VERSION "dbc-export 1 2026.26.6.5"

NS_ :

BS_:

BU_: ADSP APSB CMP DAS EPAS3P GTW OCS1P PTC RCM TCU TCU2 TRCM UDS UI UIS VCLEFT

BO_ 2033 GTW_hrl: 7 GTW
 SG_ GTW_hrlIndex M : 0|2@1+ (1,0) [0|3] "" Vector__XXX
 SG_ GTW_hrlPagesCount m1 : 15|32@0+ (1,0) [0|4294967295] "" Vector__XXX
 SG_ GTW_hrlSdCardSizeGB m1 : 40|8@1+ (1,0) [1|255] "" Vector__XXX
 SG_ GTW_hrlState m2 : 2|1@1+ (1,0) [0|1] "" Vector__XXX
 SG_ GTW_hrlTriggerDuration m2 : 15|16@0+ (1,0) [0|65535] "seconds" Vector__XXX
 SG_ GTW_hrlTriggerType m2 : 24|4@1+ (1,0) [0|15] "" Vector__XXX
 SG_ GTW_hrlTriggerId m2 : 39|16@0+ (1,0) [0|65535] "" Vector__XXX
 SG_ GTW_hrlTriggerBus m2 : 53|3@1+ (1,0) [0|7] "" Vector__XXX

BO_ 2026 GTW_hrlExternalEvent: 8 GTW
 SG_ GTW_hrlEventStartEpoch : 7|32@0+ (1,0) [0|4294967295] "seconds" Vector__XXX
 SG_ GTW_hrlEventEndEpoch : 39|32@0+ (1,0) [0|4294967295] "seconds" Vector__XXX

BO_ 60 GTW_info: 8 GTW
 SG_ GTW_infoIndex M : 0|8@1+ (1,0) [0|255] "" Vector__XXX
 SG_ GTW_buildType m10 : 8|3@1+ (1,0) [0|7] "" Vector__XXX
 SG_ GTW_hardwareId m10 : 32|16@1+ (1,0) [0|65535] "" Vector__XXX
 SG_ GTW_platformType m13 : 8|8@1+ (1,0) [0|255] "" Vector__XXX
 SG_ GTW_appCrc m13 : 32|32@1+ (1,0) [0|4294967295] "" Vector__XXX
 SG_ GTW_applicationGitHash m17 : 8|56@1+ (1,0) [0|7.20575940379e+16] "" Vector__XXX
 SG_ GTW_bootGitHash m18 : 8|56@1+ (1,0) [0|7.20575940379e+16] "" Vector__XXX

BO_ 1370 GTW_mismatchFault: 8 GTW
 SG_ GTW_mismatchFaultIndex M : 0|3@1+ (1,0) [0|7] "" Vector__XXX
 SG_ GTW_mismatchFaultChecksum : 3|8@1+ (1,0) [0|255] "" Vector__XXX
 SG_ GTW_mismatchFaultCounter : 11|4@1+ (1,0) [0|15] "" Vector__XXX
 SG_ GTW_GTWmismatchFault m1 : 15|1@1+ (1,0) [0|1] "" Vector__XXX
 SG_ GTW_BMSmismatchFault m1 : 16|1@1+ (1,0) [0|1] "" Vector__XXX
 SG_ GTW_APSmismatchFault m1 : 17|1@1+ (1,0) [0|1] "" Vector__XXX
 SG_ GTW_BLEEPCENTERmismatchFault m1 : 18|1@1+ (1,0) [0|1] "" Vector__XXX
 SG_ GTW_BLEEPLEFTmismatchFault m1 : 19|1@1+ (1,0) [0|1] "" Vector__XXX
 SG_ GTW_BLEEPREARmismatchFault m1 : 20|1@1+ (1,0) [0|1] "" Vector__XXX
 SG_ GTW_BLEEPRIGHTmismatchFault m1 : 21|1@1+ (1,0) [0|1] "" Vector__XXX
 SG_ GTW_CBCmismatchFault m1 : 22|1@1+ (1,0) [0|1] "" Vector__XXX
 SG_ GTW_CMPmismatchFault m1 : 23|1@1+ (1,0) [0|1] "" Vector__XXX
 SG_ GTW_CPmismatchFault m1 : 24|1@1+ (1,0) [0|1] "" Vector__XXX
 SG_ GTW_DIFmismatchFault m1 : 25|1@1+ (1,0) [0|1] "" Vector__XXX
 SG_ GTW_DIRmismatchFault m1 : 26|1@1+ (1,0) [0|1] "" Vector__XXX
 SG_ GTW_EPAS3PmismatchFault m1 : 27|1@1+ (1,0) [0|1] "" Vector__XXX
 SG_ GTW_EPAS3SmismatchFault m1 : 28|1@1+ (1,0) [0|1] "" Vector__XXX
 SG_ GTW_EPBLmismatchFault m1 : 29|1@1+ (1,0) [0|1] "" Vector__XXX
 SG_ GTW_EPBRmismatchFault m1 : 30|1@1+ (1,0) [0|1] "" Vector__XXX
 SG_ GTW_ESPCALmismatchFault m1 : 31|1@1+ (1,0) [0|1] "" Vector__XXX
 SG_ GTW_ESPmismatchFault m1 : 32|1@1+ (1,0) [0|1] "" Vector__XXX
 SG_ GTW_HCM3LmismatchFault m1 : 33|1@1+ (1,0) [0|1] "" Vector__XXX
 SG_ GTW_HCM3RmismatchFault m1 : 34|1@1+ (1,0) [0|1] "" Vector__XXX
 SG_ GTW_HCMLmismatchFault m1 : 35|1@1+ (1,0) [0|1] "" Vector__XXX
 SG_ GTW_HCMRmismatchFault m1 : 36|1@1+ (1,0) [0|1] "" Vector__XXX
 SG_ GTW_HVPmismatchFault m1 : 37|1@1+ (1,0) [0|1] "" Vector__XXX
 SG_ GTW_IBSTCALmismatchFault m1 : 38|1@1+ (1,0) [0|1] "" Vector__XXX
 SG_ GTW_IBSTmismatchFault m1 : 39|1@1+ (1,0) [0|1] "" Vector__XXX
 SG_ GTW_LVBMSmismatchFault m1 : 40|1@1+ (1,0) [0|1] "" Vector__XXX
 SG_ GTW_OCS1PmismatchFault m1 : 41|1@1+ (1,0) [0|1] "" Vector__XXX
 SG_ GTW_OPCFmismatchFault m1 : 42|1@1+ (1,0) [0|1] "" Vector__XXX
 SG_ GTW_OPCRmismatchFault m1 : 43|1@1+ (1,0) [0|1] "" Vector__XXX
 SG_ GTW_PARKmismatchFault m1 : 44|1@1+ (1,0) [0|1] "" Vector__XXX
 SG_ GTW_PCSCPU2mismatchFault m1 : 45|1@1+ (1,0) [0|1] "" Vector__XXX
 SG_ GTW_PCSmismatchFault m1 : 46|1@1+ (1,0) [0|1] "" Vector__XXX
 SG_ GTW_PMFmismatchFault m1 : 47|1@1+ (1,0) [0|1] "" Vector__XXX
 SG_ GTW_PMRmismatchFault m1 : 48|1@1+ (1,0) [0|1] "" Vector__XXX
 SG_ GTW_PTCmismatchFault m1 : 49|1@1+ (1,0) [0|1] "" Vector__XXX
 SG_ GTW_RCMCALmismatchFault m1 : 50|1@1+ (1,0) [0|1] "" Vector__XXX
 SG_ GTW_RCMmismatchFault m1 : 51|1@1+ (1,0) [0|1] "" Vector__XXX
 SG_ GTW_SCCMmismatchFault m1 : 52|1@1+ (1,0) [0|1] "" Vector__XXX
 SG_ GTW_SDCRmismatchFault m1 : 53|1@1+ (1,0) [0|1] "" Vector__XXX
 SG_ GTW_SWCmismatchFault m1 : 54|1@1+ (1,0) [0|1] "" Vector__XXX
 SG_ GTW_THSmismatchFault m1 : 55|1@1+ (1,0) [0|1] "" Vector__XXX
 SG_ GTW_VCFRONTmismatchFault m1 : 56|1@1+ (1,0) [0|1] "" Vector__XXX
 SG_ GTW_VCLEFTmismatchFault m1 : 57|1@1+ (1,0) [0|1] "" Vector__XXX
 SG_ GTW_VCRIGHTmismatchFault m1 : 58|1@1+ (1,0) [0|1] "" Vector__XXX
 SG_ GTW_VCSECmismatchFault m1 : 59|1@1+ (1,0) [0|1] "" Vector__XXX
 SG_ GTW_PMmismatchFault m1 : 60|1@1+ (1,0) [0|1] "" Vector__XXX

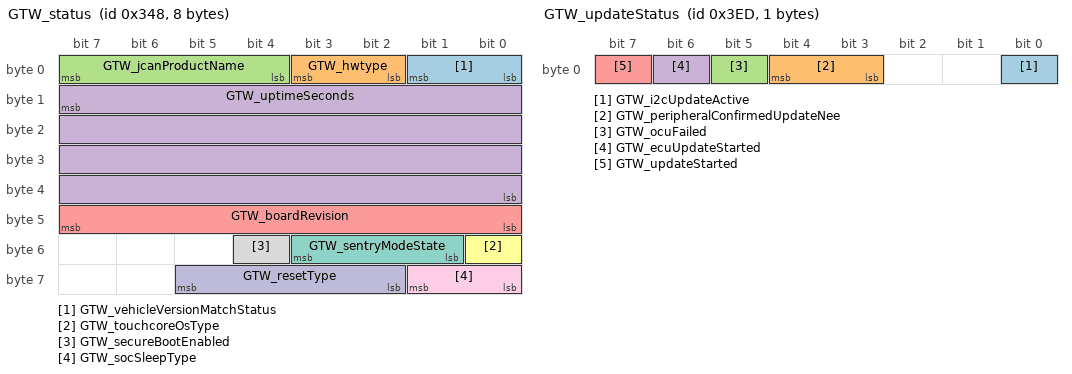
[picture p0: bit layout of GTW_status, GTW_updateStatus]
BO_ 840 GTW_status: 8 GTW
 SG_ GTW_vehicleVersionMatchStatus : 0|2@1+ (1,0) [0|3] "" Vector__XXX
 SG_ GTW_hwtype : 2|2@1+ (1,0) [1|3] "" Vector__XXX
 SG_ GTW_jcanProductName : 4|4@1+ (1,0) [1|15] "" Vector__XXX
 SG_ GTW_uptimeSeconds : 15|32@0+ (1,0) [0|4294967295] "s" Vector__XXX
 SG_ GTW_boardRevision : 40|8@1+ (1,0) [0|255] "" Vector__XXX
 SG_ GTW_touchcoreOsType : 48|1@1+ (1,0) [0|1] "" Vector__XXX
 SG_ GTW_sentryModeState : 49|3@1+ (1,0) [0|7] "" Vector__XXX
 SG_ GTW_secureBootEnabled : 52|1@1+ (1,0) [0|1] "" Vector__XXX
 SG_ GTW_socSleepType : 56|2@1+ (1,0) [1|3] "" Vector__XXX
 SG_ GTW_resetType : 58|4@1+ (1,0) [1|15] "" Vector__XXX

BO_ 1005 GTW_updateStatus: 1 GTW
 SG_ GTW_i2cUpdateActive : 0|1@1+ (1,0) [0|1] "" Vector__XXX
 SG_ GTW_peripheralConfirmedUpdateNee : 3|2@1+ (1,0) [0|3] "" Vector__XXX
 SG_ GTW_ocuFailed : 5|1@1+ (1,0) [0|1] "" Vector__XXX
 SG_ GTW_ecuUpdateStarted : 6|1@1+ (1,0) [0|1] "" Vector__XXX
 SG_ GTW_updateStarted : 7|1@1+ (1,0) [0|1] "" Vector__XXX

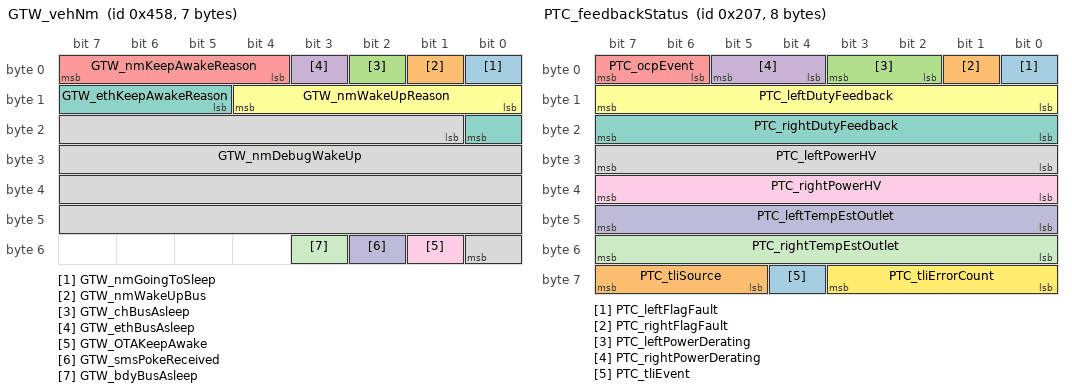
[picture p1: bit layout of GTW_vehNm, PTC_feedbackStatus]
BO_ 1112 GTW_vehNm: 7 GTW
 SG_ GTW_nmGoingToSleep : 0|1@1+ (1,0) [0|1] "" Vector__XXX
 SG_ GTW_nmWakeUpBus : 1|1@1+ (1,0) [0|1] "" Vector__XXX
 SG_ GTW_chBusAsleep : 2|1@1+ (1,0) [0|1] "" Vector__XXX
 SG_ GTW_ethBusAsleep : 3|1@1+ (1,0) [0|1] "" Vector__XXX
 SG_ GTW_nmKeepAwakeReason : 4|4@1+ (1,0) [1|15] "" Vector__XXX
 SG_ GTW_nmWakeUpReason : 8|5@1+ (1,0) [0|31] "" Vector__XXX
 SG_ GTW_ethKeepAwakeReason : 13|4@1+ (1,0) [1|15] "" Vector__XXX
 SG_ GTW_nmDebugWakeUp : 17|32@1+ (1,0) [0|4294967295] "" Vector__XXX
 SG_ GTW_OTAKeepAwake : 49|1@1+ (1,0) [0|1] "" Vector__XXX
 SG_ GTW_smsPokeReceived : 50|1@1+ (1,0) [0|1] "" Vector__XXX
 SG_ GTW_bdyBusAsleep : 51|1@1+ (1,0) [0|1] "" Vector__XXX

BO_ 1429 OCS1P_alertLog: 8 OCS1P
 SG_ OCS1P_alertID M : 0|8@1+ (1,0) [0|255] "" Vector__XXX
 SG_ OCS1P_alertState : 15|1@1+ (1,0) [0|1] "" Vector__XXX
 SG_ OCS1P_a121_sandwichFreq m121 : 16|32@1+ (1,0) [0|4294967295] "" Vector__XXX
 SG_ OCS1P_a122_sandwichFreq m122 : 16|32@1+ (1,0) [0|4294967295] "" Vector__XXX
 SG_ OCS1P_a123_sandwichFreq m123 : 16|32@1+ (1,0) [0|4294967295] "" Vector__XXX
 SG_ OCS1P_a124_cushionSelfFreq m124 : 16|32@1+ (1,0) [0|4294967295] "" Vector__XXX
 SG_ OCS1P_a125_cushionSelfFreq m125 : 16|32@1+ (1,0) [0|4294967295] "" Vector__XXX
 SG_ OCS1P_a126_cushionSelfFreq m126 : 16|32@1+ (1,0) [0|4294967295] "" Vector__XXX
 SG_ OCS1P_a127_seatbackSelfFreq m127 : 16|32@1+ (1,0) [0|4294967295] "" Vector__XXX
 SG_ OCS1P_a128_seatbackSelfFreq m128 : 16|32@1+ (1,0) [0|4294967295] "" Vector__XXX
 SG_ OCS1P_a129_seatbackSelfFreq m129 : 16|32@1+ (1,0) [0|4294967295] "" Vector__XXX
 SG_ OCS1P_a130_sandwichNoCalib m130 : 16|1@1+ (1,0) [0|1] "" Vector__XXX
 SG_ OCS1P_a131_cushionSelfNoCalib m131 : 16|1@1+ (1,0) [0|1] "" Vector__XXX
 SG_ OCS1P_a132_seatbackSelfNoCalib m132 : 16|1@1+ (1,0) [0|1] "" Vector__XXX
 SG_ OCS1P_a133_sandwichBadCalib m133 : 16|1@1+ (1,0) [0|1] "" Vector__XXX
 SG_ OCS1P_a134_uninitializedCalib m134 : 16|1@1+ (1,0) [0|1] "" Vector__XXX
 SG_ OCS1P_a135_tempNoCalib m135 : 16|1@1+ (1,0) [0|1] "" Vector__XXX
 SG_ OCS1P_a140_tempInvalidCalib m140 : 16|1@1+ (1,0) [0|1] "" Vector__XXX
 SG_ OCS1P_a141_humidityInvalidCalib m141 : 16|1@1+ (1,0) [0|1] "" Vector__XXX
 SG_ OCS1P_a142_tempHumidityInvalid m142 : 16|1@1+ (1,0) [0|1] "" Vector__XXX
 SG_ OCS1P_a143_mismatchPassAirbag m143 : 16|1@1+ (1,0) [0|1] "" Vector__XXX
 SG_ OCS1P_a144_mismatchCarRegion m144 : 16|1@1+ (1,0) [0|1] "" Vector__XXX

BO_ 767 OCS1P_alertMatrix: 8 OCS1P
 SG_ OCS1P_matrixIndex M : 0|4@1+ (1,0) [0|15] "" Vector__XXX
 SG_ OCS1P_w015_NVMMAlert m0 : 18|1@1+ (1,0) [0|1] "" Vector__XXX
 SG_ OCS1P_w121_sandwichOpen m2 : 4|1@1+ (1,0) [0|1] "" Vector__XXX
 SG_ OCS1P_w122_sandwichLow m2 : 5|1@1+ (1,0) [0|1] "" Vector__XXX
 SG_ OCS1P_w123_sandwichShort m2 : 6|1@1+ (1,0) [0|1] "" Vector__XXX
 SG_ OCS1P_w124_cushionSelfOpen m2 : 7|1@1+ (1,0) [0|1] "" Vector__XXX
 SG_ OCS1P_w125_cushionSelfLow m2 : 8|1@1+ (1,0) [0|1] "" Vector__XXX
 SG_ OCS1P_w126_cushionSelfShort m2 : 9|1@1+ (1,0) [0|1] "" Vector__XXX
 SG_ OCS1P_w127_seatbackSelfOpen m2 : 10|1@1+ (1,0) [0|1] "" Vector__XXX
 SG_ OCS1P_w128_seatbackSelfLow m2 : 11|1@1+ (1,0) [0|1] "" Vector__XXX
 SG_ OCS1P_w129_seatbackSelfShort m2 : 12|1@1+ (1,0) [0|1] "" Vector__XXX
 SG_ OCS1P_w130_sandwichNoCalib m2 : 13|1@1+ (1,0) [0|1] "" Vector__XXX
 SG_ OCS1P_w131_cushionSelfNoCalib m2 : 14|1@1+ (1,0) [0|1] "" Vector__XXX
 SG_ OCS1P_w132_seatbackSelfNoCalib m2 : 15|1@1+ (1,0) [0|1] "" Vector__XXX
 SG_ OCS1P_w133_sandwichBadCalib m2 : 16|1@1+ (1,0) [0|1] "" Vector__XXX
 SG_ OCS1P_w134_uninitializedCalib m2 : 17|1@1+ (1,0) [0|1] "" Vector__XXX
 SG_ OCS1P_w135_tempNoCalib m2 : 18|1@1+ (1,0) [0|1] "" Vector__XXX
 SG_ OCS1P_w136_cushionSelfDutyLow m2 : 19|1@1+ (1,0) [0|1] "" Vector__XXX
 SG_ OCS1P_w137_cushionSelfDutyHigh m2 : 20|1@1+ (1,0) [0|1] "" Vector__XXX
 SG_ OCS1P_w138_seatbackSelfDutyLow m2 : 21|1@1+ (1,0) [0|1] "" Vector__XXX
 SG_ OCS1P_w139_seatbackSelfDutyHigh m2 : 22|1@1+ (1,0) [0|1] "" Vector__XXX
 SG_ OCS1P_w140_tempInvalidCalib m2 : 23|1@1+ (1,0) [0|1] "" Vector__XXX
 SG_ OCS1P_w141_humidityInvalidCalib m2 : 24|1@1+ (1,0) [0|1] "" Vector__XXX
 SG_ OCS1P_w142_tempHumidityInvalid m2 : 25|1@1+ (1,0) [0|1] "" Vector__XXX
 SG_ OCS1P_w143_mismatchPassAirbag m2 : 26|1@1+ (1,0) [0|1] "" Vector__XXX
 SG_ OCS1P_w144_mismatchCarRegion m2 : 27|1@1+ (1,0) [0|1] "" Vector__XXX
 SG_ OCS1P_w145_rebaselineTriggered m2 : 28|1@1+ (1,0) [0|1] "" Vector__XXX
 SG_ OCS1P_w148_classificationMismatc m2 : 31|1@1+ (1,0) [0|1] "" Vector__XXX
 SG_ OCS1P_w150_rbEntryTriggered m2 : 33|1@1+ (1,0) [0|1] "" Vector__XXX
 SG_ OCS1P_w151_rbEntryExited m2 : 34|1@1+ (1,0) [0|1] "" Vector__XXX
 SG_ OCS1P_w152_rbExit1Triggered m2 : 35|1@1+ (1,0) [0|1] "" Vector__XXX
 SG_ OCS1P_w153_rbExit1Exited m2 : 36|1@1+ (1,0) [0|1] "" Vector__XXX
 SG_ OCS1P_w154_rbExit2Exited1 m2 : 37|1@1+ (1,0) [0|1] "" Vector__XXX
 SG_ OCS1P_w155_rbExit2Exited2 m2 : 38|1@1+ (1,0) [0|1] "" Vector__XXX
 SG_ OCS1P_w156_seatbeltReminderUnava m2 : 39|1@1+ (1,0) [0|1] "" Vector__XXX

BO_ 766 OCS1P_info: 8 OCS1P
 SG_ OCS1P_infoIndex M : 0|8@1+ (1,0) [0|255] "" Vector__XXX
 SG_ OCS1P_infoBuildType m10 : 8|8@1+ (1,0) [0|255] "" Vector__XXX
 SG_ OCS1P_infoBuildConfigID m10 : 16|16@1+ (1,0) [0|65535] "" Vector__XXX
 SG_ OCS1P_infoHardwareID m10 : 32|16@1+ (1,0) [0|65535] "" Vector__XXX
 SG_ OCS1P_infoComponentID m10 : 48|16@1+ (1,0) [0|65535] "" Vector__XXX
 SG_ OCS1P_infoPcbaID m11 : 16|8@1+ (1,0) [0|255] "" Vector__XXX
 SG_ OCS1P_infoAssemblyID m11 : 24|8@1+ (1,0) [0|255] "" Vector__XXX
 SG_ OCS1P_infoUsageID m11 : 32|16@1+ (1,0) [0|65535] "" Vector__XXX
 SG_ OCS1P_infoSubUsageID m11 : 48|16@1+ (1,0) [0|65535] "" Vector__XXX
 SG_ OCS1P_infoApplicationCRC m13 : 32|32@1+ (1,0) [0|4294967295] "" Vector__XXX
 SG_ OCS1P_infoBootSvnRev m14 : 8|24@1+ (1,0) [0|16777215] "" Vector__XXX
 SG_ OCS1P_infoAppGitHashBytes m17 : 8|56@1+ (1,0) [0|7.20575940379e+16] "" Vector__XXX
 SG_ OCS1P_infoBootGitHashBytes m18 : 8|56@1+ (1,0) [0|7.20575940379e+16] "" Vector__XXX
 SG_ OCS1P_infoPlatformType m19 : 8|8@1+ (1,0) [0|255] "" Vector__XXX
 SG_ OCS1P_infoBootUdsProtoVersion m20 : 8|8@1+ (1,0) [0|255] "" Vector__XXX
 SG_ OCS1P_infoBootloaderCRC m20 : 32|32@1+ (1,0) [0|4294967295] "" Vector__XXX

BO_ 771 OCS1P_status: 8 OCS1P
 SG_ OCS1P_occupantClassification : 0|8@1+ (1,0) [0|254] "" Vector__XXX
 SG_ OCS1P_occupantClassificationQF : 8|1@1+ (1,0) [0|1] "" Vector__XXX
 SG_ OCS1P_occupiedState : 9|2@1+ (1,0) [0|2] "" Vector__XXX
 SG_ OCS1P_triggerSnapshot : 11|5@1+ (1,0) [0|31] "" Vector__XXX
 SG_ OCS1P_occupantClassificationRaw : 16|3@1+ (1,0) [0|6] "" Vector__XXX
 SG_ OCS1P_occupantClassificationSelf : 19|3@1+ (1,0) [0|6] "" Vector__XXX
 SG_ OCS1P_occupantClassificationRawC : 22|3@1+ (1,0) [0|6] "" Vector__XXX
 SG_ OCS1P_occupantClassificationCap : 25|3@1+ (1,0) [0|6] "" Vector__XXX
 SG_ OCS1P_classificationHeld : 30|1@1+ (1,0) [0|1] "" Vector__XXX
 SG_ OCS1P_cushionStable : 31|1@1+ (1,0) [0|1] "" Vector__XXX
 SG_ OCS1P_classificationExtHold : 32|1@1+ (1,0) [0|1] "" Vector__XXX
 SG_ OCS1P_classificationHoldState : 33|3@1+ (1,0) [0|7] "" Vector__XXX
 SG_ OCS1P_classificationVariant : 36|3@1+ (1,0) [0|7] "" Vector__XXX
 SG_ OCS1P_sandwichDisabled : 39|1@1+ (1,0) [0|1] "" Vector__XXX
 SG_ OCS1P_noSandwichType : 40|2@1+ (1,0) [0|3] "" Vector__XXX
 SG_ OCS1P_sandwichBoundaryType : 42|1@1+ (1,0) [0|1] "" Vector__XXX
 SG_ OCS1P_sbrBoundaryType : 43|1@1+ (1,0) [0|1] "" Vector__XXX
 SG_ OCS1P_occupiedStateCap : 45|2@1+ (1,0) [0|2] "" Vector__XXX
 SG_ OCS1P_seatbackStable : 47|1@1+ (1,0) [0|1] "" Vector__XXX
 SG_ OCS1P_sandwichStable : 48|1@1+ (1,0) [0|1] "" Vector__XXX
 SG_ OCS1P_cushionStableCap : 49|1@1+ (1,0) [0|1] "" Vector__XXX
 SG_ OCS1P_seatbackStableCap : 50|1@1+ (1,0) [0|1] "" Vector__XXX
 SG_ OCS1P_classificationHeldCap : 51|1@1+ (1,0) [0|1] "" Vector__XXX
 SG_ OCS1P_statusCounter : 52|4@1+ (1,0) [0|15] "" Vector__XXX
 SG_ OCS1P_statusChecksum : 56|8@1+ (1,0) [0|255] "" Vector__XXX

BO_ 1619 OCS1P_udsResponse: 8 OCS1P
 SG_ OCS1P_udsResponseData : 0|64@1+ (1,0) [0|1.84467440737e+19] "" Vector__XXX

BO_ 519 PTC_feedbackStatus: 8 PTC
 SG_ PTC_leftFlagFault : 0|1@1+ (1,0) [0|1] "" Vector__XXX
 SG_ PTC_rightFlagFault : 1|1@1+ (1,0) [0|1] "" Vector__XXX
 SG_ PTC_leftPowerDerating : 2|2@1+ (1,0) [0|3] "" Vector__XXX
 SG_ PTC_rightPowerDerating : 4|2@1+ (1,0) [0|3] "" Vector__XXX
 SG_ PTC_ocpEvent : 6|2@1+ (1,0) [0|3] "" Vector__XXX
 SG_ PTC_leftDutyFeedback : 8|8@1+ (0.5,0) [0|100] "%" Vector__XXX
 SG_ PTC_rightDutyFeedback : 16|8@1+ (0.5,0) [0|100] "%" Vector__XXX
 SG_ PTC_leftPowerHV : 24|8@1+ (30,0) [0|7650] "W" Vector__XXX
 SG_ PTC_rightPowerHV : 32|8@1+ (30,0) [0|7650] "W" Vector__XXX
 SG_ PTC_leftTempEstOutlet : 40|8@1+ (1,-40) [-40|200] "degC" Vector__XXX
 SG_ PTC_rightTempEstOutlet : 48|8@1+ (1,-40) [-40|200] "degC" Vector__XXX
 SG_ PTC_tliErrorCount : 56|4@1+ (1,0) [0|15] "" Vector__XXX
 SG_ PTC_tliEvent : 60|1@1+ (1,0) [0|1] "" Vector__XXX
 SG_ PTC_tliSource : 61|3@1+ (1,0) [0|7] "" Vector__XXX

BO_ 1297 RCM_alertLog: 8 RCM
 SG_ RCM_alertID M : 0|10@1+ (1,0) [0|1023] "" Vector__XXX
 SG_ RCM_alertState : 10|1@1+ (1,0) [0|1] "" Vector__XXX
 SG_ RCM_a000_eventArmStatus m0 : 11|1@1+ (1,0) [0|1] "" Vector__XXX
 SG_ RCM_a000_eventFactoryMode m0 : 12|1@1+ (1,0) [0|1] "" Vector__XXX
 SG_ RCM_a000_eventDiagEnabled m0 : 13|1@1+ (1,0) [0|1] "" Vector__XXX
 SG_ RCM_a000_eventDriveOrientation m0 : 14|1@1+ (1,0) [0|1] "" Vector__XXX
 SG_ RCM_a000_crashDetectedFront m0 : 16|1@1+ (1,0) [0|1] "" Vector__XXX
 SG_ RCM_a000_crashDetectedRear m0 : 17|1@1+ (1,0) [0|1] "" Vector__XXX
 SG_ RCM_a000_crashDetectedLeft m0 : 18|1@1+ (1,0) [0|1] "" Vector__XXX
 SG_ RCM_a000_crashDetectedRight m0 : 19|1@1+ (1,0) [0|1] "" Vector__XXX
 SG_ RCM_a000_crashDetectedRoll m0 : 20|1@1+ (1,0) [0|1] "" Vector__XXX
 SG_ RCM_a000_crashDetectedPreten m0 : 21|1@1+ (1,0) [0|1] "" Vector__XXX
 SG_ RCM_a000_crashDetectedStage1 m0 : 22|1@1+ (1,0) [0|1] "" Vector__XXX
 SG_ RCM_a000_crashDetectedStage2 m0 : 23|1@1+ (1,0) [0|1] "" Vector__XXX
 SG_ RCM_a000_crashDetectedHVpyro m0 : 24|1@1+ (1,0) [0|1] "" Vector__XXX
 SG_ RCM_a000_eventIDFsignal m0 : 25|1@1+ (1,0) [0|1] "" Vector__XXX
 SG_ RCM_a000_eventFrontLeftSeatbelt m0 : 26|1@1+ (1,0) [0|1] "" Vector__XXX
 SG_ RCM_a000_eventFrontRightSeatbelt m0 : 27|1@1+ (1,0) [0|1] "" Vector__XXX
 SG_ RCM_a000_eventVehicleSpeed m0 : 28|12@1+ (0.08,-40) [-40|287.6] "kph" Vector__XXX
 SG_ RCM_a000_eventSteeringAngle m0 : 45|14@0+ (0.1,-819.2) [-819.2|819.1] "deg" Vector__XXX
 SG_ RCM_a000_eventDriverBrakeApply m0 : 46|2@1+ (1,0) [0|3] "" Vector__XXX
 SG_ RCM_a000_eventAccelPedalPos m0 : 56|8@1+ (0.4,0) [0|102] "%" Vector__XXX
 SG_ RCM_a001_eventArmStatus m1 : 11|1@1+ (1,0) [0|1] "" Vector__XXX
 SG_ RCM_a001_eventFactoryMode m1 : 12|1@1+ (1,0) [0|1] "" Vector__XXX
 SG_ RCM_a001_eventDiagEnabled m1 : 13|1@1+ (1,0) [0|1] "" Vector__XXX
 SG_ RCM_a001_eventDriveOrientation m1 : 14|1@1+ (1,0) [0|1] "" Vector__XXX
 SG_ RCM_a001_nearDeployFront m1 : 16|1@1+ (1,0) [0|1] "" Vector__XXX
 SG_ RCM_a001_nearDeployRear m1 : 17|1@1+ (1,0) [0|1] "" Vector__XXX
 SG_ RCM_a001_nearDeployLeft m1 : 18|1@1+ (1,0) [0|1] "" Vector__XXX
 SG_ RCM_a001_nearDeployRight m1 : 19|1@1+ (1,0) [0|1] "" Vector__XXX
 SG_ RCM_a001_nearDeployRoll m1 : 20|1@1+ (1,0) [0|1] "" Vector__XXX
 SG_ RCM_a001_nearDeployPretensioner m1 : 21|1@1+ (1,0) [0|1] "" Vector__XXX
 SG_ RCM_a001_eventIDFsignal m1 : 25|1@1+ (1,0) [0|1] "" Vector__XXX
 SG_ RCM_a001_eventFrontLeftSeatbelt m1 : 26|1@1+ (1,0) [0|1] "" Vector__XXX
 SG_ RCM_a001_eventFrontRightSeatbelt m1 : 27|1@1+ (1,0) [0|1] "" Vector__XXX
 SG_ RCM_a001_eventVehicleSpeed m1 : 28|12@1+ (0.08,-40) [-40|287.6] "kph" Vector__XXX
 SG_ RCM_a001_eventSteeringAngle m1 : 45|14@0+ (0.1,-819.2) [-819.2|819.1] "deg" Vector__XXX
 SG_ RCM_a001_eventDriverBrakeApply m1 : 46|2@1+ (1,0) [0|2] "" Vector__XXX
 SG_ RCM_a001_eventAccelPedalPos m1 : 56|8@1+ (0.4,0) [0|101.6] "%" Vector__XXX
 SG_ RCM_a002_eventArmStatus m2 : 11|1@1+ (1,0) [0|1] "" Vector__XXX
 SG_ RCM_a002_eventFactoryMode m2 : 12|1@1+ (1,0) [0|1] "" Vector__XXX
 SG_ RCM_a002_eventDiagEnabled m2 : 13|1@1+ (1,0) [0|1] "" Vector__XXX
 SG_ RCM_a002_eventDriveOrientation m2 : 14|1@1+ (1,0) [0|1] "" Vector__XXX
 SG_ RCM_a002_airbagsUnArmed m2 : 16|1@1+ (1,0) [0|1] "" Vector__XXX
 SG_ RCM_a002_eventIDFsignal m2 : 25|1@1+ (1,0) [0|1] "" Vector__XXX
 SG_ RCM_a002_eventFrontLeftSeatbelt m2 : 26|1@1+ (1,0) [0|1] "" Vector__XXX
 SG_ RCM_a002_eventFrontRightSeatbelt m2 : 27|1@1+ (1,0) [0|1] "" Vector__XXX
 SG_ RCM_a002_eventVehicleSpeed m2 : 28|12@1+ (0.08,-40) [-40|287.6] "kph" Vector__XXX
 SG_ RCM_a002_eventSteeringAngle m2 : 45|14@0+ (0.1,-819.2) [-819.2|819.1] "deg" Vector__XXX
 SG_ RCM_a002_eventDriverBrakeApply m2 : 46|2@1+ (1,0) [0|2] "" Vector__XXX
 SG_ RCM_a002_eventAccelPedalPos m2 : 56|8@1+ (0.4,0) [0|101.6] "%" Vector__XXX
 SG_ RCM_a003_eventArmStatus m3 : 11|1@1+ (1,0) [0|1] "" Vector__XXX
 SG_ RCM_a003_eventFactoryMode m3 : 12|1@1+ (1,0) [0|1] "" Vector__XXX
 SG_ RCM_a003_eventDiagEnabled m3 : 13|1@1+ (1,0) [0|1] "" Vector__XXX
 SG_ RCM_a003_eventDriveOrientation m3 : 14|1@1+ (1,0) [0|1] "" Vector__XXX
 SG_ RCM_a003_warningIndicatorOn m3 : 16|1@1+ (1,0) [0|1] "" Vector__XXX
 SG_ RCM_a003_eventIDFsignal m3 : 25|1@1+ (1,0) [0|1] "" Vector__XXX
 SG_ RCM_a003_eventFrontLeftSeatbelt m3 : 26|1@1+ (1,0) [0|1] "" Vector__XXX
 SG_ RCM_a003_eventFrontRightSeatbelt m3 : 27|1@1+ (1,0) [0|1] "" Vector__XXX
 SG_ RCM_a003_eventVehicleSpeed m3 : 28|12@1+ (0.08,-40) [-40|287.6] "kph" Vector__XXX
 SG_ RCM_a003_eventSteeringAngle m3 : 45|14@0+ (0.1,-819.2) [-819.2|819.1] "deg" Vector__XXX
 SG_ RCM_a003_eventDriverBrakeApply m3 : 46|2@1+ (1,0) [0|2] "" Vector__XXX
 SG_ RCM_a003_eventAccelPedalPos m3 : 56|8@1+ (0.4,0) [0|101.6] "%" Vector__XXX
 SG_ RCM_a004_eventArmStatus m4 : 11|1@1+ (1,0) [0|1] "" Vector__XXX
 SG_ RCM_a004_eventFactoryMode m4 : 12|1@1+ (1,0) [0|1] "" Vector__XXX
 SG_ RCM_a004_eventDiagEnabled m4 : 13|1@1+ (1,0) [0|1] "" Vector__XXX
 SG_ RCM_a004_eventDriveOrientation m4 : 14|1@1+ (1,0) [0|1] "" Vector__XXX
 SG_ RCM_a004_frontAlgoDisabled m4 : 16|1@1+ (1,0) [0|1] "" Vector__XXX
 SG_ RCM_a004_sideAlgoDisabled m4 : 17|1@1+ (1,0) [0|1] "" Vector__XXX
 SG_ RCM_a004_rollAlgoDisabled m4 : 18|1@1+ (1,0) [0|1] "" Vector__XXX
 SG_ RCM_a004_idleMode m4 : 19|1@1+ (1,0) [0|1] "" Vector__XXX
 SG_ RCM_a004_internalFaultDetected m4 : 20|1@1+ (1,0) [0|1] "" Vector__XXX
 SG_ RCM_a004_swVersionMismatch m4 : 21|1@1+ (1,0) [0|1] "" Vector__XXX
 SG_ RCM_a004_paramLayoutIDInv m4 : 22|1@1+ (1,0) [0|1] "" Vector__XXX
 SG_ RCM_a004_algoPASIDMismatch m4 : 23|1@1+ (1,0) [0|1] "" Vector__XXX
 SG_ RCM_a004_eventIDFsignal m4 : 25|1@1+ (1,0) [0|1] "" Vector__XXX
 SG_ RCM_a004_eventFrontLeftSeatbelt m4 : 26|1@1+ (1,0) [0|1] "" Vector__XXX
 SG_ RCM_a004_eventFrontRightSeatbelt m4 : 27|1@1+ (1,0) [0|1] "" Vector__XXX
 SG_ RCM_a004_eventVehicleSpeed m4 : 28|12@1+ (0.08,-40) [-40|287.6] "kph" Vector__XXX
 SG_ RCM_a004_eventSteeringAngle m4 : 45|14@0+ (0.1,-819.2) [-819.2|819.1] "deg" Vector__XXX
 SG_ RCM_a004_eventDriverBrakeApply m4 : 46|2@1+ (1,0) [0|2] "" Vector__XXX
 SG_ RCM_a004_eventAccelPedalPos m4 : 56|8@1+ (0.4,0) [0|101.6] "%" Vector__XXX
 SG_ RCM_a005_eventArmStatus m5 : 11|1@1+ (1,0) [0|1] "" Vector__XXX
 SG_ RCM_a005_eventFactoryMode m5 : 12|1@1+ (1,0) [0|1] "" Vector__XXX
 SG_ RCM_a005_eventDiagEnabled m5 : 13|1@1+ (1,0) [0|1] "" Vector__XXX
 SG_ RCM_a005_eventDriveOrientation m5 : 14|1@1+ (1,0) [0|1] "" Vector__XXX
 SG_ RCM_a005_externalCRCError m5 : 16|1@1+ (1,0) [0|1] "" Vector__XXX
 SG_ RCM_a005_eventIDFsignal m5 : 25|1@1+ (1,0) [0|1] "" Vector__XXX
 SG_ RCM_a005_eventFrontLeftSeatbelt m5 : 26|1@1+ (1,0) [0|1] "" Vector__XXX
 SG_ RCM_a005_eventFrontRightSeatbelt m5 : 27|1@1+ (1,0) [0|1] "" Vector__XXX
 SG_ RCM_a005_eventVehicleSpeed m5 : 28|12@1+ (0.08,-40) [-40|287.6] "kph" Vector__XXX
 SG_ RCM_a005_eventSteeringAngle m5 : 45|14@0+ (0.1,-819.2) [-819.2|819.1] "deg" Vector__XXX
 SG_ RCM_a005_eventDriverBrakeApply m5 : 46|2@1+ (1,0) [0|2] "" Vector__XXX
 SG_ RCM_a005_eventAccelPedalPos m5 : 56|8@1+ (0.4,0) [0|101.6] "%" Vector__XXX
 SG_ RCM_a006_eventArmStatus m6 : 11|1@1+ (1,0) [0|1] "" Vector__XXX
 SG_ RCM_a006_eventFactoryMode m6 : 12|1@1+ (1,0) [0|1] "" Vector__XXX
 SG_ RCM_a006_eventDiagEnabled m6 : 13|1@1+ (1,0) [0|1] "" Vector__XXX
 SG_ RCM_a006_eventDriveOrientation m6 : 14|1@1+ (1,0) [0|1] "" Vector__XXX
 SG_ RCM_a006_batteryVoltageTooHigh m6 : 16|1@1+ (1,0) [0|1] "" Vector__XXX
 SG_ RCM_a006_batteryVoltageTooLow m6 : 17|1@1+ (1,0) [0|1] "" Vector__XXX
 SG_ RCM_a006_eventIDFsignal m6 : 25|1@1+ (1,0) [0|1] "" Vector__XXX
 SG_ RCM_a006_eventFrontLeftSeatbelt m6 : 26|1@1+ (1,0) [0|1] "" Vector__XXX
 SG_ RCM_a006_eventFrontRightSeatbelt m6 : 27|1@1+ (1,0) [0|1] "" Vector__XXX
 SG_ RCM_a006_eventVehicleSpeed m6 : 28|12@1+ (0.08,-40) [-40|287.6] "kph" Vector__XXX
 SG_ RCM_a006_eventSteeringAngle m6 : 45|14@0+ (0.1,-819.2) [-819.2|819.1] "deg" Vector__XXX
 SG_ RCM_a006_eventDriverBrakeApply m6 : 46|2@1+ (1,0) [0|2] "" Vector__XXX
 SG_ RCM_a006_eventAccelPedalPos m6 : 56|8@1+ (0.4,0) [0|101.6] "%" Vector__XXX
 SG_ RCM_a008_eventArmStatus m8 : 11|1@1+ (1,0) [0|1] "" Vector__XXX
 SG_ RCM_a008_eventFactoryMode m8 : 12|1@1+ (1,0) [0|1] "" Vector__XXX
 SG_ RCM_a008_eventDiagEnabled m8 : 13|1@1+ (1,0) [0|1] "" Vector__XXX
 SG_ RCM_a008_eventDriveOrientation m8 : 14|1@1+ (1,0) [0|1] "" Vector__XXX
 SG_ RCM_a008_lossOfMainPwrSupMonit m8 : 16|1@1+ (1,0) [0|1] "" Vector__XXX
 SG_ RCM_a008_lossOfBckupPwrSupMonit m8 : 17|1@1+ (1,0) [0|1] "" Vector__XXX
 SG_ RCM_a008_normalShtdwnUnavail m8 : 18|1@1+ (1,0) [0|1] "" Vector__XXX
 SG_ RCM_a008_eventIDFsignal m8 : 25|1@1+ (1,0) [0|1] "" Vector__XXX
 SG_ RCM_a008_eventFrontLeftSeatbelt m8 : 26|1@1+ (1,0) [0|1] "" Vector__XXX
 SG_ RCM_a008_eventFrontRightSeatbelt m8 : 27|1@1+ (1,0) [0|1] "" Vector__XXX
 SG_ RCM_a008_eventVehicleSpeed m8 : 28|12@1+ (0.08,-40) [-40|287.6] "kph" Vector__XXX
 SG_ RCM_a008_eventSteeringAngle m8 : 45|14@0+ (0.1,-819.2) [-819.2|819.1] "deg" Vector__XXX
 SG_ RCM_a008_eventDriverBrakeApply m8 : 46|2@1+ (1,0) [0|2] "" Vector__XXX
 SG_ RCM_a008_eventAccelPedalPos m8 : 56|8@1+ (0.4,0) [0|101.6] "%" Vector__XXX
 SG_ RCM_a009_eventArmStatus m9 : 11|1@1+ (1,0) [0|1] "" Vector__XXX
 SG_ RCM_a009_eventFactoryMode m9 : 12|1@1+ (1,0) [0|1] "" Vector__XXX
 SG_ RCM_a009_eventDiagEnabled m9 : 13|1@1+ (1,0) [0|1] "" Vector__XXX
 SG_ RCM_a009_eventDriveOrientation m9 : 14|1@1+ (1,0) [0|1] "" Vector__XXX
 SG_ RCM_a009_reprogramLimitExceeded m9 : 16|1@1+ (1,0) [0|1] "" Vector__XXX
 SG_ RCM_a009_eventIDFsignal m9 : 25|1@1+ (1,0) [0|1] "" Vector__XXX
 SG_ RCM_a009_eventFrontLeftSeatbelt m9 : 26|1@1+ (1,0) [0|1] "" Vector__XXX
 SG_ RCM_a009_eventFrontRightSeatbelt m9 : 27|1@1+ (1,0) [0|1] "" Vector__XXX
 SG_ RCM_a009_eventVehicleSpeed m9 : 28|12@1+ (0.08,-40) [-40|287.6] "kph" Vector__XXX
 SG_ RCM_a009_eventSteeringAngle m9 : 45|14@0+ (0.1,-819.2) [-819.2|819.1] "deg" Vector__XXX
 SG_ RCM_a009_eventDriverBrakeApply m9 : 46|2@1+ (1,0) [0|2] "" Vector__XXX
 SG_ RCM_a009_eventAccelPedalPos m9 : 56|8@1+ (0.4,0) [0|101.6] "%" Vector__XXX
 SG_ RCM_a011_eventArmStatus m11 : 11|1@1+ (1,0) [0|1] "" Vector__XXX
 SG_ RCM_a011_eventFactoryMode m11 : 12|1@1+ (1,0) [0|1] "" Vector__XXX
 SG_ RCM_a011_eventDiagEnabled m11 : 13|1@1+ (1,0) [0|1] "" Vector__XXX
 SG_ RCM_a011_eventDriveOrientation m11 : 14|1@1+ (1,0) [0|1] "" Vector__XXX
 SG_ RCM_a011_edrDataAreaLocked m11 : 16|1@1+ (1,0) [0|1] "" Vector__XXX
 SG_ RCM_a011_eventIDFsignal m11 : 25|1@1+ (1,0) [0|1] "" Vector__XXX
 SG_ RCM_a011_eventFrontLeftSeatbelt m11 : 26|1@1+ (1,0) [0|1] "" Vector__XXX
 SG_ RCM_a011_eventFrontRightSeatbelt m11 : 27|1@1+ (1,0) [0|1] "" Vector__XXX
 SG_ RCM_a011_eventVehicleSpeed m11 : 28|12@1+ (0.08,-40) [-40|287.6] "kph" Vector__XXX
 SG_ RCM_a011_eventSteeringAngle m11 : 45|14@0+ (0.1,-819.2) [-819.2|819.1] "deg" Vector__XXX
 SG_ RCM_a011_eventDriverBrakeApply m11 : 46|2@1+ (1,0) [0|2] "" Vector__XXX
 SG_ RCM_a011_eventAccelPedalPos m11 : 56|8@1+ (0.4,0) [0|101.6] "%" Vector__XXX
 SG_ RCM_a012_eventArmStatus m12 : 11|1@1+ (1,0) [0|1] "" Vector__XXX
 SG_ RCM_a012_eventFactoryMode m12 : 12|1@1+ (1,0) [0|1] "" Vector__XXX
 SG_ RCM_a012_eventDiagEnabled m12 : 13|1@1+ (1,0) [0|1] "" Vector__XXX
 SG_ RCM_a012_eventDriveOrientation m12 : 14|1@1+ (1,0) [0|1] "" Vector__XXX
 SG_ RCM_a012_vinMismatch m12 : 16|1@1+ (1,0) [0|1] "" Vector__XXX
 SG_ RCM_a012_vinNotProgrammed m12 : 17|1@1+ (1,0) [0|1] "" Vector__XXX
 SG_ RCM_a012_eventIDFsignal m12 : 25|1@1+ (1,0) [0|1] "" Vector__XXX
 SG_ RCM_a012_eventFrontLeftSeatbelt m12 : 26|1@1+ (1,0) [0|1] "" Vector__XXX
 SG_ RCM_a012_eventFrontRightSeatbelt m12 : 27|1@1+ (1,0) [0|1] "" Vector__XXX
 SG_ RCM_a012_eventVehicleSpeed m12 : 28|12@1+ (0.08,-40) [-40|287.6] "kph" Vector__XXX
 SG_ RCM_a012_eventSteeringAngle m12 : 45|14@0+ (0.1,-819.2) [-819.2|819.1] "deg" Vector__XXX
 SG_ RCM_a012_eventDriverBrakeApply m12 : 46|2@1+ (1,0) [0|2] "" Vector__XXX
 SG_ RCM_a012_eventAccelPedalPos m12 : 56|8@1+ (0.4,0) [0|101.6] "%" Vector__XXX
 SG_ RCM_a013_eventArmStatus m13 : 11|1@1+ (1,0) [0|1] "" Vector__XXX
 SG_ RCM_a013_eventFactoryMode m13 : 12|1@1+ (1,0) [0|1] "" Vector__XXX
 SG_ RCM_a013_eventDiagEnabled m13 : 13|1@1+ (1,0) [0|1] "" Vector__XXX
 SG_ RCM_a013_eventDriveOrientation m13 : 14|1@1+ (1,0) [0|1] "" Vector__XXX
 SG_ RCM_a013_driveOrientiInitNotDone m13 : 16|1@1+ (1,0) [0|1] "" Vector__XXX
 SG_ RCM_a013_driveOrientPlausiCheck m13 : 17|1@1+ (1,0) [0|1] "" Vector__XXX
 SG_ RCM_a013_eventIDFsignal m13 : 25|1@1+ (1,0) [0|1] "" Vector__XXX
 SG_ RCM_a013_eventFrontLeftSeatbelt m13 : 26|1@1+ (1,0) [0|1] "" Vector__XXX
 SG_ RCM_a013_eventFrontRightSeatbelt m13 : 27|1@1+ (1,0) [0|1] "" Vector__XXX
 SG_ RCM_a013_eventVehicleSpeed m13 : 28|12@1+ (0.08,-40) [-40|287.6] "kph" Vector__XXX
 SG_ RCM_a013_eventSteeringAngle m13 : 45|14@0+ (0.1,-819.2) [-819.2|819.1] "deg" Vector__XXX
 SG_ RCM_a013_eventDriverBrakeApply m13 : 46|2@1+ (1,0) [0|2] "" Vector__XXX
 SG_ RCM_a013_eventAccelPedalPos m13 : 56|8@1+ (0.4,0) [0|101.6] "%" Vector__XXX
 SG_ RCM_a014_eventArmStatus m14 : 11|1@1+ (1,0) [0|1] "" Vector__XXX
 SG_ RCM_a014_eventFactoryMode m14 : 12|1@1+ (1,0) [0|1] "" Vector__XXX
 SG_ RCM_a014_eventDiagEnabled m14 : 13|1@1+ (1,0) [0|1] "" Vector__XXX
 SG_ RCM_a014_eventDriveOrientation m14 : 14|1@1+ (1,0) [0|1] "" Vector__XXX
 SG_ RCM_a014_driverABStg1Sht2Gnd m14 : 16|1@1+ (1,0) [0|1] "" Vector__XXX
 SG_ RCM_a014_driverABStg1Sht2Bat m14 : 17|1@1+ (1,0) [0|1] "" Vector__XXX
 SG_ RCM_a014_driverABStg1Open m14 : 18|1@1+ (1,0) [0|1] "" Vector__XXX
 SG_ RCM_a014_driverABStg1Short m14 : 19|1@1+ (1,0) [0|1] "" Vector__XXX
 SG_ RCM_a014_driverABStg1CrossCoup m14 : 20|1@1+ (1,0) [0|1] "" Vector__XXX
 SG_ RCM_a014_driverABStg1Config m14 : 21|1@1+ (1,0) [0|1] "" Vector__XXX
 SG_ RCM_a014_eventIDFsignal m14 : 25|1@1+ (1,0) [0|1] "" Vector__XXX
 SG_ RCM_a014_eventFrontLeftSeatbelt m14 : 26|1@1+ (1,0) [0|1] "" Vector__XXX
 SG_ RCM_a014_eventFrontRightSeatbelt m14 : 27|1@1+ (1,0) [0|1] "" Vector__XXX
 SG_ RCM_a014_eventVehicleSpeed m14 : 28|12@1+ (0.08,-40) [-40|287.6] "kph" Vector__XXX
 SG_ RCM_a014_eventSteeringAngle m14 : 45|14@0+ (0.1,-819.2) [-819.2|819.1] "deg" Vector__XXX
 SG_ RCM_a014_eventDriverBrakeApply m14 : 46|2@1+ (1,0) [0|2] "" Vector__XXX
 SG_ RCM_a014_eventAccelPedalPos m14 : 56|8@1+ (0.4,0) [0|101.6] "%" Vector__XXX
 SG_ RCM_a015_eventArmStatus m15 : 11|1@1+ (1,0) [0|1] "" Vector__XXX
 SG_ RCM_a015_eventFactoryMode m15 : 12|1@1+ (1,0) [0|1] "" Vector__XXX
 SG_ RCM_a015_eventDiagEnabled m15 : 13|1@1+ (1,0) [0|1] "" Vector__XXX
 SG_ RCM_a015_eventDriveOrientation m15 : 14|1@1+ (1,0) [0|1] "" Vector__XXX
 SG_ RCM_a015_driverABStg2Sht2Gnd m15 : 16|1@1+ (1,0) [0|1] "" Vector__XXX
 SG_ RCM_a015_driverABStg2Sht2Bat m15 : 17|1@1+ (1,0) [0|1] "" Vector__XXX
 SG_ RCM_a015_driverABStg2Open m15 : 18|1@1+ (1,0) [0|1] "" Vector__XXX
 SG_ RCM_a015_driverABStg2Short m15 : 19|1@1+ (1,0) [0|1] "" Vector__XXX
 SG_ RCM_a015_driverABStg2CrossCoup m15 : 20|1@1+ (1,0) [0|1] "" Vector__XXX
 SG_ RCM_a015_driverABStg2Config m15 : 21|1@1+ (1,0) [0|1] "" Vector__XXX
 SG_ RCM_a015_eventIDFsignal m15 : 25|1@1+ (1,0) [0|1] "" Vector__XXX
 SG_ RCM_a015_eventFrontLeftSeatbelt m15 : 26|1@1+ (1,0) [0|1] "" Vector__XXX
 SG_ RCM_a015_eventFrontRightSeatbelt m15 : 27|1@1+ (1,0) [0|1] "" Vector__XXX
 SG_ RCM_a015_eventVehicleSpeed m15 : 28|12@1+ (0.08,-40) [-40|287.6] "kph" Vector__XXX
 SG_ RCM_a015_eventSteeringAngle m15 : 45|14@0+ (0.1,-819.2) [-819.2|819.1] "deg" Vector__XXX
 SG_ RCM_a015_eventDriverBrakeApply m15 : 46|2@1+ (1,0) [0|2] "" Vector__XXX
 SG_ RCM_a015_eventAccelPedalPos m15 : 56|8@1+ (0.4,0) [0|101.6] "%" Vector__XXX
 SG_ RCM_a016_eventArmStatus m16 : 11|1@1+ (1,0) [0|1] "" Vector__XXX
 SG_ RCM_a016_eventFactoryMode m16 : 12|1@1+ (1,0) [0|1] "" Vector__XXX
 SG_ RCM_a016_eventDiagEnabled m16 : 13|1@1+ (1,0) [0|1] "" Vector__XXX
 SG_ RCM_a016_eventDriveOrientation m16 : 14|1@1+ (1,0) [0|1] "" Vector__XXX
 SG_ RCM_a016_passABStg1Sht2Gnd m16 : 16|1@1+ (1,0) [0|1] "" Vector__XXX
 SG_ RCM_a016_passABStg1Sht2Bat m16 : 17|1@1+ (1,0) [0|1] "" Vector__XXX
 SG_ RCM_a016_passABStg1Open m16 : 18|1@1+ (1,0) [0|1] "" Vector__XXX
 SG_ RCM_a016_passABStg1Short m16 : 19|1@1+ (1,0) [0|1] "" Vector__XXX
 SG_ RCM_a016_passABStg1CrossCoup m16 : 20|1@1+ (1,0) [0|1] "" Vector__XXX
 SG_ RCM_a016_passABStg1Config m16 : 21|1@1+ (1,0) [0|1] "" Vector__XXX
 SG_ RCM_a016_eventIDFsignal m16 : 25|1@1+ (1,0) [0|1] "" Vector__XXX
 SG_ RCM_a016_eventFrontLeftSeatbelt m16 : 26|1@1+ (1,0) [0|1] "" Vector__XXX
 SG_ RCM_a016_eventFrontRightSeatbelt m16 : 27|1@1+ (1,0) [0|1] "" Vector__XXX
 SG_ RCM_a016_eventVehicleSpeed m16 : 28|12@1+ (0.08,-40) [-40|287.6] "kph" Vector__XXX
 SG_ RCM_a016_eventSteeringAngle m16 : 45|14@0+ (0.1,-819.2) [-819.2|819.1] "deg" Vector__XXX
 SG_ RCM_a016_eventDriverBrakeApply m16 : 46|2@1+ (1,0) [0|2] "" Vector__XXX
 SG_ RCM_a016_eventAccelPedalPos m16 : 56|8@1+ (0.4,0) [0|101.6] "%" Vector__XXX
 SG_ RCM_a017_eventArmStatus m17 : 11|1@1+ (1,0) [0|1] "" Vector__XXX
 SG_ RCM_a017_eventFactoryMode m17 : 12|1@1+ (1,0) [0|1] "" Vector__XXX
 SG_ RCM_a017_eventDiagEnabled m17 : 13|1@1+ (1,0) [0|1] "" Vector__XXX
 SG_ RCM_a017_eventDriveOrientation m17 : 14|1@1+ (1,0) [0|1] "" Vector__XXX
 SG_ RCM_a017_passABStg2Sht2Gnd m17 : 16|1@1+ (1,0) [0|1] "" Vector__XXX
 SG_ RCM_a017_passABStg2Sht2Bat m17 : 17|1@1+ (1,0) [0|1] "" Vector__XXX
 SG_ RCM_a017_passABStg2Open m17 : 18|1@1+ (1,0) [0|1] "" Vector__XXX
 SG_ RCM_a017_passABStg2Short m17 : 19|1@1+ (1,0) [0|1] "" Vector__XXX
 SG_ RCM_a017_passABStg2CrossCoup m17 : 20|1@1+ (1,0) [0|1] "" Vector__XXX
 SG_ RCM_a017_passABStg2Config m17 : 21|1@1+ (1,0) [0|1] "" Vector__XXX
 SG_ RCM_a017_eventIDFsignal m17 : 25|1@1+ (1,0) [0|1] "" Vector__XXX
 SG_ RCM_a017_eventFrontLeftSeatbelt m17 : 26|1@1+ (1,0) [0|1] "" Vector__XXX
 SG_ RCM_a017_eventFrontRightSeatbelt m17 : 27|1@1+ (1,0) [0|1] "" Vector__XXX
 SG_ RCM_a017_eventVehicleSpeed m17 : 28|12@1+ (0.08,-40) [-40|287.6] "kph" Vector__XXX
 SG_ RCM_a017_eventSteeringAngle m17 : 45|14@0+ (0.1,-819.2) [-819.2|819.1] "deg" Vector__XXX
 SG_ RCM_a017_eventDriverBrakeApply m17 : 46|2@1+ (1,0) [0|2] "" Vector__XXX
 SG_ RCM_a017_eventAccelPedalPos m17 : 56|8@1+ (0.4,0) [0|101.6] "%" Vector__XXX
 SG_ RCM_a018_eventArmStatus m18 : 11|1@1+ (1,0) [0|1] "" Vector__XXX
 SG_ RCM_a018_eventFactoryMode m18 : 12|1@1+ (1,0) [0|1] "" Vector__XXX
 SG_ RCM_a018_eventDiagEnabled m18 : 13|1@1+ (1,0) [0|1] "" Vector__XXX
 SG_ RCM_a018_eventDriveOrientation m18 : 14|1@1+ (1,0) [0|1] "" Vector__XXX
 SG_ RCM_a018_passActiveVentSht2Gnd m18 : 16|1@1+ (1,0) [0|1] "" Vector__XXX
 SG_ RCM_a018_passActiveVentSht2Bat m18 : 17|1@1+ (1,0) [0|1] "" Vector__XXX
 SG_ RCM_a018_passActiveVentOpen m18 : 18|1@1+ (1,0) [0|1] "" Vector__XXX
 SG_ RCM_a018_passActiveVentShort m18 : 19|1@1+ (1,0) [0|1] "" Vector__XXX
 SG_ RCM_a018_passActiveVentCrossCoup m18 : 20|1@1+ (1,0) [0|1] "" Vector__XXX
 SG_ RCM_a018_passActiveVentConfig m18 : 21|1@1+ (1,0) [0|1] "" Vector__XXX
 SG_ RCM_a018_eventIDFsignal m18 : 25|1@1+ (1,0) [0|1] "" Vector__XXX
 SG_ RCM_a018_eventFrontLeftSeatbelt m18 : 26|1@1+ (1,0) [0|1] "" Vector__XXX
 SG_ RCM_a018_eventFrontRightSeatbelt m18 : 27|1@1+ (1,0) [0|1] "" Vector__XXX
 SG_ RCM_a018_eventVehicleSpeed m18 : 28|12@1+ (0.08,-40) [-40|287.6] "kph" Vector__XXX
 SG_ RCM_a018_eventSteeringAngle m18 : 45|14@0+ (0.1,-819.2) [-819.2|819.1] "deg" Vector__XXX
 SG_ RCM_a018_eventDriverBrakeApply m18 : 46|2@1+ (1,0) [0|2] "" Vector__XXX
 SG_ RCM_a018_eventAccelPedalPos m18 : 56|8@1+ (0.4,0) [0|101.6] "%" Vector__XXX
 SG_ RCM_a019_eventArmStatus m19 : 11|1@1+ (1,0) [0|1] "" Vector__XXX
 SG_ RCM_a019_eventFactoryMode m19 : 12|1@1+ (1,0) [0|1] "" Vector__XXX
 SG_ RCM_a019_eventDiagEnabled m19 : 13|1@1+ (1,0) [0|1] "" Vector__XXX
 SG_ RCM_a019_eventDriveOrientation m19 : 14|1@1+ (1,0) [0|1] "" Vector__XXX
 SG_ RCM_a019_pretenShldLeftSht2Gnd m19 : 16|1@1+ (1,0) [0|1] "" Vector__XXX
 SG_ RCM_a019_pretenShldLeftSht2Bat m19 : 17|1@1+ (1,0) [0|1] "" Vector__XXX
 SG_ RCM_a019_pretenShldLeftOpen m19 : 18|1@1+ (1,0) [0|1] "" Vector__XXX
 SG_ RCM_a019_pretenShldLeftShort m19 : 19|1@1+ (1,0) [0|1] "" Vector__XXX
 SG_ RCM_a019_pretenShldLeftCrossC m19 : 20|1@1+ (1,0) [0|1] "" Vector__XXX
 SG_ RCM_a019_pretenShldLeftConfig m19 : 21|1@1+ (1,0) [0|1] "" Vector__XXX
 SG_ RCM_a019_eventIDFsignal m19 : 25|1@1+ (1,0) [0|1] "" Vector__XXX
 SG_ RCM_a019_eventFrontLeftSeatbelt m19 : 26|1@1+ (1,0) [0|1] "" Vector__XXX
 SG_ RCM_a019_eventFrontRightSeatbelt m19 : 27|1@1+ (1,0) [0|1] "" Vector__XXX
 SG_ RCM_a019_eventVehicleSpeed m19 : 28|12@1+ (0.08,-40) [-40|287.6] "kph" Vector__XXX
 SG_ RCM_a019_eventSteeringAngle m19 : 45|14@0+ (0.1,-819.2) [-819.2|819.1] "deg" Vector__XXX
 SG_ RCM_a019_eventDriverBrakeApply m19 : 46|2@1+ (1,0) [0|2] "" Vector__XXX
 SG_ RCM_a019_eventAccelPedalPos m19 : 56|8@1+ (0.4,0) [0|101.6] "%" Vector__XXX
 SG_ RCM_a020_eventArmStatus m20 : 11|1@1+ (1,0) [0|1] "" Vector__XXX
 SG_ RCM_a020_eventFactoryMode m20 : 12|1@1+ (1,0) [0|1] "" Vector__XXX
 SG_ RCM_a020_eventDiagEnabled m20 : 13|1@1+ (1,0) [0|1] "" Vector__XXX
 SG_ RCM_a020_eventDriveOrientation m20 : 14|1@1+ (1,0) [0|1] "" Vector__XXX
 SG_ RCM_a020_pretenShldRightSht2Gnd m20 : 16|1@1+ (1,0) [0|1] "" Vector__XXX
 SG_ RCM_a020_pretenShldRightSht2Bat m20 : 17|1@1+ (1,0) [0|1] "" Vector__XXX
 SG_ RCM_a020_pretenShldRightOpen m20 : 18|1@1+ (1,0) [0|1] "" Vector__XXX
 SG_ RCM_a020_pretenShldRightShort m20 : 19|1@1+ (1,0) [0|1] "" Vector__XXX
 SG_ RCM_a020_pretenShldRightCrossC m20 : 20|1@1+ (1,0) [0|1] "" Vector__XXX
 SG_ RCM_a020_pretenShldRightConfig m20 : 21|1@1+ (1,0) [0|1] "" Vector__XXX
 SG_ RCM_a020_eventIDFsignal m20 : 25|1@1+ (1,0) [0|1] "" Vector__XXX
 SG_ RCM_a020_eventFrontLeftSeatbelt m20 : 26|1@1+ (1,0) [0|1] "" Vector__XXX
 SG_ RCM_a020_eventFrontRightSeatbelt m20 : 27|1@1+ (1,0) [0|1] "" Vector__XXX
 SG_ RCM_a020_eventVehicleSpeed m20 : 28|12@1+ (0.08,-40) [-40|287.6] "kph" Vector__XXX
 SG_ RCM_a020_eventSteeringAngle m20 : 45|14@0+ (0.1,-819.2) [-819.2|819.1] "deg" Vector__XXX
 SG_ RCM_a020_eventDriverBrakeApply m20 : 46|2@1+ (1,0) [0|2] "" Vector__XXX
 SG_ RCM_a020_eventAccelPedalPos m20 : 56|8@1+ (0.4,0) [0|101.6] "%" Vector__XXX
 SG_ RCM_a021_eventArmStatus m21 : 11|1@1+ (1,0) [0|1] "" Vector__XXX
 SG_ RCM_a021_eventFactoryMode m21 : 12|1@1+ (1,0) [0|1] "" Vector__XXX
 SG_ RCM_a021_eventDiagEnabled m21 : 13|1@1+ (1,0) [0|1] "" Vector__XXX
 SG_ RCM_a021_eventDriveOrientation m21 : 14|1@1+ (1,0) [0|1] "" Vector__XXX
 SG_ RCM_a021_pretenLapLeftSht2Gnd m21 : 16|1@1+ (1,0) [0|1] "" Vector__XXX
 SG_ RCM_a021_pretenLapLeftSht2Bat m21 : 17|1@1+ (1,0) [0|1] "" Vector__XXX
 SG_ RCM_a021_pretenLapLeftOpen m21 : 18|1@1+ (1,0) [0|1] "" Vector__XXX
 SG_ RCM_a021_pretenLapLeftShort m21 : 19|1@1+ (1,0) [0|1] "" Vector__XXX
 SG_ RCM_a021_pretenLapLeftCrossCoup m21 : 20|1@1+ (1,0) [0|1] "" Vector__XXX
 SG_ RCM_a021_pretenLapLeftConfig m21 : 21|1@1+ (1,0) [0|1] "" Vector__XXX
 SG_ RCM_a021_eventIDFsignal m21 : 25|1@1+ (1,0) [0|1] "" Vector__XXX
 SG_ RCM_a021_eventFrontLeftSeatbelt m21 : 26|1@1+ (1,0) [0|1] "" Vector__XXX
 SG_ RCM_a021_eventFrontRightSeatbelt m21 : 27|1@1+ (1,0) [0|1] "" Vector__XXX
 SG_ RCM_a021_eventVehicleSpeed m21 : 28|12@1+ (0.08,-40) [-40|287.6] "kph" Vector__XXX
 SG_ RCM_a021_eventSteeringAngle m21 : 45|14@0+ (0.1,-819.2) [-819.2|819.1] "deg" Vector__XXX
 SG_ RCM_a021_eventDriverBrakeApply m21 : 46|2@1+ (1,0) [0|2] "" Vector__XXX
 SG_ RCM_a021_eventAccelPedalPos m21 : 56|8@1+ (0.4,0) [0|101.6] "%" Vector__XXX
 SG_ RCM_a022_eventArmStatus m22 : 11|1@1+ (1,0) [0|1] "" Vector__XXX
 SG_ RCM_a022_eventFactoryMode m22 : 12|1@1+ (1,0) [0|1] "" Vector__XXX
 SG_ RCM_a022_eventDiagEnabled m22 : 13|1@1+ (1,0) [0|1] "" Vector__XXX
 SG_ RCM_a022_eventDriveOrientation m22 : 14|1@1+ (1,0) [0|1] "" Vector__XXX
 SG_ RCM_a022_pretenLapRightSht2Gnd m22 : 16|1@1+ (1,0) [0|1] "" Vector__XXX
 SG_ RCM_a022_pretenLapRightSht2Bat m22 : 17|1@1+ (1,0) [0|1] "" Vector__XXX
 SG_ RCM_a022_pretenLapRightOpen m22 : 18|1@1+ (1,0) [0|1] "" Vector__XXX
 SG_ RCM_a022_pretenLapRightShort m22 : 19|1@1+ (1,0) [0|1] "" Vector__XXX
 SG_ RCM_a022_pretenLapRightCrossCoup m22 : 20|1@1+ (1,0) [0|1] "" Vector__XXX
 SG_ RCM_a022_pretenLapRightConfig m22 : 21|1@1+ (1,0) [0|1] "" Vector__XXX
 SG_ RCM_a022_eventIDFsignal m22 : 25|1@1+ (1,0) [0|1] "" Vector__XXX
 SG_ RCM_a022_eventFrontLeftSeatbelt m22 : 26|1@1+ (1,0) [0|1] "" Vector__XXX
 SG_ RCM_a022_eventFrontRightSeatbelt m22 : 27|1@1+ (1,0) [0|1] "" Vector__XXX
 SG_ RCM_a022_eventVehicleSpeed m22 : 28|12@1+ (0.08,-40) [-40|287.6] "kph" Vector__XXX
 SG_ RCM_a022_eventSteeringAngle m22 : 45|14@0+ (0.1,-819.2) [-819.2|819.1] "deg" Vector__XXX
 SG_ RCM_a022_eventDriverBrakeApply m22 : 46|2@1+ (1,0) [0|2] "" Vector__XXX
 SG_ RCM_a022_eventAccelPedalPos m22 : 56|8@1+ (0.4,0) [0|101.6] "%" Vector__XXX
 SG_ RCM_a023_eventArmStatus m23 : 11|1@1+ (1,0) [0|1] "" Vector__XXX
 SG_ RCM_a023_eventFactoryMode m23 : 12|1@1+ (1,0) [0|1] "" Vector__XXX
 SG_ RCM_a023_eventDiagEnabled m23 : 13|1@1+ (1,0) [0|1] "" Vector__XXX
 SG_ RCM_a023_eventDriveOrientation m23 : 14|1@1+ (1,0) [0|1] "" Vector__XXX
 SG_ RCM_a023_loadLimLeftSht2Gnd m23 : 16|1@1+ (1,0) [0|1] "" Vector__XXX
 SG_ RCM_a023_loadLimLeftSht2Bat m23 : 17|1@1+ (1,0) [0|1] "" Vector__XXX
 SG_ RCM_a023_loadLimLeftOpen m23 : 18|1@1+ (1,0) [0|1] "" Vector__XXX
 SG_ RCM_a023_loadLimLeftShort m23 : 19|1@1+ (1,0) [0|1] "" Vector__XXX
 SG_ RCM_a023_loadLimLeftCrossCoup m23 : 20|1@1+ (1,0) [0|1] "" Vector__XXX
 SG_ RCM_a023_loadLimLeftConfig m23 : 21|1@1+ (1,0) [0|1] "" Vector__XXX
 SG_ RCM_a023_eventIDFsignal m23 : 25|1@1+ (1,0) [0|1] "" Vector__XXX
 SG_ RCM_a023_eventFrontLeftSeatbelt m23 : 26|1@1+ (1,0) [0|1] "" Vector__XXX
 SG_ RCM_a023_eventFrontRightSeatbelt m23 : 27|1@1+ (1,0) [0|1] "" Vector__XXX
 SG_ RCM_a023_eventVehicleSpeed m23 : 28|12@1+ (0.08,-40) [-40|287.6] "kph" Vector__XXX
 SG_ RCM_a023_eventSteeringAngle m23 : 45|14@0+ (0.1,-819.2) [-819.2|819.1] "deg" Vector__XXX
 SG_ RCM_a023_eventDriverBrakeApply m23 : 46|2@1+ (1,0) [0|2] "" Vector__XXX
 SG_ RCM_a023_eventAccelPedalPos m23 : 56|8@1+ (0.4,0) [0|101.6] "%" Vector__XXX
 SG_ RCM_a024_eventArmStatus m24 : 11|1@1+ (1,0) [0|1] "" Vector__XXX
 SG_ RCM_a024_eventFactoryMode m24 : 12|1@1+ (1,0) [0|1] "" Vector__XXX
 SG_ RCM_a024_eventDiagEnabled m24 : 13|1@1+ (1,0) [0|1] "" Vector__XXX
 SG_ RCM_a024_eventDriveOrientation m24 : 14|1@1+ (1,0) [0|1] "" Vector__XXX
 SG_ RCM_a024_loadLimRightSht2Gnd m24 : 16|1@1+ (1,0) [0|1] "" Vector__XXX
 SG_ RCM_a024_loadLimRightSht2Bat m24 : 17|1@1+ (1,0) [0|1] "" Vector__XXX
 SG_ RCM_a024_loadLimRightOpen m24 : 18|1@1+ (1,0) [0|1] "" Vector__XXX
 SG_ RCM_a024_loadLimRightShort m24 : 19|1@1+ (1,0) [0|1] "" Vector__XXX
 SG_ RCM_a024_loadLimRightCrossCoup m24 : 20|1@1+ (1,0) [0|1] "" Vector__XXX
 SG_ RCM_a024_loadLimRightConfig m24 : 21|1@1+ (1,0) [0|1] "" Vector__XXX
 SG_ RCM_a024_eventIDFsignal m24 : 25|1@1+ (1,0) [0|1] "" Vector__XXX
 SG_ RCM_a024_eventFrontLeftSeatbelt m24 : 26|1@1+ (1,0) [0|1] "" Vector__XXX
 SG_ RCM_a024_eventFrontRightSeatbelt m24 : 27|1@1+ (1,0) [0|1] "" Vector__XXX
 SG_ RCM_a024_eventVehicleSpeed m24 : 28|12@1+ (0.08,-40) [-40|287.6] "kph" Vector__XXX
 SG_ RCM_a024_eventSteeringAngle m24 : 45|14@0+ (0.1,-819.2) [-819.2|819.1] "deg" Vector__XXX
 SG_ RCM_a024_eventDriverBrakeApply m24 : 46|2@1+ (1,0) [0|2] "" Vector__XXX
 SG_ RCM_a024_eventAccelPedalPos m24 : 56|8@1+ (0.4,0) [0|101.6] "%" Vector__XXX
 SG_ RCM_a025_eventArmStatus m25 : 11|1@1+ (1,0) [0|1] "" Vector__XXX
 SG_ RCM_a025_eventFactoryMode m25 : 12|1@1+ (1,0) [0|1] "" Vector__XXX
 SG_ RCM_a025_eventDiagEnabled m25 : 13|1@1+ (1,0) [0|1] "" Vector__XXX
 SG_ RCM_a025_eventDriveOrientation m25 : 14|1@1+ (1,0) [0|1] "" Vector__XXX
 SG_ RCM_a025_kneeABDrvrSht2Gnd m25 : 16|1@1+ (1,0) [0|1] "" Vector__XXX
 SG_ RCM_a025_kneeABDrvrSht2Bat m25 : 17|1@1+ (1,0) [0|1] "" Vector__XXX
 SG_ RCM_a025_kneeABDrvrOpen m25 : 18|1@1+ (1,0) [0|1] "" Vector__XXX
 SG_ RCM_a025_kneeABDrvrShort m25 : 19|1@1+ (1,0) [0|1] "" Vector__XXX
 SG_ RCM_a025_kneeABDrvrCrossCoup m25 : 20|1@1+ (1,0) [0|1] "" Vector__XXX
 SG_ RCM_a025_kneeABDrvrConfig m25 : 21|1@1+ (1,0) [0|1] "" Vector__XXX
 SG_ RCM_a025_eventIDFsignal m25 : 25|1@1+ (1,0) [0|1] "" Vector__XXX
 SG_ RCM_a025_eventFrontLeftSeatbelt m25 : 26|1@1+ (1,0) [0|1] "" Vector__XXX
 SG_ RCM_a025_eventFrontRightSeatbelt m25 : 27|1@1+ (1,0) [0|1] "" Vector__XXX
 SG_ RCM_a025_eventVehicleSpeed m25 : 28|12@1+ (0.08,-40) [-40|287.6] "kph" Vector__XXX
 SG_ RCM_a025_eventSteeringAngle m25 : 45|14@0+ (0.1,-819.2) [-819.2|819.1] "deg" Vector__XXX
 SG_ RCM_a025_eventDriverBrakeApply m25 : 46|2@1+ (1,0) [0|2] "" Vector__XXX
 SG_ RCM_a025_eventAccelPedalPos m25 : 56|8@1+ (0.4,0) [0|101.6] "%" Vector__XXX
 SG_ RCM_a026_eventArmStatus m26 : 11|1@1+ (1,0) [0|1] "" Vector__XXX
 SG_ RCM_a026_eventFactoryMode m26 : 12|1@1+ (1,0) [0|1] "" Vector__XXX
 SG_ RCM_a026_eventDiagEnabled m26 : 13|1@1+ (1,0) [0|1] "" Vector__XXX
 SG_ RCM_a026_eventDriveOrientation m26 : 14|1@1+ (1,0) [0|1] "" Vector__XXX
 SG_ RCM_a026_kneeABPassSht2Gnd m26 : 16|1@1+ (1,0) [0|1] "" Vector__XXX
 SG_ RCM_a026_kneeABPassSht2Bat m26 : 17|1@1+ (1,0) [0|1] "" Vector__XXX
 SG_ RCM_a026_kneeABPassOpen m26 : 18|1@1+ (1,0) [0|1] "" Vector__XXX
 SG_ RCM_a026_kneeABPassShort m26 : 19|1@1+ (1,0) [0|1] "" Vector__XXX
 SG_ RCM_a026_kneeABPassCrossCoup m26 : 20|1@1+ (1,0) [0|1] "" Vector__XXX
 SG_ RCM_a026_kneeABPassConfig m26 : 21|1@1+ (1,0) [0|1] "" Vector__XXX
 SG_ RCM_a026_eventIDFsignal m26 : 25|1@1+ (1,0) [0|1] "" Vector__XXX
 SG_ RCM_a026_eventFrontLeftSeatbelt m26 : 26|1@1+ (1,0) [0|1] "" Vector__XXX
 SG_ RCM_a026_eventFrontRightSeatbelt m26 : 27|1@1+ (1,0) [0|1] "" Vector__XXX
 SG_ RCM_a026_eventVehicleSpeed m26 : 28|12@1+ (0.08,-40) [-40|287.6] "kph" Vector__XXX
 SG_ RCM_a026_eventSteeringAngle m26 : 45|14@0+ (0.1,-819.2) [-819.2|819.1] "deg" Vector__XXX
 SG_ RCM_a026_eventDriverBrakeApply m26 : 46|2@1+ (1,0) [0|2] "" Vector__XXX
 SG_ RCM_a026_eventAccelPedalPos m26 : 56|8@1+ (0.4,0) [0|101.6] "%" Vector__XXX
 SG_ RCM_a027_eventArmStatus m27 : 11|1@1+ (1,0) [0|1] "" Vector__XXX
 SG_ RCM_a027_eventFactoryMode m27 : 12|1@1+ (1,0) [0|1] "" Vector__XXX
 SG_ RCM_a027_eventDiagEnabled m27 : 13|1@1+ (1,0) [0|1] "" Vector__XXX
 SG_ RCM_a027_eventDriveOrientation m27 : 14|1@1+ (1,0) [0|1] "" Vector__XXX
 SG_ RCM_a027_sideAB1stRowLSht2Gnd m27 : 16|1@1+ (1,0) [0|1] "" Vector__XXX
 SG_ RCM_a027_sideAB1stRowLSht2Bat m27 : 17|1@1+ (1,0) [0|1] "" Vector__XXX
 SG_ RCM_a027_sideAB1stRowLOpen m27 : 18|1@1+ (1,0) [0|1] "" Vector__XXX
 SG_ RCM_a027_sideAB1stRowLShort m27 : 19|1@1+ (1,0) [0|1] "" Vector__XXX
 SG_ RCM_a027_sideAB1stRowLCrossCoup m27 : 20|1@1+ (1,0) [0|1] "" Vector__XXX
 SG_ RCM_a027_sideAB1stRowLConfig m27 : 21|1@1+ (1,0) [0|1] "" Vector__XXX
 SG_ RCM_a027_eventIDFsignal m27 : 25|1@1+ (1,0) [0|1] "" Vector__XXX
 SG_ RCM_a027_eventFrontLeftSeatbelt m27 : 26|1@1+ (1,0) [0|1] "" Vector__XXX
 SG_ RCM_a027_eventFrontRightSeatbelt m27 : 27|1@1+ (1,0) [0|1] "" Vector__XXX
 SG_ RCM_a027_eventVehicleSpeed m27 : 28|12@1+ (0.08,-40) [-40|287.6] "kph" Vector__XXX
 SG_ RCM_a027_eventSteeringAngle m27 : 45|14@0+ (0.1,-819.2) [-819.2|819.1] "deg" Vector__XXX
 SG_ RCM_a027_eventDriverBrakeApply m27 : 46|2@1+ (1,0) [0|2] "" Vector__XXX
 SG_ RCM_a027_eventAccelPedalPos m27 : 56|8@1+ (0.4,0) [0|101.6] "%" Vector__XXX
 SG_ RCM_a028_eventArmStatus m28 : 11|1@1+ (1,0) [0|1] "" Vector__XXX
 SG_ RCM_a028_eventFactoryMode m28 : 12|1@1+ (1,0) [0|1] "" Vector__XXX
 SG_ RCM_a028_eventDiagEnabled m28 : 13|1@1+ (1,0) [0|1] "" Vector__XXX
 SG_ RCM_a028_eventDriveOrientation m28 : 14|1@1+ (1,0) [0|1] "" Vector__XXX
 SG_ RCM_a028_sideAB1stRowRSht2Gnd m28 : 16|1@1+ (1,0) [0|1] "" Vector__XXX
 SG_ RCM_a028_sideAB1stRowRSht2Bat m28 : 17|1@1+ (1,0) [0|1] "" Vector__XXX
 SG_ RCM_a028_sideAB1stRowROpen m28 : 18|1@1+ (1,0) [0|1] "" Vector__XXX
 SG_ RCM_a028_sideAB1stRowRShort m28 : 19|1@1+ (1,0) [0|1] "" Vector__XXX

BO_TX_BU_ 2033 : GTW;
BO_TX_BU_ 2026 : GTW;
BO_TX_BU_ 60 : GTW;
BO_TX_BU_ 1370 : GTW;
BO_TX_BU_ 840 : GTW;
BO_TX_BU_ 1005 : GTW;
BO_TX_BU_ 1112 : GTW;
BO_TX_BU_ 1429 : OCS1P;
BO_TX_BU_ 767 : OCS1P;
BO_TX_BU_ 766 : OCS1P;
BO_TX_BU_ 771 : OCS1P;
BO_TX_BU_ 1619 : OCS1P;
BO_TX_BU_ 519 : PTC;
BO_TX_BU_ 1297 : RCM;
CM_ BO_ 2033 "Gateway message: hrl";
CM_ SG_ 2033 GTW_hrlIndex "Gateway: hrl index";
CM_ SG_ 2033 GTW_hrlPagesCount "Gateway: hrl pages count";
CM_ SG_ 2033 GTW_hrlSdCardSizeGB "Gateway: hrl sd card size GB; raw 0 = signal not available (SNA)";
CM_ SG_ 2033 GTW_hrlState "GTW hrl state";
CM_ SG_ 2033 GTW_hrlTriggerDuration "HRL duration";
CM_ SG_ 2033 GTW_hrlTriggerType "HRL trigger type";
CM_ SG_ 2033 GTW_hrlTriggerId "HRL trigger ID. A unique ID representing the signal conditions causing the HRL event to occur.";
CM_ SG_ 2033 GTW_hrlTriggerBus "Gateway: hrl trigger bus";
CM_ BO_ 2026 "Gateway message: hrl external event";
CM_ SG_ 2026 GTW_hrlEventStartEpoch "Gateway: hrl event start epoch";
CM_ SG_ 2026 GTW_hrlEventEndEpoch "Gateway: hrl event end epoch";
CM_ BO_ 60 "Gateway message: info";
CM_ SG_ 60 GTW_infoIndex "Gateway: info index";
CM_ SG_ 60 GTW_buildType "Gateway: build type";
CM_ SG_ 60 GTW_hardwareId "GTW hardware ID";
CM_ SG_ 60 GTW_platformType "Gateway: platform type";
CM_ SG_ 60 GTW_appCrc "Gateway: app crc";
CM_ SG_ 60 GTW_applicationGitHash "Gateway: application git hash";
CM_ SG_ 60 GTW_bootGitHash "Gateway: boot git hash";
CM_ BO_ 1370 "Gateway message: mismatch fault";
CM_ SG_ 1370 GTW_mismatchFaultIndex "Gateway: mismatch fault index";
CM_ SG_ 1370 GTW_mismatchFaultChecksum "Gateway: mismatch fault checksum";
CM_ SG_ 1370 GTW_mismatchFaultCounter "Gateway: mismatch fault counter";
CM_ SG_ 1370 GTW_GTWmismatchFault "Reports the Gateway (GTW) running a firmware version that does not match the rest of the vehicle";
CM_ SG_ 1370 GTW_BMSmismatchFault "Reports the high voltage Battery Management System (BMS) electronic control unit (ECU) running a firmware version that does not match the rest of the vehicle";
CM_ SG_ 1370 GTW_APSmismatchFault "Reports the Autopilot Processor Secondary (APS) electronic control unit (ECU) running a firmware version that does not match the rest of the vehicle";
CM_ SG_ 1370 GTW_BLEEPCENTERmismatchFault "Reports the Bluetooth Low Energy End Point Center (BLEEPCENTER) electronic control unit (ECU) running a firmware version that does not match the rest of the vehicle";
CM_ SG_ 1370 GTW_BLEEPLEFTmismatchFault "Reports the Bluetooth Low Energy End Point Left (BLEEPLEFT) electronic control unit (ECU) running a firmware version that does not match the rest of the vehicle";
CM_ SG_ 1370 GTW_BLEEPREARmismatchFault "Reports the Bluetooth Low Energy End Point Rear (BLEEPREAR) electronic control unit (ECU) running a firmware version that does not match the rest of the vehicle";
CM_ SG_ 1370 GTW_BLEEPRIGHTmismatchFault "Reports the Bluetooth Low Energy End Point Right (BLEEPRIGHT) electronic control unit (ECU) running a firmware version that does not match the rest of the vehicle";
CM_ SG_ 1370 GTW_CBCmismatchFault "Reports the Cabin Blower Controller (CBC) electronic control unit (ECU) running a firmware version that does not match the rest of the vehicle";
CM_ SG_ 1370 GTW_CMPmismatchFault "Reports the air conditioning compressor (CMP) electronic control unit (ECU) running a firmware version that does not match the rest of the vehicle";
CM_ SG_ 1370 GTW_CPmismatchFault "Reports the Charge Port (CP) electronic control unit (ECU) running a firmware version that does not match the rest of the vehicle";
CM_ SG_ 1370 GTW_DIFmismatchFault "Reports the front drive inverter (DIF) electronic control unit (ECU) running a firmware version that does not match the rest of the vehicle";
CM_ SG_ 1370 GTW_DIRmismatchFault "Reports the rear drive inverter (DIR) electronic control unit (ECU) running a firmware version that does not match the rest of the vehicle";
CM_ SG_ 1370 GTW_EPAS3PmismatchFault "Reports the primary Electronic Power Assisted Steering (EPAS3P) electronic control unit (ECU) running a firmware version that does not match the rest of the vehicle";
CM_ SG_ 1370 GTW_EPAS3SmismatchFault "Reports the secondary Electronic Power Assisted Steering (EPAS3S) electronic control unit (ECU) running a firmware version that does not match the rest of the vehicle";
CM_ SG_ 1370 GTW_EPBLmismatchFault "Reports the left Electronic Park Brake (EPBL) electronic control unit (ECU) running a firmware version that does not match the rest of the vehicle";
CM_ SG_ 1370 GTW_EPBRmismatchFault "Reports the right Electronic Park Brake (EPBR) electronic control unit (ECU) running a firmware version that does not match the rest of the vehicle";
CM_ SG_ 1370 GTW_ESPCALmismatchFault "Reports the Electronic Stability Program Calibration (ESPCAL) electronic control unit (ECU) running a firmware version that does not match the rest of the vehicle";
CM_ SG_ 1370 GTW_ESPmismatchFault "Reports the Electronic Stability Program (ESP) electronic control unit (ECU) running a firmware version that does not match the rest of the vehicle";
CM_ SG_ 1370 GTW_HCM3LmismatchFault "Reports the left LED matrix Headlamp Control Module (HCM3L) electronic control unit (ECU) running a firmware version that does not match the rest of the vehicle";
CM_ SG_ 1370 GTW_HCM3RmismatchFault "Reports the right LED matrix Headlamp Control Module (HCM3R) electronic control unit (ECU) running a firmware version that does not match the rest of the vehicle";
CM_ SG_ 1370 GTW_HCMLmismatchFault "Reports the left Headlamp Control Module (HCML) electronic control unit (ECU) running a firmware version that does not match the rest of the vehicle";
CM_ SG_ 1370 GTW_HCMRmismatchFault "Reports the right Headlamp Control Module (HCMR) electronic control unit (ECU) running a firmware version that does not match the rest of the vehicle";
CM_ SG_ 1370 GTW_HVPmismatchFault "Reports the High Voltage Processor (HVP) electronic control unit (ECU) running a firmware version that does not match the rest of the vehicle";
CM_ SG_ 1370 GTW_IBSTCALmismatchFault "Reports the electromechanical brake booster calibration, or iBooster Calibration (IBSTCAL), electronic control unit (ECU) running a firmware version that does not match the rest of the vehicle";
CM_ SG_ 1370 GTW_IBSTmismatchFault "Reports the electromechanical brake booster, or iBooster (IBST), electronic control unit (ECU) running a firmware version that does not match the rest of the vehicle";
CM_ SG_ 1370 GTW_LVBMSmismatchFault "Reports the Low Voltage Battery Management System (LVBMS) electronic control unit (ECU) running a firmware version that does not match the rest of the vehicle";
CM_ SG_ 1370 GTW_OCS1PmismatchFault "Reports the Occupancy Classification System - 1st Row Passenger (OCS1P) electronic control unit (ECU) running a firmware version that does not match the rest of the vehicle";
CM_ SG_ 1370 GTW_OPCFmismatchFault "Reports the front Oil Pump Controller (OPCF) electronic control unit (ECU) running a firmware version that does not match the rest of the vehicle";
CM_ SG_ 1370 GTW_OPCRmismatchFault "Reports the rear Oil Pump Controller (OPCR) electronic control unit (ECU) running a firmware version that does not match the rest of the vehicle";
CM_ SG_ 1370 GTW_PARKmismatchFault "Reports the Park Assist (PARK) electronic control unit (ECU) running a firmware version that does not match the rest of the vehicle";
CM_ SG_ 1370 GTW_PCSCPU2mismatchFault "Reports the Power Conversion System AC charging core (PCSCPU2) electronic control unit (ECU) running a firmware version that does not match the rest of the vehicle";
CM_ SG_ 1370 GTW_PCSmismatchFault "Reports the Power Conversion System (PCS) electronic control unit (ECU) running a firmware version that does not match the rest of the vehicle";
CM_ SG_ 1370 GTW_PMFmismatchFault "Reports the front Pedal Monitor (PMF) electronic control unit (ECU) running a firmware version that does not match the rest of the vehicle";
CM_ SG_ 1370 GTW_PMRmismatchFault "Reports the rear Pedal Monitor (PMR) electronic control unit (ECU) running a firmware version that does not match the rest of the vehicle";
CM_ SG_ 1370 GTW_PTCmismatchFault "Reports the Positive Temperature Coefficient (PTC) heater electronic control unit (ECU) running a firmware version that does not match the rest of the vehicle";
CM_ SG_ 1370 GTW_RCMCALmismatchFault "Reports the Restraint Control Module Calibration (RCMCAL) electronic control unit (ECU) running a firmware version that does not match the rest of the vehicle";
CM_ SG_ 1370 GTW_RCMmismatchFault "Reports the Restraint Control Module (RCM) electronic control unit (ECU) running a firmware version that does not match the rest of the vehicle";
CM_ SG_ 1370 GTW_SCCMmismatchFault "Reports the Steering Column Control Module (SCCM) electronic control unit (ECU) running a firmware version that does not match the rest of the vehicle";
CM_ SG_ 1370 GTW_SDCRmismatchFault "Reports the Secondary Disconnect Controller (SDCR) electronic control unit (ECU) running a firmware version that does not match the rest of the vehicle";
CM_ SG_ 1370 GTW_SWCmismatchFault "Reports the Steering Wheel Controller (SWC) electronic control unit (ECU) running a firmware version that does not match the rest of the vehicle";
CM_ SG_ 1370 GTW_THSmismatchFault "Reports the Temperature Humidity Sensor (THS) electronic control unit (ECU) running a firmware version that does not match the rest of the vehicle";
CM_ SG_ 1370 GTW_VCFRONTmismatchFault "Reports the front vehicle controller (VCFRONT) electronic control unit (ECU) running a firmware version that does not match the rest of the vehicle";
CM_ SG_ 1370 GTW_VCLEFTmismatchFault "Reports the left vehicle controller (VCLEFT) electronic control unit (ECU) running a firmware version that does not match the rest of the vehicle";
CM_ SG_ 1370 GTW_VCRIGHTmismatchFault "Reports the right vehicle controller (VCRIGHT) electronic control unit (ECU) running a firmware version that does not match the rest of the vehicle";
CM_ SG_ 1370 GTW_VCSECmismatchFault "Reports the vehicle security controller (VCSEC) electronic control unit (ECU) running a firmware version that does not match the rest of the vehicle";
CM_ SG_ 1370 GTW_PMmismatchFault "Reports the Pedal Monitor (PM) electronic control unit (ECU) running a firmware version that does not match the rest of the vehicle";
CM_ BO_ 840 "Gateway message: status";
CM_ SG_ 840 GTW_vehicleVersionMatchStatus "Signal to indicate if the vehicle ECUs are all on a matched production version";
CM_ SG_ 840 GTW_hwtype "Describes the chip GTW is running on; raw 0 = signal not available (SNA)";
CM_ SG_ 840 GTW_jcanProductName "Describes the JCAN reference (product) name; raw 0 = signal not available (SNA)";
CM_ SG_ 840 GTW_uptimeSeconds "GTW uptime in seconds";
CM_ SG_ 840 GTW_boardRevision "Board revision ID of the MCU PCBA";
CM_ SG_ 840 GTW_touchcoreOsType "Gateway: touchcore os type";
CM_ SG_ 840 GTW_sentryModeState "Sentry Mode state; raw 6 = signal not available (SNA)";
CM_ SG_ 840 GTW_secureBootEnabled "Gateway: secure boot enabled";
CM_ SG_ 840 GTW_socSleepType "Describes the sleep type GTW is expecting from the SoC; raw 0 = signal not available (SNA)";
CM_ SG_ 840 GTW_resetType "Describes the type of reset GTW experienced; raw 0 = signal not available (SNA)";
CM_ BO_ 1005 "Gateway message: update status";
CM_ SG_ 1005 GTW_i2cUpdateActive "Gateway: i2c update active";
CM_ SG_ 1005 GTW_peripheralConfirmedUpdateNee "Detects if peripheral has confirmed update is needed";
CM_ SG_ 1005 GTW_ocuFailed "Reports the offboard charger update was unsuccessful.";
CM_ SG_ 1005 GTW_ecuUpdateStarted "Reports whether Electronic Control Unit (ECU) update phase is active.";
CM_ SG_ 1005 GTW_updateStarted "Main update in progress bit";
CM_ BO_ 1112 "Gateway message: veh nm";
CM_ SG_ 1112 GTW_nmGoingToSleep "Network management - Going to sleep state";
CM_ SG_ 1112 GTW_nmWakeUpBus "Gateway: nm wake up bus";
CM_ SG_ 1112 GTW_chBusAsleep "Chassis bus sleep state";
CM_ SG_ 1112 GTW_ethBusAsleep "ETH bus sleep state";
CM_ SG_ 1112 GTW_nmKeepAwakeReason "Network management - Keep awake reason; raw 0 = signal not available (SNA)";
CM_ SG_ 1112 GTW_nmWakeUpReason "Network management - Wakeup reason";
CM_ SG_ 1112 GTW_ethKeepAwakeReason "Reason GTW is keeping ETH bus awake; raw 0 = signal not available (SNA)";
CM_ SG_ 1112 GTW_nmDebugWakeUp "Gateway: nm debug wake up";
CM_ SG_ 1112 GTW_OTAKeepAwake "Signals that the vehicle buses should remain awake for an ongoing OTA update";
CM_ SG_ 1112 GTW_smsPokeReceived "The modem indicated it received an SMS poke";
CM_ SG_ 1112 GTW_bdyBusAsleep "BDY bus sleep state";
CM_ BO_ 1429 "Occupant classification system message: alert log";
CM_ SG_ 1429 OCS1P_alertID "Occupant classification system: alert ID";
CM_ SG_ 1429 OCS1P_alertState "Occupant classification system: alert state";
CM_ SG_ 1429 OCS1P_a121_sandwichFreq "Occupant classification system: a121 sandwich freq";
CM_ SG_ 1429 OCS1P_a122_sandwichFreq "Occupant classification system: a122 sandwich freq";
CM_ SG_ 1429 OCS1P_a123_sandwichFreq "Occupant classification system: a123 sandwich freq";
CM_ SG_ 1429 OCS1P_a124_cushionSelfFreq "Occupant classification system: a124 cushion self freq";
CM_ SG_ 1429 OCS1P_a125_cushionSelfFreq "Occupant classification system: a125 cushion self freq";
CM_ SG_ 1429 OCS1P_a126_cushionSelfFreq "Occupant classification system: a126 cushion self freq";
CM_ SG_ 1429 OCS1P_a127_seatbackSelfFreq "Occupant classification system: a127 seatback self freq";
CM_ SG_ 1429 OCS1P_a128_seatbackSelfFreq "Occupant classification system: a128 seatback self freq";
CM_ SG_ 1429 OCS1P_a129_seatbackSelfFreq "Occupant classification system: a129 seatback self freq";
CM_ SG_ 1429 OCS1P_a130_sandwichNoCalib "Occupant classification system: a130 sandwich no calib";
CM_ SG_ 1429 OCS1P_a131_cushionSelfNoCalib "Occupant classification system: a131 cushion self no calib";
CM_ SG_ 1429 OCS1P_a132_seatbackSelfNoCalib "Occupant classification system: a132 seatback self no calib";
CM_ SG_ 1429 OCS1P_a133_sandwichBadCalib "Occupant classification system: a133 sandwich bad calib";
CM_ SG_ 1429 OCS1P_a134_uninitializedCalib "Occupant classification system: a134 uninitialized calib";
CM_ SG_ 1429 OCS1P_a135_tempNoCalib "Occupant classification system: a135 temp no calib";
CM_ SG_ 1429 OCS1P_a140_tempInvalidCalib "Occupant classification system: a140 temp invalid calib";
CM_ SG_ 1429 OCS1P_a141_humidityInvalidCalib "Occupant classification system: a141 humidity invalid calib";
CM_ SG_ 1429 OCS1P_a142_tempHumidityInvalid "Occupant classification system: a142 temp humidity invalid";
CM_ SG_ 1429 OCS1P_a143_mismatchPassAirbag "Occupant classification system: a143 mismatch pass airbag";
CM_ SG_ 1429 OCS1P_a144_mismatchCarRegion "Occupant classification system: a144 mismatch car region";
CM_ BO_ 767 "Occupant classification system message: alert matrix";
CM_ SG_ 767 OCS1P_matrixIndex "Occupant classification system: matrix index";
CM_ SG_ 767 OCS1P_w015_NVMMAlert "Occupant classification system: w015 NVMM alert";
CM_ SG_ 767 OCS1P_w121_sandwichOpen "Occupant classification system: w121 sandwich open";
CM_ SG_ 767 OCS1P_w122_sandwichLow "Occupant classification system: w122 sandwich low";
CM_ SG_ 767 OCS1P_w123_sandwichShort "Occupant classification system: w123 sandwich short";
CM_ SG_ 767 OCS1P_w124_cushionSelfOpen "Occupant classification system: w124 cushion self open";
CM_ SG_ 767 OCS1P_w125_cushionSelfLow "Occupant classification system: w125 cushion self low";
CM_ SG_ 767 OCS1P_w126_cushionSelfShort "Occupant classification system: w126 cushion self short";
CM_ SG_ 767 OCS1P_w127_seatbackSelfOpen "Occupant classification system: w127 seatback self open";
CM_ SG_ 767 OCS1P_w128_seatbackSelfLow "Occupant classification system: w128 seatback self low";
CM_ SG_ 767 OCS1P_w129_seatbackSelfShort "Occupant classification system: w129 seatback self short";
CM_ SG_ 767 OCS1P_w130_sandwichNoCalib "Occupant classification system: w130 sandwich no calib";
CM_ SG_ 767 OCS1P_w131_cushionSelfNoCalib "Occupant classification system: w131 cushion self no calib";
CM_ SG_ 767 OCS1P_w132_seatbackSelfNoCalib "Occupant classification system: w132 seatback self no calib";
CM_ SG_ 767 OCS1P_w133_sandwichBadCalib "Occupant classification system: w133 sandwich bad calib";
CM_ SG_ 767 OCS1P_w134_uninitializedCalib "Occupant classification system: w134 uninitialized calib";
CM_ SG_ 767 OCS1P_w135_tempNoCalib "Occupant classification system: w135 temp no calib";
CM_ SG_ 767 OCS1P_w136_cushionSelfDutyLow "Occupant classification system: w136 cushion self duty low";
CM_ SG_ 767 OCS1P_w137_cushionSelfDutyHigh "Occupant classification system: w137 cushion self duty high";
CM_ SG_ 767 OCS1P_w138_seatbackSelfDutyLow "Occupant classification system: w138 seatback self duty low";
CM_ SG_ 767 OCS1P_w139_seatbackSelfDutyHigh "Occupant classification system: w139 seatback self duty high";
CM_ SG_ 767 OCS1P_w140_tempInvalidCalib "Occupant classification system: w140 temp invalid calib";
CM_ SG_ 767 OCS1P_w141_humidityInvalidCalib "Occupant classification system: w141 humidity invalid calib";
CM_ SG_ 767 OCS1P_w142_tempHumidityInvalid "Occupant classification system: w142 temp humidity invalid";
CM_ SG_ 767 OCS1P_w143_mismatchPassAirbag "Occupant classification system: w143 mismatch pass airbag";
CM_ SG_ 767 OCS1P_w144_mismatchCarRegion "Occupant classification system: w144 mismatch car region";
CM_ SG_ 767 OCS1P_w145_rebaselineTriggered "Occupant classification system: w145 rebaseline triggered";
CM_ SG_ 767 OCS1P_w148_classificationMismatc "Occupant classification system: w148 classification mismatch";
CM_ SG_ 767 OCS1P_w150_rbEntryTriggered "Occupant classification system: w150 rb entry triggered";
CM_ SG_ 767 OCS1P_w151_rbEntryExited "Occupant classification system: w151 rb entry exited";
CM_ SG_ 767 OCS1P_w152_rbExit1Triggered "Occupant classification system: w152 rb exit1 triggered";
CM_ SG_ 767 OCS1P_w153_rbExit1Exited "Occupant classification system: w153 rb exit1 exited";
CM_ SG_ 767 OCS1P_w154_rbExit2Exited1 "Occupant classification system: w154 rb exit2 exited1";
CM_ SG_ 767 OCS1P_w155_rbExit2Exited2 "Occupant classification system: w155 rb exit2 exited2";
CM_ SG_ 767 OCS1P_w156_seatbeltReminderUnava "Occupant classification system: w156 seatbelt reminder unavailable";
CM_ BO_ 766 "Occupant classification system message: info";
CM_ SG_ 766 OCS1P_infoIndex "Occupant classification system: info index";
CM_ SG_ 766 OCS1P_infoBuildType "Occupant classification system: info build type";
CM_ SG_ 766 OCS1P_infoBuildConfigID "Occupant classification system: info build config ID";
CM_ SG_ 766 OCS1P_infoHardwareID "Occupant classification system: info hardware ID";
CM_ SG_ 766 OCS1P_infoComponentID "Occupant classification system: info component ID";
CM_ SG_ 766 OCS1P_infoPcbaID "Occupant classification system: info pcba ID";
CM_ SG_ 766 OCS1P_infoAssemblyID "Occupant classification system: info assembly ID";
CM_ SG_ 766 OCS1P_infoUsageID "Occupant classification system: info usage ID";
CM_ SG_ 766 OCS1P_infoSubUsageID "Occupant classification system: info sub usage ID";
CM_ SG_ 766 OCS1P_infoApplicationCRC "Occupant classification system: info application CRC";
CM_ SG_ 766 OCS1P_infoBootSvnRev "Occupant classification system: info boot svn rev";
CM_ SG_ 766 OCS1P_infoAppGitHashBytes "Occupant classification system: info app git hash bytes";
CM_ SG_ 766 OCS1P_infoBootGitHashBytes "Occupant classification system: info boot git hash bytes";
CM_ SG_ 766 OCS1P_infoPlatformType "Occupant classification system: info platform type";
CM_ SG_ 766 OCS1P_infoBootUdsProtoVersion "Occupant classification system: info boot uds proto version";
CM_ SG_ 766 OCS1P_infoBootloaderCRC "Occupant classification system: info bootloader CRC";
CM_ BO_ 771 "Occupant classification system message: status";
CM_ SG_ 771 OCS1P_occupantClassification "Occupant Classification (Filtered); raw 255 = signal not available (SNA)";
CM_ SG_ 771 OCS1P_occupantClassificationQF "Occupant classification system: occupant classification QF";
CM_ SG_ 771 OCS1P_occupiedState "Passenger seat occupied State; raw 3 = signal not available (SNA)";
CM_ SG_ 771 OCS1P_triggerSnapshot "Occupant classification system: trigger snapshot";
CM_ SG_ 771 OCS1P_occupantClassificationRaw "Occupant classification system: occupant classification raw; raw 7 = signal not available (SNA)";
CM_ SG_ 771 OCS1P_occupantClassificationSelf "Occupant classification system: occupant classification self; raw 7 = signal not available (SNA)";
CM_ SG_ 771 OCS1P_occupantClassificationRawC "Occupant classification system: occupant classification raw cap; raw 7 = signal not available (SNA)";
CM_ SG_ 771 OCS1P_occupantClassificationCap "Occupant classification system: occupant classification cap; raw 7 = signal not available (SNA)";
CM_ SG_ 771 OCS1P_classificationHeld "Whether occupant classification is filtered due to door state or stability based on frequency";
CM_ SG_ 771 OCS1P_cushionStable "Whether frequency reading is unchanging of Cushion Self sensor";
CM_ SG_ 771 OCS1P_classificationExtHold "Occupant classification request to be filtered due to door state";
CM_ SG_ 771 OCS1P_classificationHoldState "Occupant classification system: classification hold state";
CM_ SG_ 771 OCS1P_classificationVariant "The combination of sensors used to classify occupant";
CM_ SG_ 771 OCS1P_sandwichDisabled "Cushion mutual sensor disabled by calibration";
CM_ SG_ 771 OCS1P_noSandwichType "Configuration set in factory or service that determines logic around uninstalled sandwich";
CM_ SG_ 771 OCS1P_sandwichBoundaryType "Occupant classification system: sandwich boundary type";
CM_ SG_ 771 OCS1P_sbrBoundaryType "Occupant classification system: sbr boundary type";
CM_ SG_ 771 OCS1P_occupiedStateCap "Occupant classification system: occupied state cap; raw 3 = signal not available (SNA)";
CM_ SG_ 771 OCS1P_seatbackStable "Whether frequency reading is unchanging of Seatback Self sensor";
CM_ SG_ 771 OCS1P_sandwichStable "Whether frequency reading is unchanging of Cushion Mutual sensor";
CM_ SG_ 771 OCS1P_cushionStableCap "Occupant classification system: cushion stable cap";
CM_ SG_ 771 OCS1P_seatbackStableCap "Occupant classification system: seatback stable cap";
CM_ SG_ 771 OCS1P_classificationHeldCap "Occupant classification system: classification held cap";
CM_ SG_ 771 OCS1P_statusCounter "Occupant classification system: status counter";
CM_ SG_ 771 OCS1P_statusChecksum "Occupant classification system: status checksum";
CM_ BO_ 1619 "Occupant classification system message: uds response";
CM_ SG_ 1619 OCS1P_udsResponseData "Occupant classification system: uds response data";
CM_ BO_ 519 "Cabin heater message: feedback status";
CM_ SG_ 519 PTC_leftFlagFault "Heater left bank fault indication flag";
CM_ SG_ 519 PTC_rightFlagFault "Heater right bank fault indication flag";
CM_ SG_ 519 PTC_leftPowerDerating "Heater left bank power derating state";
CM_ SG_ 519 PTC_rightPowerDerating "Heater right bank power derating state";
CM_ SG_ 519 PTC_ocpEvent "Indication that an over current protection event has occurred";
CM_ SG_ 519 PTC_leftDutyFeedback "Current PWM duty cycle applied to left side of PTC heater";
CM_ SG_ 519 PTC_rightDutyFeedback "Current PWM duty cycle applied to right side of PTC heater";
CM_ SG_ 519 PTC_leftPowerHV "Heater left bank power";
CM_ SG_ 519 PTC_rightPowerHV "Heater right bank power";
CM_ SG_ 519 PTC_leftTempEstOutlet "Cabin heater: left temp est outlet";
CM_ SG_ 519 PTC_rightTempEstOutlet "Cabin heater: right temp est outlet";
CM_ SG_ 519 PTC_tliErrorCount "Heater top level interrupt error count";
CM_ SG_ 519 PTC_tliEvent "Indicator of heater top level interrupt event";
CM_ SG_ 519 PTC_tliSource "Heater top level interrupt event source";
CM_ BO_ 1297 "Restraint control module message: alert log";
CM_ SG_ 1297 RCM_alertID "Restraint control module: alert ID";
CM_ SG_ 1297 RCM_alertState "Restraint control module: alert state";
CM_ SG_ 1297 RCM_a000_eventArmStatus "Restraint control module: a000 event arm status";
CM_ SG_ 1297 RCM_a000_eventFactoryMode "Restraint control module: a000 event factory mode";
CM_ SG_ 1297 RCM_a000_eventDiagEnabled "Restraint control module: a000 event diag enabled";
CM_ SG_ 1297 RCM_a000_eventDriveOrientation "Restraint control module: a000 event drive orientation";
CM_ SG_ 1297 RCM_a000_crashDetectedFront "Restraint control module: a000 crash detected front";
CM_ SG_ 1297 RCM_a000_crashDetectedRear "Restraint control module: a000 crash detected rear";
CM_ SG_ 1297 RCM_a000_crashDetectedLeft "Restraint control module: a000 crash detected left";
CM_ SG_ 1297 RCM_a000_crashDetectedRight "Restraint control module: a000 crash detected right";
CM_ SG_ 1297 RCM_a000_crashDetectedRoll "Restraint control module: a000 crash detected roll";
CM_ SG_ 1297 RCM_a000_crashDetectedPreten "Restraint control module: a000 crash detected preten";
CM_ SG_ 1297 RCM_a000_crashDetectedStage1 "Restraint control module: a000 crash detected stage1";
CM_ SG_ 1297 RCM_a000_crashDetectedStage2 "Restraint control module: a000 crash detected stage2";
CM_ SG_ 1297 RCM_a000_crashDetectedHVpyro "Restraint control module: a000 crash detected h vpyro";
CM_ SG_ 1297 RCM_a000_eventIDFsignal "Restraint control module: a000 event ID fsignal";
CM_ SG_ 1297 RCM_a000_eventFrontLeftSeatbelt "Restraint control module: a000 event front left seatbelt";
CM_ SG_ 1297 RCM_a000_eventFrontRightSeatbelt "Restraint control module: a000 event front right seatbelt";
CM_ SG_ 1297 RCM_a000_eventVehicleSpeed "Restraint control module: a000 event vehicle speed";
CM_ SG_ 1297 RCM_a000_eventSteeringAngle "Restraint control module: a000 event steering angle";
CM_ SG_ 1297 RCM_a000_eventDriverBrakeApply "Restraint control module: a000 event driver brake apply";
CM_ SG_ 1297 RCM_a000_eventAccelPedalPos "Restraint control module: a000 event accel pedal pos";
CM_ SG_ 1297 RCM_a001_eventArmStatus "Restraint control module: a001 event arm status";
CM_ SG_ 1297 RCM_a001_eventFactoryMode "Restraint control module: a001 event factory mode";
CM_ SG_ 1297 RCM_a001_eventDiagEnabled "Restraint control module: a001 event diag enabled";
CM_ SG_ 1297 RCM_a001_eventDriveOrientation "Restraint control module: a001 event drive orientation";
CM_ SG_ 1297 RCM_a001_nearDeployFront "Restraint control module: a001 near deploy front";
CM_ SG_ 1297 RCM_a001_nearDeployRear "Restraint control module: a001 near deploy rear";
CM_ SG_ 1297 RCM_a001_nearDeployLeft "Restraint control module: a001 near deploy left";
CM_ SG_ 1297 RCM_a001_nearDeployRight "Restraint control module: a001 near deploy right";
CM_ SG_ 1297 RCM_a001_nearDeployRoll "Restraint control module: a001 near deploy roll";
CM_ SG_ 1297 RCM_a001_nearDeployPretensioner "Restraint control module: a001 near deploy pretensioner";
CM_ SG_ 1297 RCM_a001_eventIDFsignal "Restraint control module: a001 event ID fsignal";
CM_ SG_ 1297 RCM_a001_eventFrontLeftSeatbelt "Restraint control module: a001 event front left seatbelt";
CM_ SG_ 1297 RCM_a001_eventFrontRightSeatbelt "Restraint control module: a001 event front right seatbelt";
CM_ SG_ 1297 RCM_a001_eventVehicleSpeed "Restraint control module: a001 event vehicle speed";
CM_ SG_ 1297 RCM_a001_eventSteeringAngle "Restraint control module: a001 event steering angle";
CM_ SG_ 1297 RCM_a001_eventDriverBrakeApply "Restraint control module: a001 event driver brake apply; raw 3 = signal not available (SNA)";
CM_ SG_ 1297 RCM_a001_eventAccelPedalPos "Restraint control module: a001 event accel pedal pos; raw 255 = signal not available (SNA)";
CM_ SG_ 1297 RCM_a002_eventArmStatus "Restraint control module: a002 event arm status";
CM_ SG_ 1297 RCM_a002_eventFactoryMode "Restraint control module: a002 event factory mode";
CM_ SG_ 1297 RCM_a002_eventDiagEnabled "Restraint control module: a002 event diag enabled";
CM_ SG_ 1297 RCM_a002_eventDriveOrientation "Restraint control module: a002 event drive orientation";
CM_ SG_ 1297 RCM_a002_airbagsUnArmed "Restraint control module: a002 airbags un armed";
CM_ SG_ 1297 RCM_a002_eventIDFsignal "Restraint control module: a002 event ID fsignal";
CM_ SG_ 1297 RCM_a002_eventFrontLeftSeatbelt "Restraint control module: a002 event front left seatbelt";
CM_ SG_ 1297 RCM_a002_eventFrontRightSeatbelt "Restraint control module: a002 event front right seatbelt";
CM_ SG_ 1297 RCM_a002_eventVehicleSpeed "Restraint control module: a002 event vehicle speed";
CM_ SG_ 1297 RCM_a002_eventSteeringAngle "Restraint control module: a002 event steering angle";
CM_ SG_ 1297 RCM_a002_eventDriverBrakeApply "Restraint control module: a002 event driver brake apply; raw 3 = signal not available (SNA)";
CM_ SG_ 1297 RCM_a002_eventAccelPedalPos "Restraint control module: a002 event accel pedal pos; raw 255 = signal not available (SNA)";
CM_ SG_ 1297 RCM_a003_eventArmStatus "Restraint control module: a003 event arm status";
CM_ SG_ 1297 RCM_a003_eventFactoryMode "Restraint control module: a003 event factory mode";
CM_ SG_ 1297 RCM_a003_eventDiagEnabled "Restraint control module: a003 event diag enabled";
CM_ SG_ 1297 RCM_a003_eventDriveOrientation "Restraint control module: a003 event drive orientation";
CM_ SG_ 1297 RCM_a003_warningIndicatorOn "Restraint control module: a003 warning indicator on";
CM_ SG_ 1297 RCM_a003_eventIDFsignal "Restraint control module: a003 event ID fsignal";
CM_ SG_ 1297 RCM_a003_eventFrontLeftSeatbelt "Restraint control module: a003 event front left seatbelt";
CM_ SG_ 1297 RCM_a003_eventFrontRightSeatbelt "Restraint control module: a003 event front right seatbelt";
CM_ SG_ 1297 RCM_a003_eventVehicleSpeed "Restraint control module: a003 event vehicle speed";
CM_ SG_ 1297 RCM_a003_eventSteeringAngle "Restraint control module: a003 event steering angle";
CM_ SG_ 1297 RCM_a003_eventDriverBrakeApply "Restraint control module: a003 event driver brake apply; raw 3 = signal not available (SNA)";
CM_ SG_ 1297 RCM_a003_eventAccelPedalPos "Restraint control module: a003 event accel pedal pos; raw 255 = signal not available (SNA)";
CM_ SG_ 1297 RCM_a004_eventArmStatus "Restraint control module: a004 event arm status";
CM_ SG_ 1297 RCM_a004_eventFactoryMode "Restraint control module: a004 event factory mode";
CM_ SG_ 1297 RCM_a004_eventDiagEnabled "Restraint control module: a004 event diag enabled";
CM_ SG_ 1297 RCM_a004_eventDriveOrientation "Restraint control module: a004 event drive orientation";
CM_ SG_ 1297 RCM_a004_frontAlgoDisabled "Restraint control module: a004 front algo disabled";
CM_ SG_ 1297 RCM_a004_sideAlgoDisabled "Restraint control module: a004 side algo disabled";
CM_ SG_ 1297 RCM_a004_rollAlgoDisabled "Restraint control module: a004 roll algo disabled";
CM_ SG_ 1297 RCM_a004_idleMode "Restraint control module: a004 idle mode";
CM_ SG_ 1297 RCM_a004_internalFaultDetected "Restraint control module: a004 internal fault detected";
CM_ SG_ 1297 RCM_a004_swVersionMismatch "Restraint control module: a004 sw version mismatch";
CM_ SG_ 1297 RCM_a004_paramLayoutIDInv "Restraint control module: a004 param layout ID inv";
CM_ SG_ 1297 RCM_a004_algoPASIDMismatch "Restraint control module: a004 algo PASID mismatch";
CM_ SG_ 1297 RCM_a004_eventIDFsignal "Restraint control module: a004 event ID fsignal";
CM_ SG_ 1297 RCM_a004_eventFrontLeftSeatbelt "Restraint control module: a004 event front left seatbelt";
CM_ SG_ 1297 RCM_a004_eventFrontRightSeatbelt "Restraint control module: a004 event front right seatbelt";
CM_ SG_ 1297 RCM_a004_eventVehicleSpeed "Restraint control module: a004 event vehicle speed";
CM_ SG_ 1297 RCM_a004_eventSteeringAngle "Restraint control module: a004 event steering angle";
CM_ SG_ 1297 RCM_a004_eventDriverBrakeApply "Restraint control module: a004 event driver brake apply; raw 3 = signal not available (SNA)";
CM_ SG_ 1297 RCM_a004_eventAccelPedalPos "Restraint control module: a004 event accel pedal pos; raw 255 = signal not available (SNA)";
CM_ SG_ 1297 RCM_a005_eventArmStatus "Restraint control module: a005 event arm status";
CM_ SG_ 1297 RCM_a005_eventFactoryMode "Restraint control module: a005 event factory mode";
CM_ SG_ 1297 RCM_a005_eventDiagEnabled "Restraint control module: a005 event diag enabled";
CM_ SG_ 1297 RCM_a005_eventDriveOrientation "Restraint control module: a005 event drive orientation";
CM_ SG_ 1297 RCM_a005_externalCRCError "Restraint control module: a005 external CRC error";
CM_ SG_ 1297 RCM_a005_eventIDFsignal "Restraint control module: a005 event ID fsignal";
CM_ SG_ 1297 RCM_a005_eventFrontLeftSeatbelt "Restraint control module: a005 event front left seatbelt";
CM_ SG_ 1297 RCM_a005_eventFrontRightSeatbelt "Restraint control module: a005 event front right seatbelt";
CM_ SG_ 1297 RCM_a005_eventVehicleSpeed "Restraint control module: a005 event vehicle speed";
CM_ SG_ 1297 RCM_a005_eventSteeringAngle "Restraint control module: a005 event steering angle";
CM_ SG_ 1297 RCM_a005_eventDriverBrakeApply "Restraint control module: a005 event driver brake apply; raw 3 = signal not available (SNA)";
CM_ SG_ 1297 RCM_a005_eventAccelPedalPos "Restraint control module: a005 event accel pedal pos; raw 255 = signal not available (SNA)";
CM_ SG_ 1297 RCM_a006_eventArmStatus "Restraint control module: a006 event arm status";
CM_ SG_ 1297 RCM_a006_eventFactoryMode "Restraint control module: a006 event factory mode";
CM_ SG_ 1297 RCM_a006_eventDiagEnabled "Restraint control module: a006 event diag enabled";
CM_ SG_ 1297 RCM_a006_eventDriveOrientation "Restraint control module: a006 event drive orientation";
CM_ SG_ 1297 RCM_a006_batteryVoltageTooHigh "Restraint control module: a006 battery voltage too high";
CM_ SG_ 1297 RCM_a006_batteryVoltageTooLow "Restraint control module: a006 battery voltage too low";
CM_ SG_ 1297 RCM_a006_eventIDFsignal "Restraint control module: a006 event ID fsignal";
CM_ SG_ 1297 RCM_a006_eventFrontLeftSeatbelt "Restraint control module: a006 event front left seatbelt";
CM_ SG_ 1297 RCM_a006_eventFrontRightSeatbelt "Restraint control module: a006 event front right seatbelt";
CM_ SG_ 1297 RCM_a006_eventVehicleSpeed "Restraint control module: a006 event vehicle speed";
CM_ SG_ 1297 RCM_a006_eventSteeringAngle "Restraint control module: a006 event steering angle";
CM_ SG_ 1297 RCM_a006_eventDriverBrakeApply "Restraint control module: a006 event driver brake apply; raw 3 = signal not available (SNA)";
CM_ SG_ 1297 RCM_a006_eventAccelPedalPos "Restraint control module: a006 event accel pedal pos; raw 255 = signal not available (SNA)";
CM_ SG_ 1297 RCM_a008_eventArmStatus "Restraint control module: a008 event arm status";
CM_ SG_ 1297 RCM_a008_eventFactoryMode "Restraint control module: a008 event factory mode";
CM_ SG_ 1297 RCM_a008_eventDiagEnabled "Restraint control module: a008 event diag enabled";
CM_ SG_ 1297 RCM_a008_eventDriveOrientation "Restraint control module: a008 event drive orientation";
CM_ SG_ 1297 RCM_a008_lossOfMainPwrSupMonit "Restraint control module: a008 loss of main pwr sup monit";
CM_ SG_ 1297 RCM_a008_lossOfBckupPwrSupMonit "Restraint control module: a008 loss of bckup pwr sup monit";
CM_ SG_ 1297 RCM_a008_normalShtdwnUnavail "Restraint control module: a008 normal shtdwn unavail";
CM_ SG_ 1297 RCM_a008_eventIDFsignal "Restraint control module: a008 event ID fsignal";
CM_ SG_ 1297 RCM_a008_eventFrontLeftSeatbelt "Restraint control module: a008 event front left seatbelt";
CM_ SG_ 1297 RCM_a008_eventFrontRightSeatbelt "Restraint control module: a008 event front right seatbelt";
CM_ SG_ 1297 RCM_a008_eventVehicleSpeed "Restraint control module: a008 event vehicle speed";
CM_ SG_ 1297 RCM_a008_eventSteeringAngle "Restraint control module: a008 event steering angle";
CM_ SG_ 1297 RCM_a008_eventDriverBrakeApply "Restraint control module: a008 event driver brake apply; raw 3 = signal not available (SNA)";
CM_ SG_ 1297 RCM_a008_eventAccelPedalPos "Restraint control module: a008 event accel pedal pos; raw 255 = signal not available (SNA)";
CM_ SG_ 1297 RCM_a009_eventArmStatus "Restraint control module: a009 event arm status";
CM_ SG_ 1297 RCM_a009_eventFactoryMode "Restraint control module: a009 event factory mode";
CM_ SG_ 1297 RCM_a009_eventDiagEnabled "Restraint control module: a009 event diag enabled";
CM_ SG_ 1297 RCM_a009_eventDriveOrientation "Restraint control module: a009 event drive orientation";
CM_ SG_ 1297 RCM_a009_reprogramLimitExceeded "Restraint control module: a009 reprogram limit exceeded";
CM_ SG_ 1297 RCM_a009_eventIDFsignal "Restraint control module: a009 event ID fsignal";
CM_ SG_ 1297 RCM_a009_eventFrontLeftSeatbelt "Restraint control module: a009 event front left seatbelt";
CM_ SG_ 1297 RCM_a009_eventFrontRightSeatbelt "Restraint control module: a009 event front right seatbelt";
CM_ SG_ 1297 RCM_a009_eventVehicleSpeed "Restraint control module: a009 event vehicle speed";
CM_ SG_ 1297 RCM_a009_eventSteeringAngle "Restraint control module: a009 event steering angle";
CM_ SG_ 1297 RCM_a009_eventDriverBrakeApply "Restraint control module: a009 event driver brake apply; raw 3 = signal not available (SNA)";
CM_ SG_ 1297 RCM_a009_eventAccelPedalPos "Restraint control module: a009 event accel pedal pos; raw 255 = signal not available (SNA)";
CM_ SG_ 1297 RCM_a011_eventArmStatus "Restraint control module: a011 event arm status";
CM_ SG_ 1297 RCM_a011_eventFactoryMode "Restraint control module: a011 event factory mode";
CM_ SG_ 1297 RCM_a011_eventDiagEnabled "Restraint control module: a011 event diag enabled";
CM_ SG_ 1297 RCM_a011_eventDriveOrientation "Restraint control module: a011 event drive orientation";
CM_ SG_ 1297 RCM_a011_edrDataAreaLocked "Restraint control module: a011 edr data area locked";
CM_ SG_ 1297 RCM_a011_eventIDFsignal "Restraint control module: a011 event ID fsignal";
CM_ SG_ 1297 RCM_a011_eventFrontLeftSeatbelt "Restraint control module: a011 event front left seatbelt";
CM_ SG_ 1297 RCM_a011_eventFrontRightSeatbelt "Restraint control module: a011 event front right seatbelt";
CM_ SG_ 1297 RCM_a011_eventVehicleSpeed "Restraint control module: a011 event vehicle speed";
CM_ SG_ 1297 RCM_a011_eventSteeringAngle "Restraint control module: a011 event steering angle";
CM_ SG_ 1297 RCM_a011_eventDriverBrakeApply "Restraint control module: a011 event driver brake apply; raw 3 = signal not available (SNA)";
CM_ SG_ 1297 RCM_a011_eventAccelPedalPos "Restraint control module: a011 event accel pedal pos; raw 255 = signal not available (SNA)";
CM_ SG_ 1297 RCM_a012_eventArmStatus "Restraint control module: a012 event arm status";
CM_ SG_ 1297 RCM_a012_eventFactoryMode "Restraint control module: a012 event factory mode";
CM_ SG_ 1297 RCM_a012_eventDiagEnabled "Restraint control module: a012 event diag enabled";
CM_ SG_ 1297 RCM_a012_eventDriveOrientation "Restraint control module: a012 event drive orientation";
CM_ SG_ 1297 RCM_a012_vinMismatch "Restraint control module: a012 vin mismatch";
CM_ SG_ 1297 RCM_a012_vinNotProgrammed "Restraint control module: a012 vin not programmed";
CM_ SG_ 1297 RCM_a012_eventIDFsignal "Restraint control module: a012 event ID fsignal";
CM_ SG_ 1297 RCM_a012_eventFrontLeftSeatbelt "Restraint control module: a012 event front left seatbelt";
CM_ SG_ 1297 RCM_a012_eventFrontRightSeatbelt "Restraint control module: a012 event front right seatbelt";
CM_ SG_ 1297 RCM_a012_eventVehicleSpeed "Restraint control module: a012 event vehicle speed";
CM_ SG_ 1297 RCM_a012_eventSteeringAngle "Restraint control module: a012 event steering angle";
CM_ SG_ 1297 RCM_a012_eventDriverBrakeApply "Restraint control module: a012 event driver brake apply; raw 3 = signal not available (SNA)";
CM_ SG_ 1297 RCM_a012_eventAccelPedalPos "Restraint control module: a012 event accel pedal pos; raw 255 = signal not available (SNA)";
CM_ SG_ 1297 RCM_a013_eventArmStatus "Restraint control module: a013 event arm status";
CM_ SG_ 1297 RCM_a013_eventFactoryMode "Restraint control module: a013 event factory mode";
CM_ SG_ 1297 RCM_a013_eventDiagEnabled "Restraint control module: a013 event diag enabled";
CM_ SG_ 1297 RCM_a013_eventDriveOrientation "Restraint control module: a013 event drive orientation";
CM_ SG_ 1297 RCM_a013_driveOrientiInitNotDone "Restraint control module: a013 drive orienti init not done";
CM_ SG_ 1297 RCM_a013_driveOrientPlausiCheck "Restraint control module: a013 drive orient plausi check";
CM_ SG_ 1297 RCM_a013_eventIDFsignal "Restraint control module: a013 event ID fsignal";
CM_ SG_ 1297 RCM_a013_eventFrontLeftSeatbelt "Restraint control module: a013 event front left seatbelt";
CM_ SG_ 1297 RCM_a013_eventFrontRightSeatbelt "Restraint control module: a013 event front right seatbelt";
CM_ SG_ 1297 RCM_a013_eventVehicleSpeed "Restraint control module: a013 event vehicle speed";
CM_ SG_ 1297 RCM_a013_eventSteeringAngle "Restraint control module: a013 event steering angle";
CM_ SG_ 1297 RCM_a013_eventDriverBrakeApply "Restraint control module: a013 event driver brake apply; raw 3 = signal not available (SNA)";
CM_ SG_ 1297 RCM_a013_eventAccelPedalPos "Restraint control module: a013 event accel pedal pos; raw 255 = signal not available (SNA)";
CM_ SG_ 1297 RCM_a014_eventArmStatus "Restraint control module: a014 event arm status";
CM_ SG_ 1297 RCM_a014_eventFactoryMode "Restraint control module: a014 event factory mode";
CM_ SG_ 1297 RCM_a014_eventDiagEnabled "Restraint control module: a014 event diag enabled";
CM_ SG_ 1297 RCM_a014_eventDriveOrientation "Restraint control module: a014 event drive orientation";
CM_ SG_ 1297 RCM_a014_driverABStg1Sht2Gnd "Restraint control module: a014 driver AB stg1 sht2 gnd";
CM_ SG_ 1297 RCM_a014_driverABStg1Sht2Bat "Restraint control module: a014 driver AB stg1 sht2 bat";
CM_ SG_ 1297 RCM_a014_driverABStg1Open "Restraint control module: a014 driver AB stg1 open";
CM_ SG_ 1297 RCM_a014_driverABStg1Short "Restraint control module: a014 driver AB stg1 short";
CM_ SG_ 1297 RCM_a014_driverABStg1CrossCoup "Restraint control module: a014 driver AB stg1 cross coup";
CM_ SG_ 1297 RCM_a014_driverABStg1Config "Restraint control module: a014 driver AB stg1 config";
CM_ SG_ 1297 RCM_a014_eventIDFsignal "Restraint control module: a014 event ID fsignal";
CM_ SG_ 1297 RCM_a014_eventFrontLeftSeatbelt "Restraint control module: a014 event front left seatbelt";
CM_ SG_ 1297 RCM_a014_eventFrontRightSeatbelt "Restraint control module: a014 event front right seatbelt";
CM_ SG_ 1297 RCM_a014_eventVehicleSpeed "Restraint control module: a014 event vehicle speed";
CM_ SG_ 1297 RCM_a014_eventSteeringAngle "Restraint control module: a014 event steering angle";
CM_ SG_ 1297 RCM_a014_eventDriverBrakeApply "Restraint control module: a014 event driver brake apply; raw 3 = signal not available (SNA)";
CM_ SG_ 1297 RCM_a014_eventAccelPedalPos "Restraint control module: a014 event accel pedal pos; raw 255 = signal not available (SNA)";
CM_ SG_ 1297 RCM_a015_eventArmStatus "Restraint control module: a015 event arm status";
CM_ SG_ 1297 RCM_a015_eventFactoryMode "Restraint control module: a015 event factory mode";
CM_ SG_ 1297 RCM_a015_eventDiagEnabled "Restraint control module: a015 event diag enabled";
CM_ SG_ 1297 RCM_a015_eventDriveOrientation "Restraint control module: a015 event drive orientation";
CM_ SG_ 1297 RCM_a015_driverABStg2Sht2Gnd "Restraint control module: a015 driver AB stg2 sht2 gnd";
CM_ SG_ 1297 RCM_a015_driverABStg2Sht2Bat "Restraint control module: a015 driver AB stg2 sht2 bat";
CM_ SG_ 1297 RCM_a015_driverABStg2Open "Restraint control module: a015 driver AB stg2 open";
CM_ SG_ 1297 RCM_a015_driverABStg2Short "Restraint control module: a015 driver AB stg2 short";
CM_ SG_ 1297 RCM_a015_driverABStg2CrossCoup "Restraint control module: a015 driver AB stg2 cross coup";
CM_ SG_ 1297 RCM_a015_driverABStg2Config "Restraint control module: a015 driver AB stg2 config";
CM_ SG_ 1297 RCM_a015_eventIDFsignal "Restraint control module: a015 event ID fsignal";
CM_ SG_ 1297 RCM_a015_eventFrontLeftSeatbelt "Restraint control module: a015 event front left seatbelt";
CM_ SG_ 1297 RCM_a015_eventFrontRightSeatbelt "Restraint control module: a015 event front right seatbelt";
CM_ SG_ 1297 RCM_a015_eventVehicleSpeed "Restraint control module: a015 event vehicle speed";
CM_ SG_ 1297 RCM_a015_eventSteeringAngle "Restraint control module: a015 event steering angle";
CM_ SG_ 1297 RCM_a015_eventDriverBrakeApply "Restraint control module: a015 event driver brake apply; raw 3 = signal not available (SNA)";
CM_ SG_ 1297 RCM_a015_eventAccelPedalPos "Restraint control module: a015 event accel pedal pos; raw 255 = signal not available (SNA)";
CM_ SG_ 1297 RCM_a016_eventArmStatus "Restraint control module: a016 event arm status";
CM_ SG_ 1297 RCM_a016_eventFactoryMode "Restraint control module: a016 event factory mode";
CM_ SG_ 1297 RCM_a016_eventDiagEnabled "Restraint control module: a016 event diag enabled";
CM_ SG_ 1297 RCM_a016_eventDriveOrientation "Restraint control module: a016 event drive orientation";
CM_ SG_ 1297 RCM_a016_passABStg1Sht2Gnd "Restraint control module: a016 pass AB stg1 sht2 gnd";
CM_ SG_ 1297 RCM_a016_passABStg1Sht2Bat "Restraint control module: a016 pass AB stg1 sht2 bat";
CM_ SG_ 1297 RCM_a016_passABStg1Open "Restraint control module: a016 pass AB stg1 open";
CM_ SG_ 1297 RCM_a016_passABStg1Short "Restraint control module: a016 pass AB stg1 short";
CM_ SG_ 1297 RCM_a016_passABStg1CrossCoup "Restraint control module: a016 pass AB stg1 cross coup";
CM_ SG_ 1297 RCM_a016_passABStg1Config "Restraint control module: a016 pass AB stg1 config";
CM_ SG_ 1297 RCM_a016_eventIDFsignal "Restraint control module: a016 event ID fsignal";
CM_ SG_ 1297 RCM_a016_eventFrontLeftSeatbelt "Restraint control module: a016 event front left seatbelt";
CM_ SG_ 1297 RCM_a016_eventFrontRightSeatbelt "Restraint control module: a016 event front right seatbelt";
CM_ SG_ 1297 RCM_a016_eventVehicleSpeed "Restraint control module: a016 event vehicle speed";
CM_ SG_ 1297 RCM_a016_eventSteeringAngle "Restraint control module: a016 event steering angle";
CM_ SG_ 1297 RCM_a016_eventDriverBrakeApply "Restraint control module: a016 event driver brake apply; raw 3 = signal not available (SNA)";
CM_ SG_ 1297 RCM_a016_eventAccelPedalPos "Restraint control module: a016 event accel pedal pos; raw 255 = signal not available (SNA)";
CM_ SG_ 1297 RCM_a017_eventArmStatus "Restraint control module: a017 event arm status";
CM_ SG_ 1297 RCM_a017_eventFactoryMode "Restraint control module: a017 event factory mode";
CM_ SG_ 1297 RCM_a017_eventDiagEnabled "Restraint control module: a017 event diag enabled";
CM_ SG_ 1297 RCM_a017_eventDriveOrientation "Restraint control module: a017 event drive orientation";
CM_ SG_ 1297 RCM_a017_passABStg2Sht2Gnd "Restraint control module: a017 pass AB stg2 sht2 gnd";
CM_ SG_ 1297 RCM_a017_passABStg2Sht2Bat "Restraint control module: a017 pass AB stg2 sht2 bat";
CM_ SG_ 1297 RCM_a017_passABStg2Open "Restraint control module: a017 pass AB stg2 open";
CM_ SG_ 1297 RCM_a017_passABStg2Short "Restraint control module: a017 pass AB stg2 short";
CM_ SG_ 1297 RCM_a017_passABStg2CrossCoup "Restraint control module: a017 pass AB stg2 cross coup";
CM_ SG_ 1297 RCM_a017_passABStg2Config "Restraint control module: a017 pass AB stg2 config";
CM_ SG_ 1297 RCM_a017_eventIDFsignal "Restraint control module: a017 event ID fsignal";
CM_ SG_ 1297 RCM_a017_eventFrontLeftSeatbelt "Restraint control module: a017 event front left seatbelt";
CM_ SG_ 1297 RCM_a017_eventFrontRightSeatbelt "Restraint control module: a017 event front right seatbelt";
CM_ SG_ 1297 RCM_a017_eventVehicleSpeed "Restraint control module: a017 event vehicle speed";
CM_ SG_ 1297 RCM_a017_eventSteeringAngle "Restraint control module: a017 event steering angle";
CM_ SG_ 1297 RCM_a017_eventDriverBrakeApply "Restraint control module: a017 event driver brake apply; raw 3 = signal not available (SNA)";
CM_ SG_ 1297 RCM_a017_eventAccelPedalPos "Restraint control module: a017 event accel pedal pos; raw 255 = signal not available (SNA)";
CM_ SG_ 1297 RCM_a018_eventArmStatus "Restraint control module: a018 event arm status";
CM_ SG_ 1297 RCM_a018_eventFactoryMode "Restraint control module: a018 event factory mode";
CM_ SG_ 1297 RCM_a018_eventDiagEnabled "Restraint control module: a018 event diag enabled";
CM_ SG_ 1297 RCM_a018_eventDriveOrientation "Restraint control module: a018 event drive orientation";
CM_ SG_ 1297 RCM_a018_passActiveVentSht2Gnd "Restraint control module: a018 pass active vent sht2 gnd";
CM_ SG_ 1297 RCM_a018_passActiveVentSht2Bat "Restraint control module: a018 pass active vent sht2 bat";
CM_ SG_ 1297 RCM_a018_passActiveVentOpen "Restraint control module: a018 pass active vent open";
CM_ SG_ 1297 RCM_a018_passActiveVentShort "Restraint control module: a018 pass active vent short";
CM_ SG_ 1297 RCM_a018_passActiveVentCrossCoup "Restraint control module: a018 pass active vent cross coup";
CM_ SG_ 1297 RCM_a018_passActiveVentConfig "Restraint control module: a018 pass active vent config";
CM_ SG_ 1297 RCM_a018_eventIDFsignal "Restraint control module: a018 event ID fsignal";
CM_ SG_ 1297 RCM_a018_eventFrontLeftSeatbelt "Restraint control module: a018 event front left seatbelt";
CM_ SG_ 1297 RCM_a018_eventFrontRightSeatbelt "Restraint control module: a018 event front right seatbelt";
CM_ SG_ 1297 RCM_a018_eventVehicleSpeed "Restraint control module: a018 event vehicle speed";
CM_ SG_ 1297 RCM_a018_eventSteeringAngle "Restraint control module: a018 event steering angle";
CM_ SG_ 1297 RCM_a018_eventDriverBrakeApply "Restraint control module: a018 event driver brake apply; raw 3 = signal not available (SNA)";
CM_ SG_ 1297 RCM_a018_eventAccelPedalPos "Restraint control module: a018 event accel pedal pos; raw 255 = signal not available (SNA)";
CM_ SG_ 1297 RCM_a019_eventArmStatus "Restraint control module: a019 event arm status";
CM_ SG_ 1297 RCM_a019_eventFactoryMode "Restraint control module: a019 event factory mode";
CM_ SG_ 1297 RCM_a019_eventDiagEnabled "Restraint control module: a019 event diag enabled";
CM_ SG_ 1297 RCM_a019_eventDriveOrientation "Restraint control module: a019 event drive orientation";
CM_ SG_ 1297 RCM_a019_pretenShldLeftSht2Gnd "Restraint control module: a019 preten shld left sht2 gnd";
CM_ SG_ 1297 RCM_a019_pretenShldLeftSht2Bat "Restraint control module: a019 preten shld left sht2 bat";
CM_ SG_ 1297 RCM_a019_pretenShldLeftOpen "Restraint control module: a019 preten shld left open";
CM_ SG_ 1297 RCM_a019_pretenShldLeftShort "Restraint control module: a019 preten shld left short";
CM_ SG_ 1297 RCM_a019_pretenShldLeftCrossC "Restraint control module: a019 preten shld left cross c";
CM_ SG_ 1297 RCM_a019_pretenShldLeftConfig "Restraint control module: a019 preten shld left config";
CM_ SG_ 1297 RCM_a019_eventIDFsignal "Restraint control module: a019 event ID fsignal";
CM_ SG_ 1297 RCM_a019_eventFrontLeftSeatbelt "Restraint control module: a019 event front left seatbelt";
CM_ SG_ 1297 RCM_a019_eventFrontRightSeatbelt "Restraint control module: a019 event front right seatbelt";
CM_ SG_ 1297 RCM_a019_eventVehicleSpeed "Restraint control module: a019 event vehicle speed";
CM_ SG_ 1297 RCM_a019_eventSteeringAngle "Restraint control module: a019 event steering angle";
CM_ SG_ 1297 RCM_a019_eventDriverBrakeApply "Restraint control module: a019 event driver brake apply; raw 3 = signal not available (SNA)";
CM_ SG_ 1297 RCM_a019_eventAccelPedalPos "Restraint control module: a019 event accel pedal pos; raw 255 = signal not available (SNA)";
CM_ SG_ 1297 RCM_a020_eventArmStatus "Restraint control module: a020 event arm status";
CM_ SG_ 1297 RCM_a020_eventFactoryMode "Restraint control module: a020 event factory mode";
CM_ SG_ 1297 RCM_a020_eventDiagEnabled "Restraint control module: a020 event diag enabled";
CM_ SG_ 1297 RCM_a020_eventDriveOrientation "Restraint control module: a020 event drive orientation";
CM_ SG_ 1297 RCM_a020_pretenShldRightSht2Gnd "Restraint control module: a020 preten shld right sht2 gnd";
CM_ SG_ 1297 RCM_a020_pretenShldRightSht2Bat "Restraint control module: a020 preten shld right sht2 bat";
CM_ SG_ 1297 RCM_a020_pretenShldRightOpen "Restraint control module: a020 preten shld right open";
CM_ SG_ 1297 RCM_a020_pretenShldRightShort "Restraint control module: a020 preten shld right short";
CM_ SG_ 1297 RCM_a020_pretenShldRightCrossC "Restraint control module: a020 preten shld right cross c";
CM_ SG_ 1297 RCM_a020_pretenShldRightConfig "Restraint control module: a020 preten shld right config";
CM_ SG_ 1297 RCM_a020_eventIDFsignal "Restraint control module: a020 event ID fsignal";
CM_ SG_ 1297 RCM_a020_eventFrontLeftSeatbelt "Restraint control module: a020 event front left seatbelt";
CM_ SG_ 1297 RCM_a020_eventFrontRightSeatbelt "Restraint control module: a020 event front right seatbelt";
CM_ SG_ 1297 RCM_a020_eventVehicleSpeed "Restraint control module: a020 event vehicle speed";
CM_ SG_ 1297 RCM_a020_eventSteeringAngle "Restraint control module: a020 event steering angle";
CM_ SG_ 1297 RCM_a020_eventDriverBrakeApply "Restraint control module: a020 event driver brake apply; raw 3 = signal not available (SNA)";
CM_ SG_ 1297 RCM_a020_eventAccelPedalPos "Restraint control module: a020 event accel pedal pos; raw 255 = signal not available (SNA)";
CM_ SG_ 1297 RCM_a021_eventArmStatus "Restraint control module: a021 event arm status";
CM_ SG_ 1297 RCM_a021_eventFactoryMode "Restraint control module: a021 event factory mode";
CM_ SG_ 1297 RCM_a021_eventDiagEnabled "Restraint control module: a021 event diag enabled";
CM_ SG_ 1297 RCM_a021_eventDriveOrientation "Restraint control module: a021 event drive orientation";
CM_ SG_ 1297 RCM_a021_pretenLapLeftSht2Gnd "Restraint control module: a021 preten lap left sht2 gnd";
CM_ SG_ 1297 RCM_a021_pretenLapLeftSht2Bat "Restraint control module: a021 preten lap left sht2 bat";
CM_ SG_ 1297 RCM_a021_pretenLapLeftOpen "Restraint control module: a021 preten lap left open";
CM_ SG_ 1297 RCM_a021_pretenLapLeftShort "Restraint control module: a021 preten lap left short";
CM_ SG_ 1297 RCM_a021_pretenLapLeftCrossCoup "Restraint control module: a021 preten lap left cross coup";
CM_ SG_ 1297 RCM_a021_pretenLapLeftConfig "Restraint control module: a021 preten lap left config";
CM_ SG_ 1297 RCM_a021_eventIDFsignal "Restraint control module: a021 event ID fsignal";
CM_ SG_ 1297 RCM_a021_eventFrontLeftSeatbelt "Restraint control module: a021 event front left seatbelt";
CM_ SG_ 1297 RCM_a021_eventFrontRightSeatbelt "Restraint control module: a021 event front right seatbelt";
CM_ SG_ 1297 RCM_a021_eventVehicleSpeed "Restraint control module: a021 event vehicle speed";
CM_ SG_ 1297 RCM_a021_eventSteeringAngle "Restraint control module: a021 event steering angle";
CM_ SG_ 1297 RCM_a021_eventDriverBrakeApply "Restraint control module: a021 event driver brake apply; raw 3 = signal not available (SNA)";
CM_ SG_ 1297 RCM_a021_eventAccelPedalPos "Restraint control module: a021 event accel pedal pos; raw 255 = signal not available (SNA)";
CM_ SG_ 1297 RCM_a022_eventArmStatus "Restraint control module: a022 event arm status";
CM_ SG_ 1297 RCM_a022_eventFactoryMode "Restraint control module: a022 event factory mode";
CM_ SG_ 1297 RCM_a022_eventDiagEnabled "Restraint control module: a022 event diag enabled";
CM_ SG_ 1297 RCM_a022_eventDriveOrientation "Restraint control module: a022 event drive orientation";
CM_ SG_ 1297 RCM_a022_pretenLapRightSht2Gnd "Restraint control module: a022 preten lap right sht2 gnd";
CM_ SG_ 1297 RCM_a022_pretenLapRightSht2Bat "Restraint control module: a022 preten lap right sht2 bat";
CM_ SG_ 1297 RCM_a022_pretenLapRightOpen "Restraint control module: a022 preten lap right open";
CM_ SG_ 1297 RCM_a022_pretenLapRightShort "Restraint control module: a022 preten lap right short";
CM_ SG_ 1297 RCM_a022_pretenLapRightCrossCoup "Restraint control module: a022 preten lap right cross coup";
CM_ SG_ 1297 RCM_a022_pretenLapRightConfig "Restraint control module: a022 preten lap right config";
CM_ SG_ 1297 RCM_a022_eventIDFsignal "Restraint control module: a022 event ID fsignal";
CM_ SG_ 1297 RCM_a022_eventFrontLeftSeatbelt "Restraint control module: a022 event front left seatbelt";
CM_ SG_ 1297 RCM_a022_eventFrontRightSeatbelt "Restraint control module: a022 event front right seatbelt";
CM_ SG_ 1297 RCM_a022_eventVehicleSpeed "Restraint control module: a022 event vehicle speed";
CM_ SG_ 1297 RCM_a022_eventSteeringAngle "Restraint control module: a022 event steering angle";
CM_ SG_ 1297 RCM_a022_eventDriverBrakeApply "Restraint control module: a022 event driver brake apply; raw 3 = signal not available (SNA)";
CM_ SG_ 1297 RCM_a022_eventAccelPedalPos "Restraint control module: a022 event accel pedal pos; raw 255 = signal not available (SNA)";
CM_ SG_ 1297 RCM_a023_eventArmStatus "Restraint control module: a023 event arm status";
CM_ SG_ 1297 RCM_a023_eventFactoryMode "Restraint control module: a023 event factory mode";
CM_ SG_ 1297 RCM_a023_eventDiagEnabled "Restraint control module: a023 event diag enabled";
CM_ SG_ 1297 RCM_a023_eventDriveOrientation "Restraint control module: a023 event drive orientation";
CM_ SG_ 1297 RCM_a023_loadLimLeftSht2Gnd "Restraint control module: a023 load lim left sht2 gnd";
CM_ SG_ 1297 RCM_a023_loadLimLeftSht2Bat "Restraint control module: a023 load lim left sht2 bat";
CM_ SG_ 1297 RCM_a023_loadLimLeftOpen "Restraint control module: a023 load lim left open";
CM_ SG_ 1297 RCM_a023_loadLimLeftShort "Restraint control module: a023 load lim left short";
CM_ SG_ 1297 RCM_a023_loadLimLeftCrossCoup "Restraint control module: a023 load lim left cross coup";
CM_ SG_ 1297 RCM_a023_loadLimLeftConfig "Restraint control module: a023 load lim left config";
CM_ SG_ 1297 RCM_a023_eventIDFsignal "Restraint control module: a023 event ID fsignal";
CM_ SG_ 1297 RCM_a023_eventFrontLeftSeatbelt "Restraint control module: a023 event front left seatbelt";
CM_ SG_ 1297 RCM_a023_eventFrontRightSeatbelt "Restraint control module: a023 event front right seatbelt";
CM_ SG_ 1297 RCM_a023_eventVehicleSpeed "Restraint control module: a023 event vehicle speed";
CM_ SG_ 1297 RCM_a023_eventSteeringAngle "Restraint control module: a023 event steering angle";
CM_ SG_ 1297 RCM_a023_eventDriverBrakeApply "Restraint control module: a023 event driver brake apply; raw 3 = signal not available (SNA)";
CM_ SG_ 1297 RCM_a023_eventAccelPedalPos "Restraint control module: a023 event accel pedal pos; raw 255 = signal not available (SNA)";
CM_ SG_ 1297 RCM_a024_eventArmStatus "Restraint control module: a024 event arm status";
CM_ SG_ 1297 RCM_a024_eventFactoryMode "Restraint control module: a024 event factory mode";
CM_ SG_ 1297 RCM_a024_eventDiagEnabled "Restraint control module: a024 event diag enabled";
CM_ SG_ 1297 RCM_a024_eventDriveOrientation "Restraint control module: a024 event drive orientation";
CM_ SG_ 1297 RCM_a024_loadLimRightSht2Gnd "Restraint control module: a024 load lim right sht2 gnd";
CM_ SG_ 1297 RCM_a024_loadLimRightSht2Bat "Restraint control module: a024 load lim right sht2 bat";
CM_ SG_ 1297 RCM_a024_loadLimRightOpen "Restraint control module: a024 load lim right open";
CM_ SG_ 1297 RCM_a024_loadLimRightShort "Restraint control module: a024 load lim right short";
CM_ SG_ 1297 RCM_a024_loadLimRightCrossCoup "Restraint control module: a024 load lim right cross coup";
CM_ SG_ 1297 RCM_a024_loadLimRightConfig "Restraint control module: a024 load lim right config";
CM_ SG_ 1297 RCM_a024_eventIDFsignal "Restraint control module: a024 event ID fsignal";
CM_ SG_ 1297 RCM_a024_eventFrontLeftSeatbelt "Restraint control module: a024 event front left seatbelt";
CM_ SG_ 1297 RCM_a024_eventFrontRightSeatbelt "Restraint control module: a024 event front right seatbelt";
CM_ SG_ 1297 RCM_a024_eventVehicleSpeed "Restraint control module: a024 event vehicle speed";
CM_ SG_ 1297 RCM_a024_eventSteeringAngle "Restraint control module: a024 event steering angle";
CM_ SG_ 1297 RCM_a024_eventDriverBrakeApply "Restraint control module: a024 event driver brake apply; raw 3 = signal not available (SNA)";
CM_ SG_ 1297 RCM_a024_eventAccelPedalPos "Restraint control module: a024 event accel pedal pos; raw 255 = signal not available (SNA)";
CM_ SG_ 1297 RCM_a025_eventArmStatus "Restraint control module: a025 event arm status";
CM_ SG_ 1297 RCM_a025_eventFactoryMode "Restraint control module: a025 event factory mode";
CM_ SG_ 1297 RCM_a025_eventDiagEnabled "Restraint control module: a025 event diag enabled";
CM_ SG_ 1297 RCM_a025_eventDriveOrientation "Restraint control module: a025 event drive orientation";
CM_ SG_ 1297 RCM_a025_kneeABDrvrSht2Gnd "Restraint control module: a025 knee AB drvr sht2 gnd";
CM_ SG_ 1297 RCM_a025_kneeABDrvrSht2Bat "Restraint control module: a025 knee AB drvr sht2 bat";
CM_ SG_ 1297 RCM_a025_kneeABDrvrOpen "Restraint control module: a025 knee AB drvr open";
CM_ SG_ 1297 RCM_a025_kneeABDrvrShort "Restraint control module: a025 knee AB drvr short";
CM_ SG_ 1297 RCM_a025_kneeABDrvrCrossCoup "Restraint control module: a025 knee AB drvr cross coup";
CM_ SG_ 1297 RCM_a025_kneeABDrvrConfig "Restraint control module: a025 knee AB drvr config";
CM_ SG_ 1297 RCM_a025_eventIDFsignal "Restraint control module: a025 event ID fsignal";
CM_ SG_ 1297 RCM_a025_eventFrontLeftSeatbelt "Restraint control module: a025 event front left seatbelt";
CM_ SG_ 1297 RCM_a025_eventFrontRightSeatbelt "Restraint control module: a025 event front right seatbelt";
CM_ SG_ 1297 RCM_a025_eventVehicleSpeed "Restraint control module: a025 event vehicle speed";
CM_ SG_ 1297 RCM_a025_eventSteeringAngle "Restraint control module: a025 event steering angle";
CM_ SG_ 1297 RCM_a025_eventDriverBrakeApply "Restraint control module: a025 event driver brake apply; raw 3 = signal not available (SNA)";
CM_ SG_ 1297 RCM_a025_eventAccelPedalPos "Restraint control module: a025 event accel pedal pos; raw 255 = signal not available (SNA)";
CM_ SG_ 1297 RCM_a026_eventArmStatus "Restraint control module: a026 event arm status";
CM_ SG_ 1297 RCM_a026_eventFactoryMode "Restraint control module: a026 event factory mode";
CM_ SG_ 1297 RCM_a026_eventDiagEnabled "Restraint control module: a026 event diag enabled";
CM_ SG_ 1297 RCM_a026_eventDriveOrientation "Restraint control module: a026 event drive orientation";
CM_ SG_ 1297 RCM_a026_kneeABPassSht2Gnd "Restraint control module: a026 knee AB pass sht2 gnd";
CM_ SG_ 1297 RCM_a026_kneeABPassSht2Bat "Restraint control module: a026 knee AB pass sht2 bat";
CM_ SG_ 1297 RCM_a026_kneeABPassOpen "Restraint control module: a026 knee AB pass open";
CM_ SG_ 1297 RCM_a026_kneeABPassShort "Restraint control module: a026 knee AB pass short";
CM_ SG_ 1297 RCM_a026_kneeABPassCrossCoup "Restraint control module: a026 knee AB pass cross coup";
CM_ SG_ 1297 RCM_a026_kneeABPassConfig "Restraint control module: a026 knee AB pass config";
CM_ SG_ 1297 RCM_a026_eventIDFsignal "Restraint control module: a026 event ID fsignal";
CM_ SG_ 1297 RCM_a026_eventFrontLeftSeatbelt "Restraint control module: a026 event front left seatbelt";
CM_ SG_ 1297 RCM_a026_eventFrontRightSeatbelt "Restraint control module: a026 event front right seatbelt";
CM_ SG_ 1297 RCM_a026_eventVehicleSpeed "Restraint control module: a026 event vehicle speed";
CM_ SG_ 1297 RCM_a026_eventSteeringAngle "Restraint control module: a026 event steering angle";
CM_ SG_ 1297 RCM_a026_eventDriverBrakeApply "Restraint control module: a026 event driver brake apply; raw 3 = signal not available (SNA)";
CM_ SG_ 1297 RCM_a026_eventAccelPedalPos "Restraint control module: a026 event accel pedal pos; raw 255 = signal not available (SNA)";
CM_ SG_ 1297 RCM_a027_eventArmStatus "Restraint control module: a027 event arm status";
CM_ SG_ 1297 RCM_a027_eventFactoryMode "Restraint control module: a027 event factory mode";
CM_ SG_ 1297 RCM_a027_eventDiagEnabled "Restraint control module: a027 event diag enabled";
CM_ SG_ 1297 RCM_a027_eventDriveOrientation "Restraint control module: a027 event drive orientation";
CM_ SG_ 1297 RCM_a027_sideAB1stRowLSht2Gnd "Restraint control module: a027 side ab1st row l sht2 gnd";
CM_ SG_ 1297 RCM_a027_sideAB1stRowLSht2Bat "Restraint control module: a027 side ab1st row l sht2 bat";
CM_ SG_ 1297 RCM_a027_sideAB1stRowLOpen "Restraint control module: a027 side ab1st row l open";
CM_ SG_ 1297 RCM_a027_sideAB1stRowLShort "Restraint control module: a027 side ab1st row l short";
CM_ SG_ 1297 RCM_a027_sideAB1stRowLCrossCoup "Restraint control module: a027 side ab1st row l cross coup";
CM_ SG_ 1297 RCM_a027_sideAB1stRowLConfig "Restraint control module: a027 side ab1st row l config";
CM_ SG_ 1297 RCM_a027_eventIDFsignal "Restraint control module: a027 event ID fsignal";
CM_ SG_ 1297 RCM_a027_eventFrontLeftSeatbelt "Restraint control module: a027 event front left seatbelt";
CM_ SG_ 1297 RCM_a027_eventFrontRightSeatbelt "Restraint control module: a027 event front right seatbelt";
CM_ SG_ 1297 RCM_a027_eventVehicleSpeed "Restraint control module: a027 event vehicle speed";
CM_ SG_ 1297 RCM_a027_eventSteeringAngle "Restraint control module: a027 event steering angle";
CM_ SG_ 1297 RCM_a027_eventDriverBrakeApply "Restraint control module: a027 event driver brake apply; raw 3 = signal not available (SNA)";
CM_ SG_ 1297 RCM_a027_eventAccelPedalPos "Restraint control module: a027 event accel pedal pos; raw 255 = signal not available (SNA)";
CM_ SG_ 1297 RCM_a028_eventArmStatus "Restraint control module: a028 event arm status";
CM_ SG_ 1297 RCM_a028_eventFactoryMode "Restraint control module: a028 event factory mode";
CM_ SG_ 1297 RCM_a028_eventDiagEnabled "Restraint control module: a028 event diag enabled";
CM_ SG_ 1297 RCM_a028_eventDriveOrientation "Restraint control module: a028 event drive orientation";
CM_ SG_ 1297 RCM_a028_sideAB1stRowRSht2Gnd "Restraint control module: a028 side ab1st row r sht2 gnd";
CM_ SG_ 1297 RCM_a028_sideAB1stRowRSht2Bat "Restraint control module: a028 side ab1st row r sht2 bat";
CM_ SG_ 1297 RCM_a028_sideAB1stRowROpen "Restraint control module: a028 side ab1st row r open";
CM_ SG_ 1297 RCM_a028_sideAB1stRowRShort "Restraint control module: a028 side ab1st row r short";
BA_DEF_ BO_ "GenMsgCycleTime" INT 0 3600000;
BA_DEF_ BO_ "GenMsgSendType" ENUM "Cyclic","NotUsed","NotUsed","NotUsed","NotUsed","NotUsed","NotUsed","IfActive","NoMsgSendType","NotUsed";
BA_DEF_ BO_ "VFrameFormat" ENUM "StandardCAN","ExtendedCAN","reserved","J1939PG","reserved","reserved","reserved","reserved","reserved","reserved","reserved","reserved","reserved","reserved","StandardCAN_FD","ExtendedCAN_FD";
BA_DEF_ BO_ "CANFD_BRS" ENUM "0","1";
BA_DEF_ SG_ "GenSigSNA" STRING;
BA_DEF_ SG_ "SystemSignalLongSymbol" STRING;
BA_DEF_ SG_ "Confidence" ENUM "validated","plausible","layout-only","contradicted";
BA_DEF_DEF_ "GenMsgCycleTime" 0;
BA_DEF_DEF_ "GenMsgSendType" "NoMsgSendType";
BA_DEF_DEF_ "VFrameFormat" "StandardCAN";
BA_DEF_DEF_ "CANFD_BRS" "1";
BA_DEF_DEF_ "GenSigSNA" "";
BA_DEF_DEF_ "SystemSignalLongSymbol" "";
BA_DEF_DEF_ "Confidence" "layout-only";
BA_ "GenMsgCycleTime" BO_ 2033 2000;
BA_ "GenMsgSendType" BO_ 2033 0;
BA_ "GenMsgCycleTime" BO_ 2026 1000;
BA_ "GenMsgSendType" BO_ 2026 0;
BA_ "GenMsgCycleTime" BO_ 60 2000;
BA_ "GenMsgSendType" BO_ 60 0;
BA_ "GenMsgCycleTime" BO_ 1370 250;
BA_ "GenMsgSendType" BO_ 1370 0;
BA_ "GenMsgCycleTime" BO_ 840 1000;
BA_ "GenMsgSendType" BO_ 840 0;
BA_ "GenMsgCycleTime" BO_ 1005 1000;
BA_ "GenMsgSendType" BO_ 1005 0;
BA_ "GenMsgCycleTime" BO_ 1112 100;
BA_ "GenMsgSendType" BO_ 1112 0;
BA_ "GenMsgCycleTime" BO_ 767 100;
BA_ "GenMsgSendType" BO_ 767 0;
BA_ "GenMsgCycleTime" BO_ 766 1000;
BA_ "GenMsgSendType" BO_ 766 0;
BA_ "GenMsgCycleTime" BO_ 771 500;
BA_ "GenMsgSendType" BO_ 771 0;
BA_ "GenMsgCycleTime" BO_ 519 100;
BA_ "GenMsgSendType" BO_ 519 0;
BA_ "Confidence" SG_ 2033 GTW_hrlIndex 1;
BA_ "Confidence" SG_ 2033 GTW_hrlSdCardSizeGB 1;
BA_ "GenSigSNA" SG_ 2033 GTW_hrlSdCardSizeGB "0";
BA_ "Confidence" SG_ 2033 GTW_hrlState 1;
BA_ "Confidence" SG_ 2033 GTW_hrlTriggerDuration 1;
BA_ "Confidence" SG_ 2033 GTW_hrlTriggerType 1;
BA_ "Confidence" SG_ 2033 GTW_hrlTriggerId 1;
BA_ "Confidence" SG_ 2026 GTW_hrlEventStartEpoch 1;
BA_ "Confidence" SG_ 2026 GTW_hrlEventEndEpoch 1;
BA_ "Confidence" SG_ 60 GTW_infoIndex 1;
BA_ "Confidence" SG_ 60 GTW_buildType 1;
BA_ "Confidence" SG_ 60 GTW_hardwareId 1;
BA_ "Confidence" SG_ 60 GTW_platformType 1;
BA_ "Confidence" SG_ 1370 GTW_mismatchFaultIndex 1;
BA_ "Confidence" SG_ 1370 GTW_GTWmismatchFault 1;
BA_ "Confidence" SG_ 1370 GTW_BMSmismatchFault 1;
BA_ "Confidence" SG_ 1370 GTW_APSmismatchFault 1;
BA_ "Confidence" SG_ 1370 GTW_BLEEPCENTERmismatchFault 1;
BA_ "Confidence" SG_ 1370 GTW_BLEEPLEFTmismatchFault 1;
BA_ "Confidence" SG_ 1370 GTW_BLEEPREARmismatchFault 1;
BA_ "Confidence" SG_ 1370 GTW_BLEEPRIGHTmismatchFault 1;
BA_ "Confidence" SG_ 1370 GTW_CBCmismatchFault 1;
BA_ "Confidence" SG_ 1370 GTW_CMPmismatchFault 1;
BA_ "Confidence" SG_ 1370 GTW_CPmismatchFault 1;
BA_ "Confidence" SG_ 1370 GTW_DIFmismatchFault 1;
BA_ "Confidence" SG_ 1370 GTW_DIRmismatchFault 1;
BA_ "Confidence" SG_ 1370 GTW_EPAS3PmismatchFault 1;
BA_ "Confidence" SG_ 1370 GTW_EPAS3SmismatchFault 1;
BA_ "Confidence" SG_ 1370 GTW_EPBLmismatchFault 1;
BA_ "Confidence" SG_ 1370 GTW_EPBRmismatchFault 1;
BA_ "Confidence" SG_ 1370 GTW_ESPCALmismatchFault 1;
BA_ "Confidence" SG_ 1370 GTW_ESPmismatchFault 1;
BA_ "Confidence" SG_ 1370 GTW_HCM3LmismatchFault 1;
BA_ "Confidence" SG_ 1370 GTW_HCM3RmismatchFault 1;
BA_ "Confidence" SG_ 1370 GTW_HCMLmismatchFault 1;
BA_ "Confidence" SG_ 1370 GTW_HCMRmismatchFault 1;
BA_ "Confidence" SG_ 1370 GTW_HVPmismatchFault 1;
BA_ "Confidence" SG_ 1370 GTW_IBSTCALmismatchFault 1;
BA_ "Confidence" SG_ 1370 GTW_IBSTmismatchFault 1;
BA_ "Confidence" SG_ 1370 GTW_LVBMSmismatchFault 1;
BA_ "Confidence" SG_ 1370 GTW_OCS1PmismatchFault 1;
BA_ "Confidence" SG_ 1370 GTW_OPCFmismatchFault 1;
BA_ "Confidence" SG_ 1370 GTW_OPCRmismatchFault 1;
BA_ "Confidence" SG_ 1370 GTW_PARKmismatchFault 1;
BA_ "Confidence" SG_ 1370 GTW_PCSCPU2mismatchFault 1;
BA_ "Confidence" SG_ 1370 GTW_PCSmismatchFault 1;
BA_ "Confidence" SG_ 1370 GTW_PMFmismatchFault 1;
BA_ "Confidence" SG_ 1370 GTW_PMRmismatchFault 1;
BA_ "Confidence" SG_ 1370 GTW_PTCmismatchFault 1;
BA_ "Confidence" SG_ 1370 GTW_RCMCALmismatchFault 1;
BA_ "Confidence" SG_ 1370 GTW_RCMmismatchFault 1;
BA_ "Confidence" SG_ 1370 GTW_SCCMmismatchFault 1;
BA_ "Confidence" SG_ 1370 GTW_SDCRmismatchFault 1;
BA_ "Confidence" SG_ 1370 GTW_SWCmismatchFault 1;
BA_ "Confidence" SG_ 1370 GTW_THSmismatchFault 1;
BA_ "Confidence" SG_ 1370 GTW_VCFRONTmismatchFault 1;
BA_ "Confidence" SG_ 1370 GTW_VCLEFTmismatchFault 1;
BA_ "Confidence" SG_ 1370 GTW_VCRIGHTmismatchFault 1;
BA_ "Confidence" SG_ 1370 GTW_VCSECmismatchFault 1;
BA_ "Confidence" SG_ 1370 GTW_PMmismatchFault 1;
BA_ "Confidence" SG_ 840 GTW_vehicleVersionMatchStatus 1;
BA_ "Confidence" SG_ 840 GTW_hwtype 1;
BA_ "GenSigSNA" SG_ 840 GTW_hwtype "0";
BA_ "Confidence" SG_ 840 GTW_jcanProductName 1;
BA_ "GenSigSNA" SG_ 840 GTW_jcanProductName "0";
BA_ "Confidence" SG_ 840 GTW_uptimeSeconds 1;
BA_ "Confidence" SG_ 840 GTW_boardRevision 1;
BA_ "Confidence" SG_ 840 GTW_touchcoreOsType 1;
BA_ "Confidence" SG_ 840 GTW_sentryModeState 1;
BA_ "GenSigSNA" SG_ 840 GTW_sentryModeState "6";
BA_ "Confidence" SG_ 840 GTW_secureBootEnabled 1;
BA_ "Confidence" SG_ 840 GTW_socSleepType 1;
BA_ "GenSigSNA" SG_ 840 GTW_socSleepType "0";
BA_ "Confidence" SG_ 840 GTW_resetType 1;
BA_ "GenSigSNA" SG_ 840 GTW_resetType "0";
BA_ "Confidence" SG_ 1005 GTW_peripheralConfirmedUpdateNee 1;
BA_ "SystemSignalLongSymbol" SG_ 1005 GTW_peripheralConfirmedUpdateNee "GTW_peripheralConfirmedUpdateNeeded";
BA_ "Confidence" SG_ 1005 GTW_ocuFailed 1;
BA_ "Confidence" SG_ 1005 GTW_ecuUpdateStarted 1;
BA_ "Confidence" SG_ 1005 GTW_updateStarted 1;
BA_ "Confidence" SG_ 1112 GTW_nmGoingToSleep 1;
BA_ "Confidence" SG_ 1112 GTW_chBusAsleep 1;
BA_ "Confidence" SG_ 1112 GTW_ethBusAsleep 1;
BA_ "Confidence" SG_ 1112 GTW_nmKeepAwakeReason 1;
BA_ "GenSigSNA" SG_ 1112 GTW_nmKeepAwakeReason "0";
BA_ "Confidence" SG_ 1112 GTW_nmWakeUpReason 1;
BA_ "Confidence" SG_ 1112 GTW_ethKeepAwakeReason 1;
BA_ "GenSigSNA" SG_ 1112 GTW_ethKeepAwakeReason "0";
BA_ "Confidence" SG_ 1112 GTW_nmDebugWakeUp 1;
BA_ "Confidence" SG_ 1112 GTW_OTAKeepAwake 1;
BA_ "Confidence" SG_ 1112 GTW_smsPokeReceived 1;
BA_ "Confidence" SG_ 1112 GTW_bdyBusAsleep 1;
BA_ "Confidence" SG_ 1429 OCS1P_alertID 1;
BA_ "Confidence" SG_ 1429 OCS1P_alertState 1;
BA_ "Confidence" SG_ 767 OCS1P_matrixIndex 1;
BA_ "SystemSignalLongSymbol" SG_ 767 OCS1P_w148_classificationMismatc "OCS1P_w148_classificationMismatch";
BA_ "SystemSignalLongSymbol" SG_ 767 OCS1P_w156_seatbeltReminderUnava "OCS1P_w156_seatbeltReminderUnavailable";
BA_ "Confidence" SG_ 766 OCS1P_infoIndex 1;
BA_ "Confidence" SG_ 766 OCS1P_infoBuildType 1;
BA_ "Confidence" SG_ 771 OCS1P_occupantClassification 1;
BA_ "GenSigSNA" SG_ 771 OCS1P_occupantClassification "255";
BA_ "Confidence" SG_ 771 OCS1P_occupantClassificationQF 1;
BA_ "Confidence" SG_ 771 OCS1P_occupiedState 1;
BA_ "GenSigSNA" SG_ 771 OCS1P_occupiedState "3";
BA_ "Confidence" SG_ 771 OCS1P_triggerSnapshot 1;
BA_ "Confidence" SG_ 771 OCS1P_occupantClassificationRaw 1;
BA_ "GenSigSNA" SG_ 771 OCS1P_occupantClassificationRaw "7";
BA_ "Confidence" SG_ 771 OCS1P_occupantClassificationSelf 1;
BA_ "GenSigSNA" SG_ 771 OCS1P_occupantClassificationSelf "7";
BA_ "Confidence" SG_ 771 OCS1P_occupantClassificationRawC 1;
BA_ "GenSigSNA" SG_ 771 OCS1P_occupantClassificationRawC "7";
BA_ "SystemSignalLongSymbol" SG_ 771 OCS1P_occupantClassificationRawC "OCS1P_occupantClassificationRawCap";
BA_ "Confidence" SG_ 771 OCS1P_occupantClassificationCap 1;
BA_ "GenSigSNA" SG_ 771 OCS1P_occupantClassificationCap "7";
BA_ "Confidence" SG_ 771 OCS1P_classificationHeld 1;
BA_ "Confidence" SG_ 771 OCS1P_cushionStable 1;
BA_ "Confidence" SG_ 771 OCS1P_classificationExtHold 1;
BA_ "Confidence" SG_ 771 OCS1P_classificationHoldState 1;
BA_ "Confidence" SG_ 771 OCS1P_classificationVariant 1;
BA_ "Confidence" SG_ 771 OCS1P_sandwichDisabled 1;
BA_ "Confidence" SG_ 771 OCS1P_noSandwichType 1;
BA_ "Confidence" SG_ 771 OCS1P_sandwichBoundaryType 1;
BA_ "Confidence" SG_ 771 OCS1P_sbrBoundaryType 1;
BA_ "Confidence" SG_ 771 OCS1P_occupiedStateCap 1;
BA_ "GenSigSNA" SG_ 771 OCS1P_occupiedStateCap "3";
BA_ "Confidence" SG_ 771 OCS1P_seatbackStable 1;
BA_ "Confidence" SG_ 771 OCS1P_sandwichStable 1;
BA_ "Confidence" SG_ 1619 OCS1P_udsResponseData 1;
BA_ "Confidence" SG_ 519 PTC_leftFlagFault 1;
BA_ "Confidence" SG_ 519 PTC_rightFlagFault 1;
BA_ "Confidence" SG_ 519 PTC_leftPowerDerating 1;
BA_ "Confidence" SG_ 519 PTC_rightPowerDerating 1;
BA_ "Confidence" SG_ 519 PTC_ocpEvent 1;
BA_ "Confidence" SG_ 519 PTC_leftDutyFeedback 1;
BA_ "Confidence" SG_ 519 PTC_rightDutyFeedback 1;
BA_ "Confidence" SG_ 519 PTC_leftPowerHV 1;
BA_ "Confidence" SG_ 519 PTC_rightPowerHV 1;
BA_ "Confidence" SG_ 519 PTC_leftTempEstOutlet 1;
BA_ "Confidence" SG_ 519 PTC_rightTempEstOutlet 1;
BA_ "Confidence" SG_ 519 PTC_tliErrorCount 1;
BA_ "Confidence" SG_ 519 PTC_tliEvent 1;
BA_ "Confidence" SG_ 519 PTC_tliSource 1;
BA_ "Confidence" SG_ 1297 RCM_alertID 1;
BA_ "Confidence" SG_ 1297 RCM_alertState 1;
BA_ "Confidence" SG_ 1297 RCM_a000_eventArmStatus 1;
BA_ "Confidence" SG_ 1297 RCM_a000_eventFactoryMode 1;
BA_ "Confidence" SG_ 1297 RCM_a000_eventDiagEnabled 1;
BA_ "Confidence" SG_ 1297 RCM_a000_eventDriveOrientation 1;
BA_ "Confidence" SG_ 1297 RCM_a000_eventIDFsignal 1;
BA_ "Confidence" SG_ 1297 RCM_a000_eventFrontLeftSeatbelt 1;
BA_ "Confidence" SG_ 1297 RCM_a000_eventFrontRightSeatbelt 1;
BA_ "Confidence" SG_ 1297 RCM_a000_eventVehicleSpeed 1;
BA_ "Confidence" SG_ 1297 RCM_a000_eventSteeringAngle 1;
BA_ "Confidence" SG_ 1297 RCM_a000_eventDriverBrakeApply 1;
BA_ "Confidence" SG_ 1297 RCM_a000_eventAccelPedalPos 1;
BA_ "Confidence" SG_ 1297 RCM_a001_eventArmStatus 1;
BA_ "Confidence" SG_ 1297 RCM_a001_eventFactoryMode 1;
BA_ "Confidence" SG_ 1297 RCM_a001_eventDiagEnabled 1;
BA_ "Confidence" SG_ 1297 RCM_a001_eventDriveOrientation 1;
BA_ "Confidence" SG_ 1297 RCM_a001_eventIDFsignal 1;
BA_ "Confidence" SG_ 1297 RCM_a001_eventFrontLeftSeatbelt 1;
BA_ "Confidence" SG_ 1297 RCM_a001_eventFrontRightSeatbelt 1;
BA_ "Confidence" SG_ 1297 RCM_a001_eventVehicleSpeed 1;
BA_ "Confidence" SG_ 1297 RCM_a001_eventSteeringAngle 1;
BA_ "Confidence" SG_ 1297 RCM_a001_eventDriverBrakeApply 1;
BA_ "GenSigSNA" SG_ 1297 RCM_a001_eventDriverBrakeApply "3";
BA_ "Confidence" SG_ 1297 RCM_a001_eventAccelPedalPos 1;
BA_ "GenSigSNA" SG_ 1297 RCM_a001_eventAccelPedalPos "255";
BA_ "Confidence" SG_ 1297 RCM_a002_eventArmStatus 1;
BA_ "Confidence" SG_ 1297 RCM_a002_eventFactoryMode 1;
BA_ "Confidence" SG_ 1297 RCM_a002_eventDiagEnabled 1;
BA_ "Confidence" SG_ 1297 RCM_a002_eventDriveOrientation 1;
BA_ "Confidence" SG_ 1297 RCM_a002_eventIDFsignal 1;
BA_ "Confidence" SG_ 1297 RCM_a002_eventFrontLeftSeatbelt 1;
BA_ "Confidence" SG_ 1297 RCM_a002_eventFrontRightSeatbelt 1;
BA_ "Confidence" SG_ 1297 RCM_a002_eventVehicleSpeed 1;
BA_ "Confidence" SG_ 1297 RCM_a002_eventSteeringAngle 1;
BA_ "Confidence" SG_ 1297 RCM_a002_eventDriverBrakeApply 1;
BA_ "GenSigSNA" SG_ 1297 RCM_a002_eventDriverBrakeApply "3";
BA_ "Confidence" SG_ 1297 RCM_a002_eventAccelPedalPos 1;
BA_ "GenSigSNA" SG_ 1297 RCM_a002_eventAccelPedalPos "255";
BA_ "Confidence" SG_ 1297 RCM_a003_eventArmStatus 1;
BA_ "Confidence" SG_ 1297 RCM_a003_eventFactoryMode 1;
BA_ "Confidence" SG_ 1297 RCM_a003_eventDiagEnabled 1;
BA_ "Confidence" SG_ 1297 RCM_a003_eventDriveOrientation 1;
BA_ "Confidence" SG_ 1297 RCM_a003_eventIDFsignal 1;
BA_ "Confidence" SG_ 1297 RCM_a003_eventFrontLeftSeatbelt 1;
BA_ "Confidence" SG_ 1297 RCM_a003_eventFrontRightSeatbelt 1;
BA_ "Confidence" SG_ 1297 RCM_a003_eventVehicleSpeed 1;
BA_ "Confidence" SG_ 1297 RCM_a003_eventSteeringAngle 1;
BA_ "Confidence" SG_ 1297 RCM_a003_eventDriverBrakeApply 1;
BA_ "GenSigSNA" SG_ 1297 RCM_a003_eventDriverBrakeApply "3";
BA_ "Confidence" SG_ 1297 RCM_a003_eventAccelPedalPos 1;
BA_ "GenSigSNA" SG_ 1297 RCM_a003_eventAccelPedalPos "255";
BA_ "Confidence" SG_ 1297 RCM_a004_eventArmStatus 1;
BA_ "Confidence" SG_ 1297 RCM_a004_eventFactoryMode 1;
BA_ "Confidence" SG_ 1297 RCM_a004_eventDiagEnabled 1;
BA_ "Confidence" SG_ 1297 RCM_a004_eventDriveOrientation 1;
BA_ "Confidence" SG_ 1297 RCM_a004_eventIDFsignal 1;
BA_ "Confidence" SG_ 1297 RCM_a004_eventFrontLeftSeatbelt 1;
BA_ "Confidence" SG_ 1297 RCM_a004_eventFrontRightSeatbelt 1;
BA_ "Confidence" SG_ 1297 RCM_a004_eventVehicleSpeed 1;
BA_ "Confidence" SG_ 1297 RCM_a004_eventSteeringAngle 1;
BA_ "Confidence" SG_ 1297 RCM_a004_eventDriverBrakeApply 1;
BA_ "GenSigSNA" SG_ 1297 RCM_a004_eventDriverBrakeApply "3";
BA_ "Confidence" SG_ 1297 RCM_a004_eventAccelPedalPos 1;
BA_ "GenSigSNA" SG_ 1297 RCM_a004_eventAccelPedalPos "255";
BA_ "Confidence" SG_ 1297 RCM_a005_eventArmStatus 1;
BA_ "Confidence" SG_ 1297 RCM_a005_eventFactoryMode 1;
BA_ "Confidence" SG_ 1297 RCM_a005_eventDiagEnabled 1;
BA_ "Confidence" SG_ 1297 RCM_a005_eventDriveOrientation 1;
BA_ "Confidence" SG_ 1297 RCM_a005_eventIDFsignal 1;
BA_ "Confidence" SG_ 1297 RCM_a005_eventFrontLeftSeatbelt 1;
BA_ "Confidence" SG_ 1297 RCM_a005_eventFrontRightSeatbelt 1;
BA_ "Confidence" SG_ 1297 RCM_a005_eventVehicleSpeed 1;
BA_ "Confidence" SG_ 1297 RCM_a005_eventSteeringAngle 1;
BA_ "Confidence" SG_ 1297 RCM_a005_eventDriverBrakeApply 1;
BA_ "GenSigSNA" SG_ 1297 RCM_a005_eventDriverBrakeApply "3";
BA_ "Confidence" SG_ 1297 RCM_a005_eventAccelPedalPos 1;
BA_ "GenSigSNA" SG_ 1297 RCM_a005_eventAccelPedalPos "255";
BA_ "Confidence" SG_ 1297 RCM_a006_eventArmStatus 1;
BA_ "Confidence" SG_ 1297 RCM_a006_eventFactoryMode 1;
BA_ "Confidence" SG_ 1297 RCM_a006_eventDiagEnabled 1;
BA_ "Confidence" SG_ 1297 RCM_a006_eventDriveOrientation 1;
BA_ "Confidence" SG_ 1297 RCM_a006_eventIDFsignal 1;
BA_ "Confidence" SG_ 1297 RCM_a006_eventFrontLeftSeatbelt 1;
BA_ "Confidence" SG_ 1297 RCM_a006_eventFrontRightSeatbelt 1;
BA_ "Confidence" SG_ 1297 RCM_a006_eventVehicleSpeed 1;
BA_ "Confidence" SG_ 1297 RCM_a006_eventSteeringAngle 1;
BA_ "Confidence" SG_ 1297 RCM_a006_eventDriverBrakeApply 1;
BA_ "GenSigSNA" SG_ 1297 RCM_a006_eventDriverBrakeApply "3";
BA_ "Confidence" SG_ 1297 RCM_a006_eventAccelPedalPos 1;
BA_ "GenSigSNA" SG_ 1297 RCM_a006_eventAccelPedalPos "255";
BA_ "Confidence" SG_ 1297 RCM_a008_eventArmStatus 1;
BA_ "Confidence" SG_ 1297 RCM_a008_eventFactoryMode 1;
BA_ "Confidence" SG_ 1297 RCM_a008_eventDiagEnabled 1;
BA_ "Confidence" SG_ 1297 RCM_a008_eventDriveOrientation 1;
BA_ "Confidence" SG_ 1297 RCM_a008_eventIDFsignal 1;
BA_ "Confidence" SG_ 1297 RCM_a008_eventFrontLeftSeatbelt 1;
BA_ "Confidence" SG_ 1297 RCM_a008_eventFrontRightSeatbelt 1;
BA_ "Confidence" SG_ 1297 RCM_a008_eventVehicleSpeed 1;
BA_ "Confidence" SG_ 1297 RCM_a008_eventSteeringAngle 1;
BA_ "Confidence" SG_ 1297 RCM_a008_eventDriverBrakeApply 1;
BA_ "GenSigSNA" SG_ 1297 RCM_a008_eventDriverBrakeApply "3";
BA_ "Confidence" SG_ 1297 RCM_a008_eventAccelPedalPos 1;
BA_ "GenSigSNA" SG_ 1297 RCM_a008_eventAccelPedalPos "255";
BA_ "Confidence" SG_ 1297 RCM_a009_eventArmStatus 1;
BA_ "Confidence" SG_ 1297 RCM_a009_eventFactoryMode 1;
BA_ "Confidence" SG_ 1297 RCM_a009_eventDiagEnabled 1;
BA_ "Confidence" SG_ 1297 RCM_a009_eventDriveOrientation 1;
BA_ "Confidence" SG_ 1297 RCM_a009_eventIDFsignal 1;
BA_ "Confidence" SG_ 1297 RCM_a009_eventFrontLeftSeatbelt 1;
BA_ "Confidence" SG_ 1297 RCM_a009_eventFrontRightSeatbelt 1;
BA_ "Confidence" SG_ 1297 RCM_a009_eventVehicleSpeed 1;
BA_ "Confidence" SG_ 1297 RCM_a009_eventSteeringAngle 1;
BA_ "Confidence" SG_ 1297 RCM_a009_eventDriverBrakeApply 1;
BA_ "GenSigSNA" SG_ 1297 RCM_a009_eventDriverBrakeApply "3";
BA_ "Confidence" SG_ 1297 RCM_a009_eventAccelPedalPos 1;
BA_ "GenSigSNA" SG_ 1297 RCM_a009_eventAccelPedalPos "255";
BA_ "Confidence" SG_ 1297 RCM_a011_eventArmStatus 1;
BA_ "Confidence" SG_ 1297 RCM_a011_eventFactoryMode 1;
BA_ "Confidence" SG_ 1297 RCM_a011_eventDiagEnabled 1;
BA_ "Confidence" SG_ 1297 RCM_a011_eventDriveOrientation 1;
BA_ "Confidence" SG_ 1297 RCM_a011_eventIDFsignal 1;
BA_ "Confidence" SG_ 1297 RCM_a011_eventFrontLeftSeatbelt 1;
BA_ "Confidence" SG_ 1297 RCM_a011_eventFrontRightSeatbelt 1;
BA_ "Confidence" SG_ 1297 RCM_a011_eventVehicleSpeed 1;
BA_ "Confidence" SG_ 1297 RCM_a011_eventSteeringAngle 1;
BA_ "Confidence" SG_ 1297 RCM_a011_eventDriverBrakeApply 1;
BA_ "GenSigSNA" SG_ 1297 RCM_a011_eventDriverBrakeApply "3";
BA_ "Confidence" SG_ 1297 RCM_a011_eventAccelPedalPos 1;
BA_ "GenSigSNA" SG_ 1297 RCM_a011_eventAccelPedalPos "255";
BA_ "Confidence" SG_ 1297 RCM_a012_eventArmStatus 1;
BA_ "Confidence" SG_ 1297 RCM_a012_eventFactoryMode 1;
BA_ "Confidence" SG_ 1297 RCM_a012_eventDiagEnabled 1;
BA_ "Confidence" SG_ 1297 RCM_a012_eventDriveOrientation 1;
BA_ "Confidence" SG_ 1297 RCM_a012_eventIDFsignal 1;
BA_ "Confidence" SG_ 1297 RCM_a012_eventFrontLeftSeatbelt 1;
BA_ "Confidence" SG_ 1297 RCM_a012_eventFrontRightSeatbelt 1;
BA_ "Confidence" SG_ 1297 RCM_a012_eventVehicleSpeed 1;
BA_ "Confidence" SG_ 1297 RCM_a012_eventSteeringAngle 1;
BA_ "Confidence" SG_ 1297 RCM_a012_eventDriverBrakeApply 1;
BA_ "GenSigSNA" SG_ 1297 RCM_a012_eventDriverBrakeApply "3";
BA_ "Confidence" SG_ 1297 RCM_a012_eventAccelPedalPos 1;
BA_ "GenSigSNA" SG_ 1297 RCM_a012_eventAccelPedalPos "255";
BA_ "Confidence" SG_ 1297 RCM_a013_eventArmStatus 1;
BA_ "Confidence" SG_ 1297 RCM_a013_eventFactoryMode 1;
BA_ "Confidence" SG_ 1297 RCM_a013_eventDiagEnabled 1;
BA_ "Confidence" SG_ 1297 RCM_a013_eventDriveOrientation 1;
BA_ "Confidence" SG_ 1297 RCM_a013_eventIDFsignal 1;
BA_ "Confidence" SG_ 1297 RCM_a013_eventFrontLeftSeatbelt 1;
BA_ "Confidence" SG_ 1297 RCM_a013_eventFrontRightSeatbelt 1;
BA_ "Confidence" SG_ 1297 RCM_a013_eventVehicleSpeed 1;
BA_ "Confidence" SG_ 1297 RCM_a013_eventSteeringAngle 1;
BA_ "Confidence" SG_ 1297 RCM_a013_eventDriverBrakeApply 1;
BA_ "GenSigSNA" SG_ 1297 RCM_a013_eventDriverBrakeApply "3";
BA_ "Confidence" SG_ 1297 RCM_a013_eventAccelPedalPos 1;
BA_ "GenSigSNA" SG_ 1297 RCM_a013_eventAccelPedalPos "255";
BA_ "Confidence" SG_ 1297 RCM_a014_eventArmStatus 1;
BA_ "Confidence" SG_ 1297 RCM_a014_eventFactoryMode 1;
BA_ "Confidence" SG_ 1297 RCM_a014_eventDiagEnabled 1;
BA_ "Confidence" SG_ 1297 RCM_a014_eventDriveOrientation 1;
BA_ "Confidence" SG_ 1297 RCM_a014_eventIDFsignal 1;
BA_ "Confidence" SG_ 1297 RCM_a014_eventFrontLeftSeatbelt 1;
BA_ "Confidence" SG_ 1297 RCM_a014_eventFrontRightSeatbelt 1;
BA_ "Confidence" SG_ 1297 RCM_a014_eventVehicleSpeed 1;
BA_ "Confidence" SG_ 1297 RCM_a014_eventSteeringAngle 1;
BA_ "Confidence" SG_ 1297 RCM_a014_eventDriverBrakeApply 1;
BA_ "GenSigSNA" SG_ 1297 RCM_a014_eventDriverBrakeApply "3";
BA_ "Confidence" SG_ 1297 RCM_a014_eventAccelPedalPos 1;
BA_ "GenSigSNA" SG_ 1297 RCM_a014_eventAccelPedalPos "255";
BA_ "Confidence" SG_ 1297 RCM_a015_eventArmStatus 1;
BA_ "Confidence" SG_ 1297 RCM_a015_eventFactoryMode 1;
BA_ "Confidence" SG_ 1297 RCM_a015_eventDiagEnabled 1;
BA_ "Confidence" SG_ 1297 RCM_a015_eventDriveOrientation 1;
BA_ "Confidence" SG_ 1297 RCM_a015_eventIDFsignal 1;
BA_ "Confidence" SG_ 1297 RCM_a015_eventFrontLeftSeatbelt 1;
BA_ "Confidence" SG_ 1297 RCM_a015_eventFrontRightSeatbelt 1;
BA_ "Confidence" SG_ 1297 RCM_a015_eventVehicleSpeed 1;
BA_ "Confidence" SG_ 1297 RCM_a015_eventSteeringAngle 1;
BA_ "Confidence" SG_ 1297 RCM_a015_eventDriverBrakeApply 1;
BA_ "GenSigSNA" SG_ 1297 RCM_a015_eventDriverBrakeApply "3";
BA_ "Confidence" SG_ 1297 RCM_a015_eventAccelPedalPos 1;
BA_ "GenSigSNA" SG_ 1297 RCM_a015_eventAccelPedalPos "255";
BA_ "Confidence" SG_ 1297 RCM_a016_eventArmStatus 1;
BA_ "Confidence" SG_ 1297 RCM_a016_eventFactoryMode 1;
BA_ "Confidence" SG_ 1297 RCM_a016_eventDiagEnabled 1;
BA_ "Confidence" SG_ 1297 RCM_a016_eventDriveOrientation 1;
BA_ "Confidence" SG_ 1297 RCM_a016_eventIDFsignal 1;
BA_ "Confidence" SG_ 1297 RCM_a016_eventFrontLeftSeatbelt 1;
BA_ "Confidence" SG_ 1297 RCM_a016_eventFrontRightSeatbelt 1;
BA_ "Confidence" SG_ 1297 RCM_a016_eventVehicleSpeed 1;
BA_ "Confidence" SG_ 1297 RCM_a016_eventSteeringAngle 1;
BA_ "Confidence" SG_ 1297 RCM_a016_eventDriverBrakeApply 1;
BA_ "GenSigSNA" SG_ 1297 RCM_a016_eventDriverBrakeApply "3";
BA_ "Confidence" SG_ 1297 RCM_a016_eventAccelPedalPos 1;
BA_ "GenSigSNA" SG_ 1297 RCM_a016_eventAccelPedalPos "255";
BA_ "Confidence" SG_ 1297 RCM_a017_eventArmStatus 1;
BA_ "Confidence" SG_ 1297 RCM_a017_eventFactoryMode 1;
BA_ "Confidence" SG_ 1297 RCM_a017_eventDiagEnabled 1;
BA_ "Confidence" SG_ 1297 RCM_a017_eventDriveOrientation 1;
BA_ "Confidence" SG_ 1297 RCM_a017_eventIDFsignal 1;
BA_ "Confidence" SG_ 1297 RCM_a017_eventFrontLeftSeatbelt 1;
BA_ "Confidence" SG_ 1297 RCM_a017_eventFrontRightSeatbelt 1;
BA_ "Confidence" SG_ 1297 RCM_a017_eventVehicleSpeed 1;
BA_ "Confidence" SG_ 1297 RCM_a017_eventSteeringAngle 1;
BA_ "Confidence" SG_ 1297 RCM_a017_eventDriverBrakeApply 1;
BA_ "GenSigSNA" SG_ 1297 RCM_a017_eventDriverBrakeApply "3";
BA_ "Confidence" SG_ 1297 RCM_a017_eventAccelPedalPos 1;
BA_ "GenSigSNA" SG_ 1297 RCM_a017_eventAccelPedalPos "255";
BA_ "Confidence" SG_ 1297 RCM_a018_eventArmStatus 1;
BA_ "Confidence" SG_ 1297 RCM_a018_eventFactoryMode 1;
BA_ "Confidence" SG_ 1297 RCM_a018_eventDiagEnabled 1;
BA_ "Confidence" SG_ 1297 RCM_a018_eventDriveOrientation 1;
BA_ "Confidence" SG_ 1297 RCM_a018_eventIDFsignal 1;
BA_ "Confidence" SG_ 1297 RCM_a018_eventFrontLeftSeatbelt 1;
BA_ "Confidence" SG_ 1297 RCM_a018_eventFrontRightSeatbelt 1;
BA_ "Confidence" SG_ 1297 RCM_a018_eventVehicleSpeed 1;
BA_ "Confidence" SG_ 1297 RCM_a018_eventSteeringAngle 1;
BA_ "Confidence" SG_ 1297 RCM_a018_eventDriverBrakeApply 1;
BA_ "GenSigSNA" SG_ 1297 RCM_a018_eventDriverBrakeApply "3";
BA_ "Confidence" SG_ 1297 RCM_a018_eventAccelPedalPos 1;
BA_ "GenSigSNA" SG_ 1297 RCM_a018_eventAccelPedalPos "255";
BA_ "Confidence" SG_ 1297 RCM_a019_eventArmStatus 1;
BA_ "Confidence" SG_ 1297 RCM_a019_eventFactoryMode 1;
BA_ "Confidence" SG_ 1297 RCM_a019_eventDiagEnabled 1;
BA_ "Confidence" SG_ 1297 RCM_a019_eventDriveOrientation 1;
BA_ "Confidence" SG_ 1297 RCM_a019_eventIDFsignal 1;
BA_ "Confidence" SG_ 1297 RCM_a019_eventFrontLeftSeatbelt 1;
BA_ "Confidence" SG_ 1297 RCM_a019_eventFrontRightSeatbelt 1;
BA_ "Confidence" SG_ 1297 RCM_a019_eventVehicleSpeed 1;
BA_ "Confidence" SG_ 1297 RCM_a019_eventSteeringAngle 1;
BA_ "Confidence" SG_ 1297 RCM_a019_eventDriverBrakeApply 1;
BA_ "GenSigSNA" SG_ 1297 RCM_a019_eventDriverBrakeApply "3";
BA_ "Confidence" SG_ 1297 RCM_a019_eventAccelPedalPos 1;
BA_ "GenSigSNA" SG_ 1297 RCM_a019_eventAccelPedalPos "255";
BA_ "Confidence" SG_ 1297 RCM_a020_eventArmStatus 1;
BA_ "Confidence" SG_ 1297 RCM_a020_eventFactoryMode 1;
BA_ "Confidence" SG_ 1297 RCM_a020_eventDiagEnabled 1;
BA_ "Confidence" SG_ 1297 RCM_a020_eventDriveOrientation 1;
BA_ "Confidence" SG_ 1297 RCM_a020_eventIDFsignal 1;
BA_ "Confidence" SG_ 1297 RCM_a020_eventFrontLeftSeatbelt 1;
BA_ "Confidence" SG_ 1297 RCM_a020_eventFrontRightSeatbelt 1;
BA_ "Confidence" SG_ 1297 RCM_a020_eventVehicleSpeed 1;
BA_ "Confidence" SG_ 1297 RCM_a020_eventSteeringAngle 1;
BA_ "Confidence" SG_ 1297 RCM_a020_eventDriverBrakeApply 1;
BA_ "GenSigSNA" SG_ 1297 RCM_a020_eventDriverBrakeApply "3";
BA_ "Confidence" SG_ 1297 RCM_a020_eventAccelPedalPos 1;
BA_ "GenSigSNA" SG_ 1297 RCM_a020_eventAccelPedalPos "255";
BA_ "Confidence" SG_ 1297 RCM_a021_eventArmStatus 1;
BA_ "Confidence" SG_ 1297 RCM_a021_eventFactoryMode 1;
BA_ "Confidence" SG_ 1297 RCM_a021_eventDiagEnabled 1;
BA_ "Confidence" SG_ 1297 RCM_a021_eventDriveOrientation 1;
BA_ "Confidence" SG_ 1297 RCM_a021_eventIDFsignal 1;
BA_ "Confidence" SG_ 1297 RCM_a021_eventFrontLeftSeatbelt 1;
BA_ "Confidence" SG_ 1297 RCM_a021_eventFrontRightSeatbelt 1;
BA_ "Confidence" SG_ 1297 RCM_a021_eventVehicleSpeed 1;
BA_ "Confidence" SG_ 1297 RCM_a021_eventSteeringAngle 1;
BA_ "Confidence" SG_ 1297 RCM_a021_eventDriverBrakeApply 1;
BA_ "GenSigSNA" SG_ 1297 RCM_a021_eventDriverBrakeApply "3";
BA_ "Confidence" SG_ 1297 RCM_a021_eventAccelPedalPos 1;
BA_ "GenSigSNA" SG_ 1297 RCM_a021_eventAccelPedalPos "255";
BA_ "Confidence" SG_ 1297 RCM_a022_eventArmStatus 1;
BA_ "Confidence" SG_ 1297 RCM_a022_eventFactoryMode 1;
BA_ "Confidence" SG_ 1297 RCM_a022_eventDiagEnabled 1;
BA_ "Confidence" SG_ 1297 RCM_a022_eventDriveOrientation 1;
BA_ "Confidence" SG_ 1297 RCM_a022_eventIDFsignal 1;
BA_ "Confidence" SG_ 1297 RCM_a022_eventFrontLeftSeatbelt 1;
BA_ "Confidence" SG_ 1297 RCM_a022_eventFrontRightSeatbelt 1;
BA_ "Confidence" SG_ 1297 RCM_a022_eventVehicleSpeed 1;
BA_ "Confidence" SG_ 1297 RCM_a022_eventSteeringAngle 1;
BA_ "Confidence" SG_ 1297 RCM_a022_eventDriverBrakeApply 1;
BA_ "GenSigSNA" SG_ 1297 RCM_a022_eventDriverBrakeApply "3";
BA_ "Confidence" SG_ 1297 RCM_a022_eventAccelPedalPos 1;
BA_ "GenSigSNA" SG_ 1297 RCM_a022_eventAccelPedalPos "255";
BA_ "Confidence" SG_ 1297 RCM_a023_eventArmStatus 1;
BA_ "Confidence" SG_ 1297 RCM_a023_eventFactoryMode 1;
BA_ "Confidence" SG_ 1297 RCM_a023_eventDiagEnabled 1;
BA_ "Confidence" SG_ 1297 RCM_a023_eventDriveOrientation 1;
BA_ "Confidence" SG_ 1297 RCM_a023_eventIDFsignal 1;
BA_ "Confidence" SG_ 1297 RCM_a023_eventFrontLeftSeatbelt 1;
BA_ "Confidence" SG_ 1297 RCM_a023_eventFrontRightSeatbelt 1;
BA_ "Confidence" SG_ 1297 RCM_a023_eventVehicleSpeed 1;
BA_ "Confidence" SG_ 1297 RCM_a023_eventSteeringAngle 1;
BA_ "Confidence" SG_ 1297 RCM_a023_eventDriverBrakeApply 1;
BA_ "GenSigSNA" SG_ 1297 RCM_a023_eventDriverBrakeApply "3";
BA_ "Confidence" SG_ 1297 RCM_a023_eventAccelPedalPos 1;
BA_ "GenSigSNA" SG_ 1297 RCM_a023_eventAccelPedalPos "255";
BA_ "Confidence" SG_ 1297 RCM_a024_eventArmStatus 1;
BA_ "Confidence" SG_ 1297 RCM_a024_eventFactoryMode 1;
BA_ "Confidence" SG_ 1297 RCM_a024_eventDiagEnabled 1;
BA_ "Confidence" SG_ 1297 RCM_a024_eventDriveOrientation 1;
BA_ "Confidence" SG_ 1297 RCM_a024_eventIDFsignal 1;
BA_ "Confidence" SG_ 1297 RCM_a024_eventFrontLeftSeatbelt 1;
BA_ "Confidence" SG_ 1297 RCM_a024_eventFrontRightSeatbelt 1;
BA_ "Confidence" SG_ 1297 RCM_a024_eventVehicleSpeed 1;
BA_ "Confidence" SG_ 1297 RCM_a024_eventSteeringAngle 1;
BA_ "Confidence" SG_ 1297 RCM_a024_eventDriverBrakeApply 1;
BA_ "GenSigSNA" SG_ 1297 RCM_a024_eventDriverBrakeApply "3";
BA_ "Confidence" SG_ 1297 RCM_a024_eventAccelPedalPos 1;
BA_ "GenSigSNA" SG_ 1297 RCM_a024_eventAccelPedalPos "255";
BA_ "Confidence" SG_ 1297 RCM_a025_eventArmStatus 1;
BA_ "Confidence" SG_ 1297 RCM_a025_eventFactoryMode 1;
BA_ "Confidence" SG_ 1297 RCM_a025_eventDiagEnabled 1;
BA_ "Confidence" SG_ 1297 RCM_a025_eventDriveOrientation 1;
BA_ "Confidence" SG_ 1297 RCM_a025_eventIDFsignal 1;
BA_ "Confidence" SG_ 1297 RCM_a025_eventFrontLeftSeatbelt 1;
BA_ "Confidence" SG_ 1297 RCM_a025_eventFrontRightSeatbelt 1;
BA_ "Confidence" SG_ 1297 RCM_a025_eventVehicleSpeed 1;
BA_ "Confidence" SG_ 1297 RCM_a025_eventSteeringAngle 1;
BA_ "Confidence" SG_ 1297 RCM_a025_eventDriverBrakeApply 1;
BA_ "GenSigSNA" SG_ 1297 RCM_a025_eventDriverBrakeApply "3";
BA_ "Confidence" SG_ 1297 RCM_a025_eventAccelPedalPos 1;
BA_ "GenSigSNA" SG_ 1297 RCM_a025_eventAccelPedalPos "255";
BA_ "Confidence" SG_ 1297 RCM_a026_eventArmStatus 1;
BA_ "Confidence" SG_ 1297 RCM_a026_eventFactoryMode 1;
BA_ "Confidence" SG_ 1297 RCM_a026_eventDiagEnabled 1;
BA_ "Confidence" SG_ 1297 RCM_a026_eventDriveOrientation 1;
BA_ "Confidence" SG_ 1297 RCM_a026_eventIDFsignal 1;
BA_ "Confidence" SG_ 1297 RCM_a026_eventFrontLeftSeatbelt 1;
BA_ "Confidence" SG_ 1297 RCM_a026_eventFrontRightSeatbelt 1;
BA_ "Confidence" SG_ 1297 RCM_a026_eventVehicleSpeed 1;
BA_ "Confidence" SG_ 1297 RCM_a026_eventSteeringAngle 1;
BA_ "Confidence" SG_ 1297 RCM_a026_eventDriverBrakeApply 1;
BA_ "GenSigSNA" SG_ 1297 RCM_a026_eventDriverBrakeApply "3";
BA_ "Confidence" SG_ 1297 RCM_a026_eventAccelPedalPos 1;
BA_ "GenSigSNA" SG_ 1297 RCM_a026_eventAccelPedalPos "255";
BA_ "Confidence" SG_ 1297 RCM_a027_eventArmStatus 1;
BA_ "Confidence" SG_ 1297 RCM_a027_eventFactoryMode 1;
BA_ "Confidence" SG_ 1297 RCM_a027_eventDiagEnabled 1;
BA_ "Confidence" SG_ 1297 RCM_a027_eventDriveOrientation 1;
BA_ "Confidence" SG_ 1297 RCM_a027_eventIDFsignal 1;
BA_ "Confidence" SG_ 1297 RCM_a027_eventFrontLeftSeatbelt 1;
BA_ "Confidence" SG_ 1297 RCM_a027_eventFrontRightSeatbelt 1;
BA_ "Confidence" SG_ 1297 RCM_a027_eventVehicleSpeed 1;
BA_ "Confidence" SG_ 1297 RCM_a027_eventSteeringAngle 1;
BA_ "Confidence" SG_ 1297 RCM_a027_eventDriverBrakeApply 1;
BA_ "GenSigSNA" SG_ 1297 RCM_a027_eventDriverBrakeApply "3";
BA_ "Confidence" SG_ 1297 RCM_a027_eventAccelPedalPos 1;
BA_ "GenSigSNA" SG_ 1297 RCM_a027_eventAccelPedalPos "255";
BA_ "Confidence" SG_ 1297 RCM_a028_eventArmStatus 1;
BA_ "Confidence" SG_ 1297 RCM_a028_eventFactoryMode 1;
BA_ "Confidence" SG_ 1297 RCM_a028_eventDiagEnabled 1;
BA_ "Confidence" SG_ 1297 RCM_a028_eventDriveOrientation 1;
VAL_ 2033 GTW_hrlIndex 2 "Mux2" 1 "Mux1" ;
VAL_ 2033 GTW_hrlSdCardSizeGB 0 "SNA" ;
VAL_ 2033 GTW_hrlState 1 "ENABLED" 0 "DISABLED" ;
VAL_ 2033 GTW_hrlTriggerType 15 "HRL_TRIGGER_NONE" 5 "HRL_TRIGGER_EVENT_EXTERNAL" 4 "HRL_TRIGGER_PSEUDONYMOUS" 3 "HRL_TRIGGER_CONTINUOUS" 2 "HRL_TRIGGER_GAME_MODE" 1 "HRL_TRIGGER_EVENT" 0 "HRL_TRIGGER_UDPAPI" ;
VAL_ 60 GTW_infoIndex 255 "END" 31 "SUBCOMPONENT_GITHASH" 30 "PACKAGE_SN_8_14" 29 "PACKAGE_SN_1_7" 27 "PACKAGE_PN_15_20" 26 "PACKAGE_PN_8_14" 25 "PACKAGE_PN_1_7" 23 "SUBCOMPONENT2" 22 "VARIANTCRC" 20 "UDS_PROTOCOL_BOOTCRC" 19 "VERSION_DEPRECATED" 18 "BOOTLOADER_GITHASH" 17 "APP_GITHASH" 16 "SUBCOMPONENT" 15 "BOOTLOADER_CRC" 14 "BOOTLOADER_SVN" 13 "APP_CRC" 11 "PCBAID_ASSYID_USAGEID" 10 "BUILD_HWID_COMPONENTID" 9 "DEPRECATED_9" 8 "DEPRECATED_8" 7 "DEPRECATED_7" 6 "DEPRECATED_6" 5 "DEPRECATED_5" 4 "DEPRECATED_4" 3 "DEPRECATED_3" 2 "DEPRECATED_2" 1 "DEPRECATED_1" 0 "DEPRECATED_0" ;
VAL_ 60 GTW_buildType 4 "INFO_MFG_BUILD" 3 "INFO_TRACEABLE_CI_BUILD" 2 "INFO_LOCAL_BUILD" 1 "INFO_PLATFORM_BUILD" 0 "INFO_UNKNOWN_BUILD" ;
VAL_ 60 GTW_platformType 255 "GTW_PLATFORM_END" 3 "GTW_PLATFORM_MODEL3" 0 "GTW_PLATFORM_UNKNOWN" ;
VAL_ 1370 GTW_mismatchFaultIndex 5 "Mux5" 4 "Mux4" 3 "Mux3" 2 "Mux2" 1 "Mux1" ;
VAL_ 840 GTW_vehicleVersionMatchStatus 2 "MATCHED" 1 "MISMATCHED" 0 "NOT_CALCULATED_YET" ;
VAL_ 840 GTW_hwtype 3 "TRAVEO2" 2 "SPC58" 1 "MPC57" 0 "SNA" ;
VAL_ 840 GTW_jcanProductName 11 "SEMITRUCKV2" 10 "GOLDENSNITCH" 8 "BAYBERRY" 7 "CYBERTRUCK" 6 "POPPYSEED" 5 "SEMITRUCK" 4 "TAMARIND" 3 "LYCHEE" 2 "MODELY" 1 "MODEL3" 0 "SNA" ;
VAL_ 840 GTW_touchcoreOsType 1 "GTW_OS_RT" 0 "GTW_OS_FREERTOS" ;
VAL_ 840 GTW_sentryModeState 6 "SNA" 5 "QUIET" 4 "PANIC" 3 "AWARE" 2 "ARMED" 1 "IDLE" 0 "OFF" ;
VAL_ 840 GTW_secureBootEnabled 1 "TRUE" 0 "FALSE" ;
VAL_ 840 GTW_socSleepType 2 "SHALLOW" 1 "S3" 0 "SNA" ;
VAL_ 840 GTW_resetType 8 "OTHER" 7 "TOUCHCORE_WATCHDOG" 6 "CANCORE_WATCHDOG" 5 "MAINCORE_WATCHDOG" 4 "WAKE" 3 "BUTTON" 2 "SOFTWARE" 1 "POR" 0 "SNA" ;
VAL_ 1005 GTW_peripheralConfirmedUpdateNee 3 "UPDATE_CONDITIONS_NOT_CORRECT" 2 "UPDATE_NOT_NEEDED" 1 "UPDATE_NEEDED" 0 "UNKNOWN" ;
VAL_ 1112 GTW_nmKeepAwakeReason 15 "GTW_KEEPAWAKE_REASON_TBD" 7 "GTW_KEEPAWAKE_REASON_TCU_TC10_VERSION_UNSUPPORTED" 6 "GTW_KEEPAWAKE_REASON_TCU_TC10_VERSION_CHECK" 5 "GTW_KEEPAWAKE_REASON_EGGLEFT_LINK_DOWN" 4 "GTW_KEEPAWAKE_REASON_URGENT_TRANSMIT_ALERT" 3 "GTW_KEEPAWAKE_REASON_FCSM_ACTIVE" 2 "GTW_KEEPAWAKE_REASON_GSM_RI" 1 "GTW_KEEPAWAKE_REASON_UI_SCHEDULED" 0 "GTW_KEEPAWAKE_REASON_NONE_SNA" ;
VAL_ 1112 GTW_nmWakeUpReason 17 "GTW_WAKEUP_REASON_TCU_TC10_VERSION_CHECK" 16 "GTW_WAKEUP_REASON_EGGLEFT_LINK_DOWN" 15 "GTW_WAKEUP_REASON_RCMPRIVATE_CAN" 14 "GTW_WAKEUP_REASON_VCLEFT" 13 "GTW_WAKEUP_REASON_LOOP" 12 "GTW_WAKEUP_REASON_DISPLAY_TAP" 11 "GTW_WAKEUP_REASON_URGENT_TRANSMIT_ALERT" 10 "GTW_WAKEUP_REASON_BDY_CAN" 9 "GTW_WAKEUP_REASON_PT_CAN" 8 "GTW_WAKEUP_REASON_UI_SCHEDULED" 7 "GTW_WAKEUP_REASON_RTC_ALARM" 6 "GTW_WAKEUP_REASON_VCFRONT" 5 "GTW_WAKEUP_REASON_VEH_CAN" 4 "GTW_WAKEUP_REASON_ETH_CAN" 3 "GTW_WAKEUP_REASON_CH_CAN" 2 "GTW_WAKEUP_REASON_GSM_RI" 1 "GTW_WAKEUP_REASON_RESET" 0 "GTW_WAKEUP_REASON_NONE" ;
VAL_ 1112 GTW_ethKeepAwakeReason 3 "TCU_TC10_VERSION_UNSUPPORTED" 2 "TCU_TC10_VERSION_CHECK" 1 "URGENT_TRANSMIT_ALERT" 0 "NONE_SNA" ;
VAL_ 1112 GTW_nmDebugWakeUp 2147483648 "WKPU_31" 1073741824 "WKPU_30" 536870912 "WKPU_29" 268435456 "WKPU_28" 134217728 "WKPU_27" 67108864 "WKPU_26" 33554432 "WKPU_25" 16777216 "WKPU_24" 8388608 "WKPU_23" 4194304 "WKPU_22" 2097152 "WKPU_21" 1048576 "WKPU_20" 524288 "WKPU_19" 262144 "WKPU_18" 131072 "WKPU_17" 65536 "WKPU_16" 32768 "WKPU_15" 16384 "WKPU_14" 8192 "WKPU_13" 4096 "WKPU_12" 2048 "WKPU_11" 1024 "WKPU_10" 512 "WKPU_9" 256 "WKPU_8" 128 "WKPU_7" 64 "WKPU_6" 32 "WKPU_5" 16 "WKPU_4" 8 "WKPU_3" 4 "WKPU_2" 2 "WKPU_1" 1 "WKPU_0" 0 "WKPU_NONE" ;
VAL_ 1429 OCS1P_alertID 156 "a156_seatbeltReminderUnavailable" 155 "a155_rbExit2Exited2" 154 "a154_rbExit2Exited1" 153 "a153_rbExit1Exited" 152 "a152_rbExit1Triggered" 151 "a151_rbEntryExited" 150 "a150_rbEntryTriggered" 148 "a148_classificationMismatch" 145 "a145_rebaselineTriggered" 144 "a144_mismatchCarRegion" 143 "a143_mismatchPassAirbag" 142 "a142_tempHumidityInvalid" 141 "a141_humidityInvalidCalib" 140 "a140_tempInvalidCalib" 139 "a139_seatbackSelfDutyHigh" 138 "a138_seatbackSelfDutyLow" 137 "a137_cushionSelfDutyHigh" 136 "a136_cushionSelfDutyLow" 135 "a135_tempNoCalib" 134 "a134_uninitializedCalib" 133 "a133_sandwichBadCalib" 132 "a132_seatbackSelfNoCalib" 131 "a131_cushionSelfNoCalib" 130 "a130_sandwichNoCalib" 129 "a129_seatbackSelfShort" 128 "a128_seatbackSelfLow" 127 "a127_seatbackSelfOpen" 126 "a126_cushionSelfShort" 125 "a125_cushionSelfLow" 124 "a124_cushionSelfOpen" 123 "a123_sandwichShort" 122 "a122_sandwichLow" 121 "a121_sandwichOpen" 15 "a015_NVMMAlert" 0 "ALERT_DO_NOT_USE_ZERO" ;
VAL_ 1429 OCS1P_alertState 1 "SET" 0 "CLEARED" ;
VAL_ 767 OCS1P_matrixIndex 2 "AlertMatrix2" 0 "AlertMatrix0" ;
VAL_ 766 OCS1P_infoIndex 20 "Mux20" 19 "Mux19" 18 "Mux18" 17 "Mux17" 14 "Mux14" 13 "Mux13" 11 "Mux11" 10 "Mux10" ;
VAL_ 766 OCS1P_infoBuildType 4 "INFO_MFG_BUILD" 3 "INFO_TRACEABLE_CI_BUILD" 2 "INFO_LOCAL_BUILD" 1 "INFO_PLATFORM_BUILD" 0 "INFO_UNKNOWN_BUILD" ;
VAL_ 771 OCS1P_occupantClassification 255 "OCCUPANT_CLASSIFICATION_SNA" 4 "OCCUPANT_CLASSIFICATION_INIT" 3 "OCCUPANT_CLASSIFICATION_OCCUPIED_ALLOW_LARGE" 2 "OCCUPANT_CLASSIFICATION_OCCUPIED_ALLOW_SMALL" 1 "OCCUPANT_CLASSIFICATION_OCCUPIED_INHIBIT" 0 "OCCUPANT_CLASSIFICATION_EMPTY" ;
VAL_ 771 OCS1P_occupantClassificationQF 1 "OCCUPANT_CLASSIFICATION_NOT_FAULTED" 0 "OCCUPANT_CLASSIFICATION_FAULTED" ;
VAL_ 771 OCS1P_occupiedState 3 "OCCUPIED_STATE_SNA" 1 "OCCUPIED_STATE_OCCUPIED" 0 "OCCUPIED_STATE_UNOCCUPIED" ;
VAL_ 771 OCS1P_triggerSnapshot 19 "REASON_LCB_TOO_HIGH" 18 "REASON_SWITCHED_TO_HCB" 17 "REASON_LARGE_REBASELINE" 16 "REASON_BORDERLINE_CLASSIFICATION" 15 "REASON_MISSED_EXIT_EVENT" 14 "REASON_MISSED_ENTRY_EVENT" 13 "REASON_EMPTY_CONFIDENT_EXITED" 12 "REASON_EMPTY_CONFIDENT_REBASELINED" 11 "REASON_EXIT_REBASELINED" 10 "REASON_EXIT_FAILED" 9 "REASON_EXIT_TRIGGERED" 8 "REASON_ENTRY_REBASELINED" 7 "REASON_ENTRY_FAILED" 6 "REASON_ENTRY_TRIGGERED" 5 "REASON_SENSOR_LOW_SHORT" 4 "REASON_SENSOR_OPEN" 3 "REASON_SANDWICH_LOW" 2 "REASON_REBASELINED" 1 "REASON_MISMATCH" 0 "REASON_NONE" ;
VAL_ 771 OCS1P_occupantClassificationRaw 7 "OCCUPANT_CLASSIFICATION_SNA" 4 "OCCUPANT_CLASSIFICATION_INIT" 3 "OCCUPANT_CLASSIFICATION_OCCUPIED_ALLOW_LARGE" 2 "OCCUPANT_CLASSIFICATION_OCCUPIED_ALLOW_SMALL" 1 "OCCUPANT_CLASSIFICATION_OCCUPIED_INHIBIT" 0 "OCCUPANT_CLASSIFICATION_EMPTY" ;
VAL_ 771 OCS1P_occupantClassificationSelf 7 "OCCUPANT_CLASSIFICATION_SNA" 4 "OCCUPANT_CLASSIFICATION_INIT" 3 "OCCUPANT_CLASSIFICATION_OCCUPIED_ALLOW_LARGE" 2 "OCCUPANT_CLASSIFICATION_OCCUPIED_ALLOW_SMALL" 1 "OCCUPANT_CLASSIFICATION_OCCUPIED_INHIBIT" 0 "OCCUPANT_CLASSIFICATION_EMPTY" ;
VAL_ 771 OCS1P_occupantClassificationRawC 7 "OCCUPANT_CLASSIFICATION_SNA" 4 "OCCUPANT_CLASSIFICATION_INIT" 3 "OCCUPANT_CLASSIFICATION_OCCUPIED_ALLOW_LARGE" 2 "OCCUPANT_CLASSIFICATION_OCCUPIED_ALLOW_SMALL" 1 "OCCUPANT_CLASSIFICATION_OCCUPIED_INHIBIT" 0 "OCCUPANT_CLASSIFICATION_EMPTY" ;
VAL_ 771 OCS1P_occupantClassificationCap 7 "OCCUPANT_CLASSIFICATION_SNA" 4 "OCCUPANT_CLASSIFICATION_INIT" 3 "OCCUPANT_CLASSIFICATION_OCCUPIED_ALLOW_LARGE" 2 "OCCUPANT_CLASSIFICATION_OCCUPIED_ALLOW_SMALL" 1 "OCCUPANT_CLASSIFICATION_OCCUPIED_INHIBIT" 0 "OCCUPANT_CLASSIFICATION_EMPTY" ;
VAL_ 771 OCS1P_classificationHoldState 3 "OCCUPANCY_HOLD_FAULT" 2 "OCCUPANCY_HOLD_EXTERNAL" 1 "OCCUPANCY_HOLD_BASIC" 0 "OCCUPANCY_HOLD_OFF" ;
VAL_ 771 OCS1P_classificationVariant 7 "CLASSIFICATION_VARIANT_UNKNOWN" 3 "CLASSIFICATION_VARIANT_SELF_SBR_RB" 2 "CLASSIFICATION_VARIANT_SELF_SBR" 1 "CLASSIFICATION_VARIANT_SELF_ONLY" 0 "CLASSIFICATION_VARIANT_ALL_SENSORS" ;
VAL_ 771 OCS1P_noSandwichType 3 "NO_SANDWICH_UNKNOWN" 2 "NO_SANDWICH_NA" 1 "NO_SANDWICH_EU" 0 "SANDWICH_INSTALLED" ;
VAL_ 771 OCS1P_sandwichBoundaryType 1 "SANDWICH_LRD" 0 "SANDWICH_DEFAULT" ;
VAL_ 771 OCS1P_sbrBoundaryType 1 "SBR_1669747_1763884" 0 "SBR_DEFAULT" ;
VAL_ 771 OCS1P_occupiedStateCap 3 "OCCUPIED_STATE_SNA" 1 "OCCUPIED_STATE_OCCUPIED" 0 "OCCUPIED_STATE_UNOCCUPIED" ;
VAL_ 519 PTC_leftPowerDerating 3 "OVERTEMPERATURE_CORE" 2 "OVERTEMPERATURE_IGBT" 1 "OVERTEMPERATURE_PCB" 0 "NOT_DERATED" ;
VAL_ 519 PTC_rightPowerDerating 3 "OVERTEMPERATURE_CORE" 2 "OVERTEMPERATURE_IGBT" 1 "OVERTEMPERATURE_PCB" 0 "NOT_DERATED" ;
VAL_ 519 PTC_ocpEvent 2 "OCP_EVENT_RIGHT_SIDE" 1 "OCP_EVENT_LEFT_SIDE" 0 "NO_OCP_EVENT" ;
VAL_ 519 PTC_tliSource 4 "HV_OVER_VOLTAGE" 3 "OCP" 2 "12_VOLTS" 1 "IGBT_DRIVER" 0 "NO_ERROR" ;
VAL_ 1297 RCM_alertID 118 "a118_imuInPlaneAcceleration" 117 "a117_imuVerticalAcceleration" 116 "a116_imuLateralAcceleration" 115 "a115_imuLinearAcceleration" 114 "a114_imuRollRate" 113 "a113_imuPitchRate" 112 "a112_imuYawRate" 111 "a111_diagnosticsEnabled" 110 "a110_factoryMode" 109 "a109_abuseImmunity" 108 "a108_crashAlgoWakeup" 107 "a107_imuVertAccOffstCompLim" 106 "a106_imuLatAccOffstCompLim" 105 "a105_imuLongAccOffstCompLim" 104 "a104_imuRollR8OffstCompLim" 103 "a103_imuPtchR8OffstCompLim" 102 "a102_imuYawR8OffstCompLim" 101 "a101_idfSystem" 100 "a100_comDIsystemStatus" 99 "a099_comDItorque" 98 "a098_comDIchassisControl" 97 "a097_comDIspeed" 96 "a096_comESPwheelSpeeds" 95 "a095_comESPstatus" 94 "a094_comVCRIGHTStatus" 93 "a093_comVCLEFTStatus" 92 "a092_comDASISF" 91 "a091_comEPAS3PsysStatus" 90 "a090_comPartyBusOff" 89 "a089_comCHCANPH3" 88 "a088_comCHCANPH2" 87 "a087_comCANSilent" 86 "a086_comVINMIA" 85 "a085_comGTWCarConfig" 84 "a084_comTPMSStatus" 83 "a083_comGTWCarState" 82 "a082_comUIodo" 81 "a081_comVCFRONTLVPwr" 80 "a080_comGTWACS" 79 "a079_comOCS1DStatus" 78 "a078_comOCS1PStatus" 77 "a077_comEPBRStatus" 76 "a076_comEPBLStatus" 75 "a075_comCHCANPH6" 74 "a074_comCHCANPH5" 73 "a073_comCHCANPH4" 72 "a072_comUnused" 71 "a071_comCHCANPH9" 70 "a070_comCHCANPH8" 69 "a069_comCHCANPH7" 68 "a068_comChassisBusOff" 67 "a067_comCANInitFailure" 66 "a066_seatBackSw2ndRowLeft" 65 "a065_driverOrientConfigPin" 64 "a064_hardwareCodingPin1" 63 "a063_sbsw2ndRowRight" 62 "a062_alrSwitch" 61 "a061_stpsRight" 60 "a060_stpsLeft" 59 "a059_buckle1stRowRight" 58 "a058_buckle1stRowLeft" 57 "a057_driverOCS" 56 "a056_passengerFrontOCS" 55 "a055_inertialMeasurement" 54 "a054_pressurePedProRight" 53 "a053_pressurePedProLeft" 52 "a052_pressureFrontRtDoor" 51 "a051_pressureFrontLftDoor" 50 "a050_upFrontSensorCenter" 49 "a049_sideAccelCPillarRight" 48 "a048_sideAccelCPillarLeft" 47 "a047_sideAccelBPillarRight" 46 "a046_sideAccelBPillarLeft" 45 "a045_upFrontSensorRight" 44 "a044_upFrontSensorLeft" 43 "a043_ens2Line" 42 "a042_ens1Line" 41 "a041_hoodActuatorLeft" 40 "a040_hoodActuatorRight" 39 "a039_unusedB" 38 "a038_unusedA" 37 "a037_curAB2ndRowRight" 36 "a036_curAB2ndRowLeft" 35 "a035_preten2ndRowRight" 34 "a034_preten2ndRowLeft" 33 "a033_curtainABRight" 32 "a032_curtainABLeft" 31 "a031_frontCenterAirbag" 30 "a030_farSideInboardAirbag" 29 "a029_driverABActiveVent" 28 "a028_sideAB1stRowRight" 27 "a027_sideAB1stRowLeft" 26 "a026_kneeABFrontPassenger" 25 "a025_kneeABDriver" 24 "a024_loadLimiterRightSide" 23 "a023_loadLimiterLeftSide" 22 "a022_pretenLapFrontRight" 21 "a021_pretenLapFrontLeft" 20 "a020_pretenShldFrontRight" 19 "a019_pretenShldrFrontLeft" 18 "a018_passengerActiveVent" 17 "a017_passABStage2" 16 "a016_passABStage1" 15 "a015_driverABStage2" 14 "a014_driverABStage1" 13 "a013_driverOrientation" 12 "a012_vinStorage" 11 "a011_eepromDataLocked" 10 "a010_scmDisabled" 9 "a009_reprogramLimit" 8 "a008_powerSupplyInternal" 7 "a007_powerSupplyExternal" 6 "a006_batteryVoltageRange" 5 "a005_crcError" 4 "a004_internalFault" 3 "a003_warningIndicator" 2 "a002_airbagsNotArmed" 1 "a001_nearDeploy" 0 "a000_crashDetected" ;
VAL_ 1297 RCM_alertState 1 "SET" 0 "CLEARED" ;
VAL_ 1297 RCM_a000_eventArmStatus 1 "ARMED" 0 "UNARMED" ;
VAL_ 1297 RCM_a000_eventFactoryMode 1 "ENABLED" 0 "DISABLED" ;
VAL_ 1297 RCM_a000_eventDiagEnabled 1 "ENABLED" 0 "DISABLED" ;
VAL_ 1297 RCM_a000_eventDriveOrientation 1 "RIGHT_HAND_DRIVE" 0 "LEFT_HAND_DRIVE" ;
VAL_ 1297 RCM_a000_eventIDFsignal 1 "ACTIVE" 0 "NOT_ACTIVE" ;
VAL_ 1297 RCM_a000_eventFrontLeftSeatbelt 1 "LATCHED" 0 "UNLATCHED" ;
VAL_ 1297 RCM_a000_eventFrontRightSeatbelt 1 "LATCHED" 0 "UNLATCHED" ;
VAL_ 1297 RCM_a000_eventDriverBrakeApply 3 "Faulty_SNA" 2 "Driver_applying_brakes" 1 "Not_Applied" 0 "NotInit_orOff" ;
VAL_ 1297 RCM_a000_eventAccelPedalPos 255 "SNA" ;
VAL_ 1297 RCM_a001_eventArmStatus 1 "ARMED" 0 "UNARMED" ;
VAL_ 1297 RCM_a001_eventFactoryMode 1 "ENABLED" 0 "DISABLED" ;
VAL_ 1297 RCM_a001_eventDiagEnabled 1 "ENABLED" 0 "DISABLED" ;
VAL_ 1297 RCM_a001_eventDriveOrientation 1 "RIGHT_HAND_DRIVE" 0 "LEFT_HAND_DRIVE" ;
VAL_ 1297 RCM_a001_eventIDFsignal 1 "ACTIVE" 0 "NOT_ACTIVE" ;
VAL_ 1297 RCM_a001_eventFrontLeftSeatbelt 1 "LATCHED" 0 "UNLATCHED" ;
VAL_ 1297 RCM_a001_eventFrontRightSeatbelt 1 "LATCHED" 0 "UNLATCHED" ;
VAL_ 1297 RCM_a001_eventDriverBrakeApply 3 "Faulty_SNA" 2 "Driver_applying_brakes" 1 "Not_Applied" 0 "NotInit_orOff" ;
VAL_ 1297 RCM_a001_eventAccelPedalPos 255 "SNA" ;
VAL_ 1297 RCM_a002_eventArmStatus 1 "ARMED" 0 "UNARMED" ;
VAL_ 1297 RCM_a002_eventFactoryMode 1 "ENABLED" 0 "DISABLED" ;
VAL_ 1297 RCM_a002_eventDiagEnabled 1 "ENABLED" 0 "DISABLED" ;
VAL_ 1297 RCM_a002_eventDriveOrientation 1 "RIGHT_HAND_DRIVE" 0 "LEFT_HAND_DRIVE" ;
VAL_ 1297 RCM_a002_eventIDFsignal 1 "ACTIVE" 0 "NOT_ACTIVE" ;
VAL_ 1297 RCM_a002_eventFrontLeftSeatbelt 1 "LATCHED" 0 "UNLATCHED" ;
VAL_ 1297 RCM_a002_eventFrontRightSeatbelt 1 "LATCHED" 0 "UNLATCHED" ;
VAL_ 1297 RCM_a002_eventDriverBrakeApply 3 "Faulty_SNA" 2 "Driver_applying_brakes" 1 "Not_Applied" 0 "NotInit_orOff" ;
VAL_ 1297 RCM_a002_eventAccelPedalPos 255 "SNA" ;
VAL_ 1297 RCM_a003_eventArmStatus 1 "ARMED" 0 "UNARMED" ;
VAL_ 1297 RCM_a003_eventFactoryMode 1 "ENABLED" 0 "DISABLED" ;
VAL_ 1297 RCM_a003_eventDiagEnabled 1 "ENABLED" 0 "DISABLED" ;
VAL_ 1297 RCM_a003_eventDriveOrientation 1 "RIGHT_HAND_DRIVE" 0 "LEFT_HAND_DRIVE" ;
VAL_ 1297 RCM_a003_eventIDFsignal 1 "ACTIVE" 0 "NOT_ACTIVE" ;
VAL_ 1297 RCM_a003_eventFrontLeftSeatbelt 1 "LATCHED" 0 "UNLATCHED" ;
VAL_ 1297 RCM_a003_eventFrontRightSeatbelt 1 "LATCHED" 0 "UNLATCHED" ;
VAL_ 1297 RCM_a003_eventDriverBrakeApply 3 "Faulty_SNA" 2 "Driver_applying_brakes" 1 "Not_Applied" 0 "NotInit_orOff" ;
VAL_ 1297 RCM_a003_eventAccelPedalPos 255 "SNA" ;
VAL_ 1297 RCM_a004_eventArmStatus 1 "ARMED" 0 "UNARMED" ;
VAL_ 1297 RCM_a004_eventFactoryMode 1 "ENABLED" 0 "DISABLED" ;
VAL_ 1297 RCM_a004_eventDiagEnabled 1 "ENABLED" 0 "DISABLED" ;
VAL_ 1297 RCM_a004_eventDriveOrientation 1 "RIGHT_HAND_DRIVE" 0 "LEFT_HAND_DRIVE" ;
VAL_ 1297 RCM_a004_eventIDFsignal 1 "ACTIVE" 0 "NOT_ACTIVE" ;
VAL_ 1297 RCM_a004_eventFrontLeftSeatbelt 1 "LATCHED" 0 "UNLATCHED" ;
VAL_ 1297 RCM_a004_eventFrontRightSeatbelt 1 "LATCHED" 0 "UNLATCHED" ;
VAL_ 1297 RCM_a004_eventDriverBrakeApply 3 "Faulty_SNA" 2 "Driver_applying_brakes" 1 "Not_Applied" 0 "NotInit_orOff" ;
VAL_ 1297 RCM_a004_eventAccelPedalPos 255 "SNA" ;
VAL_ 1297 RCM_a005_eventArmStatus 1 "ARMED" 0 "UNARMED" ;
VAL_ 1297 RCM_a005_eventFactoryMode 1 "ENABLED" 0 "DISABLED" ;
VAL_ 1297 RCM_a005_eventDiagEnabled 1 "ENABLED" 0 "DISABLED" ;
VAL_ 1297 RCM_a005_eventDriveOrientation 1 "RIGHT_HAND_DRIVE" 0 "LEFT_HAND_DRIVE" ;
VAL_ 1297 RCM_a005_eventIDFsignal 1 "ACTIVE" 0 "NOT_ACTIVE" ;
VAL_ 1297 RCM_a005_eventFrontLeftSeatbelt 1 "LATCHED" 0 "UNLATCHED" ;
VAL_ 1297 RCM_a005_eventFrontRightSeatbelt 1 "LATCHED" 0 "UNLATCHED" ;
VAL_ 1297 RCM_a005_eventDriverBrakeApply 3 "Faulty_SNA" 2 "Driver_applying_brakes" 1 "Not_Applied" 0 "NotInit_orOff" ;
VAL_ 1297 RCM_a005_eventAccelPedalPos 255 "SNA" ;
VAL_ 1297 RCM_a006_eventArmStatus 1 "ARMED" 0 "UNARMED" ;
VAL_ 1297 RCM_a006_eventFactoryMode 1 "ENABLED" 0 "DISABLED" ;
VAL_ 1297 RCM_a006_eventDiagEnabled 1 "ENABLED" 0 "DISABLED" ;
VAL_ 1297 RCM_a006_eventDriveOrientation 1 "RIGHT_HAND_DRIVE" 0 "LEFT_HAND_DRIVE" ;
VAL_ 1297 RCM_a006_eventIDFsignal 1 "ACTIVE" 0 "NOT_ACTIVE" ;
VAL_ 1297 RCM_a006_eventFrontLeftSeatbelt 1 "LATCHED" 0 "UNLATCHED" ;
VAL_ 1297 RCM_a006_eventFrontRightSeatbelt 1 "LATCHED" 0 "UNLATCHED" ;
VAL_ 1297 RCM_a006_eventDriverBrakeApply 3 "Faulty_SNA" 2 "Driver_applying_brakes" 1 "Not_Applied" 0 "NotInit_orOff" ;
VAL_ 1297 RCM_a006_eventAccelPedalPos 255 "SNA" ;
VAL_ 1297 RCM_a008_eventArmStatus 1 "ARMED" 0 "UNARMED" ;
VAL_ 1297 RCM_a008_eventFactoryMode 1 "ENABLED" 0 "DISABLED" ;
VAL_ 1297 RCM_a008_eventDiagEnabled 1 "ENABLED" 0 "DISABLED" ;
VAL_ 1297 RCM_a008_eventDriveOrientation 1 "RIGHT_HAND_DRIVE" 0 "LEFT_HAND_DRIVE" ;
VAL_ 1297 RCM_a008_eventIDFsignal 1 "ACTIVE" 0 "NOT_ACTIVE" ;
VAL_ 1297 RCM_a008_eventFrontLeftSeatbelt 1 "LATCHED" 0 "UNLATCHED" ;
VAL_ 1297 RCM_a008_eventFrontRightSeatbelt 1 "LATCHED" 0 "UNLATCHED" ;
VAL_ 1297 RCM_a008_eventDriverBrakeApply 3 "Faulty_SNA" 2 "Driver_applying_brakes" 1 "Not_Applied" 0 "NotInit_orOff" ;
VAL_ 1297 RCM_a008_eventAccelPedalPos 255 "SNA" ;
VAL_ 1297 RCM_a009_eventArmStatus 1 "ARMED" 0 "UNARMED" ;
VAL_ 1297 RCM_a009_eventFactoryMode 1 "ENABLED" 0 "DISABLED" ;
VAL_ 1297 RCM_a009_eventDiagEnabled 1 "ENABLED" 0 "DISABLED" ;
VAL_ 1297 RCM_a009_eventDriveOrientation 1 "RIGHT_HAND_DRIVE" 0 "LEFT_HAND_DRIVE" ;
VAL_ 1297 RCM_a009_eventIDFsignal 1 "ACTIVE" 0 "NOT_ACTIVE" ;
VAL_ 1297 RCM_a009_eventFrontLeftSeatbelt 1 "LATCHED" 0 "UNLATCHED" ;
VAL_ 1297 RCM_a009_eventFrontRightSeatbelt 1 "LATCHED" 0 "UNLATCHED" ;
VAL_ 1297 RCM_a009_eventDriverBrakeApply 3 "Faulty_SNA" 2 "Driver_applying_brakes" 1 "Not_Applied" 0 "NotInit_orOff" ;
VAL_ 1297 RCM_a009_eventAccelPedalPos 255 "SNA" ;
VAL_ 1297 RCM_a011_eventArmStatus 1 "ARMED" 0 "UNARMED" ;
VAL_ 1297 RCM_a011_eventFactoryMode 1 "ENABLED" 0 "DISABLED" ;
VAL_ 1297 RCM_a011_eventDiagEnabled 1 "ENABLED" 0 "DISABLED" ;
VAL_ 1297 RCM_a011_eventDriveOrientation 1 "RIGHT_HAND_DRIVE" 0 "LEFT_HAND_DRIVE" ;
VAL_ 1297 RCM_a011_eventIDFsignal 1 "ACTIVE" 0 "NOT_ACTIVE" ;
VAL_ 1297 RCM_a011_eventFrontLeftSeatbelt 1 "LATCHED" 0 "UNLATCHED" ;
VAL_ 1297 RCM_a011_eventFrontRightSeatbelt 1 "LATCHED" 0 "UNLATCHED" ;
VAL_ 1297 RCM_a011_eventDriverBrakeApply 3 "Faulty_SNA" 2 "Driver_applying_brakes" 1 "Not_Applied" 0 "NotInit_orOff" ;
VAL_ 1297 RCM_a011_eventAccelPedalPos 255 "SNA" ;
VAL_ 1297 RCM_a012_eventArmStatus 1 "ARMED" 0 "UNARMED" ;
VAL_ 1297 RCM_a012_eventFactoryMode 1 "ENABLED" 0 "DISABLED" ;
VAL_ 1297 RCM_a012_eventDiagEnabled 1 "ENABLED" 0 "DISABLED" ;
VAL_ 1297 RCM_a012_eventDriveOrientation 1 "RIGHT_HAND_DRIVE" 0 "LEFT_HAND_DRIVE" ;
VAL_ 1297 RCM_a012_eventIDFsignal 1 "ACTIVE" 0 "NOT_ACTIVE" ;
VAL_ 1297 RCM_a012_eventFrontLeftSeatbelt 1 "LATCHED" 0 "UNLATCHED" ;
VAL_ 1297 RCM_a012_eventFrontRightSeatbelt 1 "LATCHED" 0 "UNLATCHED" ;
VAL_ 1297 RCM_a012_eventDriverBrakeApply 3 "Faulty_SNA" 2 "Driver_applying_brakes" 1 "Not_Applied" 0 "NotInit_orOff" ;
VAL_ 1297 RCM_a012_eventAccelPedalPos 255 "SNA" ;
VAL_ 1297 RCM_a013_eventArmStatus 1 "ARMED" 0 "UNARMED" ;
VAL_ 1297 RCM_a013_eventFactoryMode 1 "ENABLED" 0 "DISABLED" ;
VAL_ 1297 RCM_a013_eventDiagEnabled 1 "ENABLED" 0 "DISABLED" ;
VAL_ 1297 RCM_a013_eventDriveOrientation 1 "RIGHT_HAND_DRIVE" 0 "LEFT_HAND_DRIVE" ;
VAL_ 1297 RCM_a013_eventIDFsignal 1 "ACTIVE" 0 "NOT_ACTIVE" ;
VAL_ 1297 RCM_a013_eventFrontLeftSeatbelt 1 "LATCHED" 0 "UNLATCHED" ;
VAL_ 1297 RCM_a013_eventFrontRightSeatbelt 1 "LATCHED" 0 "UNLATCHED" ;
VAL_ 1297 RCM_a013_eventDriverBrakeApply 3 "Faulty_SNA" 2 "Driver_applying_brakes" 1 "Not_Applied" 0 "NotInit_orOff" ;
VAL_ 1297 RCM_a013_eventAccelPedalPos 255 "SNA" ;
VAL_ 1297 RCM_a014_eventArmStatus 1 "ARMED" 0 "UNARMED" ;
VAL_ 1297 RCM_a014_eventFactoryMode 1 "ENABLED" 0 "DISABLED" ;
VAL_ 1297 RCM_a014_eventDiagEnabled 1 "ENABLED" 0 "DISABLED" ;
VAL_ 1297 RCM_a014_eventDriveOrientation 1 "RIGHT_HAND_DRIVE" 0 "LEFT_HAND_DRIVE" ;
VAL_ 1297 RCM_a014_eventIDFsignal 1 "ACTIVE" 0 "NOT_ACTIVE" ;
VAL_ 1297 RCM_a014_eventFrontLeftSeatbelt 1 "LATCHED" 0 "UNLATCHED" ;
VAL_ 1297 RCM_a014_eventFrontRightSeatbelt 1 "LATCHED" 0 "UNLATCHED" ;
VAL_ 1297 RCM_a014_eventDriverBrakeApply 3 "Faulty_SNA" 2 "Driver_applying_brakes" 1 "Not_Applied" 0 "NotInit_orOff" ;
VAL_ 1297 RCM_a014_eventAccelPedalPos 255 "SNA" ;
VAL_ 1297 RCM_a015_eventArmStatus 1 "ARMED" 0 "UNARMED" ;
VAL_ 1297 RCM_a015_eventFactoryMode 1 "ENABLED" 0 "DISABLED" ;
VAL_ 1297 RCM_a015_eventDiagEnabled 1 "ENABLED" 0 "DISABLED" ;
VAL_ 1297 RCM_a015_eventDriveOrientation 1 "RIGHT_HAND_DRIVE" 0 "LEFT_HAND_DRIVE" ;
VAL_ 1297 RCM_a015_eventIDFsignal 1 "ACTIVE" 0 "NOT_ACTIVE" ;
VAL_ 1297 RCM_a015_eventFrontLeftSeatbelt 1 "LATCHED" 0 "UNLATCHED" ;
VAL_ 1297 RCM_a015_eventFrontRightSeatbelt 1 "LATCHED" 0 "UNLATCHED" ;
VAL_ 1297 RCM_a015_eventDriverBrakeApply 3 "Faulty_SNA" 2 "Driver_applying_brakes" 1 "Not_Applied" 0 "NotInit_orOff" ;
VAL_ 1297 RCM_a015_eventAccelPedalPos 255 "SNA" ;
VAL_ 1297 RCM_a016_eventArmStatus 1 "ARMED" 0 "UNARMED" ;
VAL_ 1297 RCM_a016_eventFactoryMode 1 "ENABLED" 0 "DISABLED" ;
VAL_ 1297 RCM_a016_eventDiagEnabled 1 "ENABLED" 0 "DISABLED" ;
VAL_ 1297 RCM_a016_eventDriveOrientation 1 "RIGHT_HAND_DRIVE" 0 "LEFT_HAND_DRIVE" ;
VAL_ 1297 RCM_a016_eventIDFsignal 1 "ACTIVE" 0 "NOT_ACTIVE" ;
VAL_ 1297 RCM_a016_eventFrontLeftSeatbelt 1 "LATCHED" 0 "UNLATCHED" ;
VAL_ 1297 RCM_a016_eventFrontRightSeatbelt 1 "LATCHED" 0 "UNLATCHED" ;
VAL_ 1297 RCM_a016_eventDriverBrakeApply 3 "Faulty_SNA" 2 "Driver_applying_brakes" 1 "Not_Applied" 0 "NotInit_orOff" ;
VAL_ 1297 RCM_a016_eventAccelPedalPos 255 "SNA" ;
VAL_ 1297 RCM_a017_eventArmStatus 1 "ARMED" 0 "UNARMED" ;
VAL_ 1297 RCM_a017_eventFactoryMode 1 "ENABLED" 0 "DISABLED" ;
VAL_ 1297 RCM_a017_eventDiagEnabled 1 "ENABLED" 0 "DISABLED" ;
VAL_ 1297 RCM_a017_eventDriveOrientation 1 "RIGHT_HAND_DRIVE" 0 "LEFT_HAND_DRIVE" ;
VAL_ 1297 RCM_a017_eventIDFsignal 1 "ACTIVE" 0 "NOT_ACTIVE" ;
VAL_ 1297 RCM_a017_eventFrontLeftSeatbelt 1 "LATCHED" 0 "UNLATCHED" ;
VAL_ 1297 RCM_a017_eventFrontRightSeatbelt 1 "LATCHED" 0 "UNLATCHED" ;
VAL_ 1297 RCM_a017_eventDriverBrakeApply 3 "Faulty_SNA" 2 "Driver_applying_brakes" 1 "Not_Applied" 0 "NotInit_orOff" ;
VAL_ 1297 RCM_a017_eventAccelPedalPos 255 "SNA" ;
VAL_ 1297 RCM_a018_eventArmStatus 1 "ARMED" 0 "UNARMED" ;
VAL_ 1297 RCM_a018_eventFactoryMode 1 "ENABLED" 0 "DISABLED" ;
VAL_ 1297 RCM_a018_eventDiagEnabled 1 "ENABLED" 0 "DISABLED" ;
VAL_ 1297 RCM_a018_eventDriveOrientation 1 "RIGHT_HAND_DRIVE" 0 "LEFT_HAND_DRIVE" ;
VAL_ 1297 RCM_a018_eventIDFsignal 1 "ACTIVE" 0 "NOT_ACTIVE" ;
VAL_ 1297 RCM_a018_eventFrontLeftSeatbelt 1 "LATCHED" 0 "UNLATCHED" ;
VAL_ 1297 RCM_a018_eventFrontRightSeatbelt 1 "LATCHED" 0 "UNLATCHED" ;
VAL_ 1297 RCM_a018_eventDriverBrakeApply 3 "Faulty_SNA" 2 "Driver_applying_brakes" 1 "Not_Applied" 0 "NotInit_orOff" ;
VAL_ 1297 RCM_a018_eventAccelPedalPos 255 "SNA" ;
VAL_ 1297 RCM_a019_eventArmStatus 1 "ARMED" 0 "UNARMED" ;
VAL_ 1297 RCM_a019_eventFactoryMode 1 "ENABLED" 0 "DISABLED" ;
VAL_ 1297 RCM_a019_eventDiagEnabled 1 "ENABLED" 0 "DISABLED" ;
VAL_ 1297 RCM_a019_eventDriveOrientation 1 "RIGHT_HAND_DRIVE" 0 "LEFT_HAND_DRIVE" ;
VAL_ 1297 RCM_a019_eventIDFsignal 1 "ACTIVE" 0 "NOT_ACTIVE" ;
VAL_ 1297 RCM_a019_eventFrontLeftSeatbelt 1 "LATCHED" 0 "UNLATCHED" ;
VAL_ 1297 RCM_a019_eventFrontRightSeatbelt 1 "LATCHED" 0 "UNLATCHED" ;
VAL_ 1297 RCM_a019_eventDriverBrakeApply 3 "Faulty_SNA" 2 "Driver_applying_brakes" 1 "Not_Applied" 0 "NotInit_orOff" ;
VAL_ 1297 RCM_a019_eventAccelPedalPos 255 "SNA" ;
VAL_ 1297 RCM_a020_eventArmStatus 1 "ARMED" 0 "UNARMED" ;
VAL_ 1297 RCM_a020_eventFactoryMode 1 "ENABLED" 0 "DISABLED" ;
VAL_ 1297 RCM_a020_eventDiagEnabled 1 "ENABLED" 0 "DISABLED" ;
VAL_ 1297 RCM_a020_eventDriveOrientation 1 "RIGHT_HAND_DRIVE" 0 "LEFT_HAND_DRIVE" ;
VAL_ 1297 RCM_a020_eventIDFsignal 1 "ACTIVE" 0 "NOT_ACTIVE" ;
VAL_ 1297 RCM_a020_eventFrontLeftSeatbelt 1 "LATCHED" 0 "UNLATCHED" ;
VAL_ 1297 RCM_a020_eventFrontRightSeatbelt 1 "LATCHED" 0 "UNLATCHED" ;
VAL_ 1297 RCM_a020_eventDriverBrakeApply 3 "Faulty_SNA" 2 "Driver_applying_brakes" 1 "Not_Applied" 0 "NotInit_orOff" ;
VAL_ 1297 RCM_a020_eventAccelPedalPos 255 "SNA" ;
VAL_ 1297 RCM_a021_eventArmStatus 1 "ARMED" 0 "UNARMED" ;
VAL_ 1297 RCM_a021_eventFactoryMode 1 "ENABLED" 0 "DISABLED" ;
VAL_ 1297 RCM_a021_eventDiagEnabled 1 "ENABLED" 0 "DISABLED" ;
VAL_ 1297 RCM_a021_eventDriveOrientation 1 "RIGHT_HAND_DRIVE" 0 "LEFT_HAND_DRIVE" ;
VAL_ 1297 RCM_a021_eventIDFsignal 1 "ACTIVE" 0 "NOT_ACTIVE" ;
VAL_ 1297 RCM_a021_eventFrontLeftSeatbelt 1 "LATCHED" 0 "UNLATCHED" ;
VAL_ 1297 RCM_a021_eventFrontRightSeatbelt 1 "LATCHED" 0 "UNLATCHED" ;
VAL_ 1297 RCM_a021_eventDriverBrakeApply 3 "Faulty_SNA" 2 "Driver_applying_brakes" 1 "Not_Applied" 0 "NotInit_orOff" ;
VAL_ 1297 RCM_a021_eventAccelPedalPos 255 "SNA" ;
VAL_ 1297 RCM_a022_eventArmStatus 1 "ARMED" 0 "UNARMED" ;
VAL_ 1297 RCM_a022_eventFactoryMode 1 "ENABLED" 0 "DISABLED" ;
VAL_ 1297 RCM_a022_eventDiagEnabled 1 "ENABLED" 0 "DISABLED" ;
VAL_ 1297 RCM_a022_eventDriveOrientation 1 "RIGHT_HAND_DRIVE" 0 "LEFT_HAND_DRIVE" ;
VAL_ 1297 RCM_a022_eventIDFsignal 1 "ACTIVE" 0 "NOT_ACTIVE" ;
VAL_ 1297 RCM_a022_eventFrontLeftSeatbelt 1 "LATCHED" 0 "UNLATCHED" ;
VAL_ 1297 RCM_a022_eventFrontRightSeatbelt 1 "LATCHED" 0 "UNLATCHED" ;
VAL_ 1297 RCM_a022_eventDriverBrakeApply 3 "Faulty_SNA" 2 "Driver_applying_brakes" 1 "Not_Applied" 0 "NotInit_orOff" ;
VAL_ 1297 RCM_a022_eventAccelPedalPos 255 "SNA" ;
VAL_ 1297 RCM_a023_eventArmStatus 1 "ARMED" 0 "UNARMED" ;
VAL_ 1297 RCM_a023_eventFactoryMode 1 "ENABLED" 0 "DISABLED" ;
VAL_ 1297 RCM_a023_eventDiagEnabled 1 "ENABLED" 0 "DISABLED" ;
VAL_ 1297 RCM_a023_eventDriveOrientation 1 "RIGHT_HAND_DRIVE" 0 "LEFT_HAND_DRIVE" ;
VAL_ 1297 RCM_a023_eventIDFsignal 1 "ACTIVE" 0 "NOT_ACTIVE" ;
VAL_ 1297 RCM_a023_eventFrontLeftSeatbelt 1 "LATCHED" 0 "UNLATCHED" ;
VAL_ 1297 RCM_a023_eventFrontRightSeatbelt 1 "LATCHED" 0 "UNLATCHED" ;
VAL_ 1297 RCM_a023_eventDriverBrakeApply 3 "Faulty_SNA" 2 "Driver_applying_brakes" 1 "Not_Applied" 0 "NotInit_orOff" ;
VAL_ 1297 RCM_a023_eventAccelPedalPos 255 "SNA" ;
VAL_ 1297 RCM_a024_eventArmStatus 1 "ARMED" 0 "UNARMED" ;
VAL_ 1297 RCM_a024_eventFactoryMode 1 "ENABLED" 0 "DISABLED" ;
VAL_ 1297 RCM_a024_eventDiagEnabled 1 "ENABLED" 0 "DISABLED" ;
VAL_ 1297 RCM_a024_eventDriveOrientation 1 "RIGHT_HAND_DRIVE" 0 "LEFT_HAND_DRIVE" ;
VAL_ 1297 RCM_a024_eventIDFsignal 1 "ACTIVE" 0 "NOT_ACTIVE" ;
VAL_ 1297 RCM_a024_eventFrontLeftSeatbelt 1 "LATCHED" 0 "UNLATCHED" ;
VAL_ 1297 RCM_a024_eventFrontRightSeatbelt 1 "LATCHED" 0 "UNLATCHED" ;
VAL_ 1297 RCM_a024_eventDriverBrakeApply 3 "Faulty_SNA" 2 "Driver_applying_brakes" 1 "Not_Applied" 0 "NotInit_orOff" ;
VAL_ 1297 RCM_a024_eventAccelPedalPos 255 "SNA" ;
VAL_ 1297 RCM_a025_eventArmStatus 1 "ARMED" 0 "UNARMED" ;
VAL_ 1297 RCM_a025_eventFactoryMode 1 "ENABLED" 0 "DISABLED" ;
VAL_ 1297 RCM_a025_eventDiagEnabled 1 "ENABLED" 0 "DISABLED" ;
VAL_ 1297 RCM_a025_eventDriveOrientation 1 "RIGHT_HAND_DRIVE" 0 "LEFT_HAND_DRIVE" ;
VAL_ 1297 RCM_a025_eventIDFsignal 1 "ACTIVE" 0 "NOT_ACTIVE" ;
VAL_ 1297 RCM_a025_eventFrontLeftSeatbelt 1 "LATCHED" 0 "UNLATCHED" ;
VAL_ 1297 RCM_a025_eventFrontRightSeatbelt 1 "LATCHED" 0 "UNLATCHED" ;
VAL_ 1297 RCM_a025_eventDriverBrakeApply 3 "Faulty_SNA" 2 "Driver_applying_brakes" 1 "Not_Applied" 0 "NotInit_orOff" ;
VAL_ 1297 RCM_a025_eventAccelPedalPos 255 "SNA" ;
VAL_ 1297 RCM_a026_eventArmStatus 1 "ARMED" 0 "UNARMED" ;
VAL_ 1297 RCM_a026_eventFactoryMode 1 "ENABLED" 0 "DISABLED" ;
VAL_ 1297 RCM_a026_eventDiagEnabled 1 "ENABLED" 0 "DISABLED" ;
VAL_ 1297 RCM_a026_eventDriveOrientation 1 "RIGHT_HAND_DRIVE" 0 "LEFT_HAND_DRIVE" ;
VAL_ 1297 RCM_a026_eventIDFsignal 1 "ACTIVE" 0 "NOT_ACTIVE" ;
VAL_ 1297 RCM_a026_eventFrontLeftSeatbelt 1 "LATCHED" 0 "UNLATCHED" ;
VAL_ 1297 RCM_a026_eventFrontRightSeatbelt 1 "LATCHED" 0 "UNLATCHED" ;
VAL_ 1297 RCM_a026_eventDriverBrakeApply 3 "Faulty_SNA" 2 "Driver_applying_brakes" 1 "Not_Applied" 0 "NotInit_orOff" ;
VAL_ 1297 RCM_a026_eventAccelPedalPos 255 "SNA" ;
VAL_ 1297 RCM_a027_eventArmStatus 1 "ARMED" 0 "UNARMED" ;
VAL_ 1297 RCM_a027_eventFactoryMode 1 "ENABLED" 0 "DISABLED" ;
VAL_ 1297 RCM_a027_eventDiagEnabled 1 "ENABLED" 0 "DISABLED" ;
VAL_ 1297 RCM_a027_eventDriveOrientation 1 "RIGHT_HAND_DRIVE" 0 "LEFT_HAND_DRIVE" ;
VAL_ 1297 RCM_a027_eventIDFsignal 1 "ACTIVE" 0 "NOT_ACTIVE" ;
VAL_ 1297 RCM_a027_eventFrontLeftSeatbelt 1 "LATCHED" 0 "UNLATCHED" ;
VAL_ 1297 RCM_a027_eventFrontRightSeatbelt 1 "LATCHED" 0 "UNLATCHED" ;
VAL_ 1297 RCM_a027_eventDriverBrakeApply 3 "Faulty_SNA" 2 "Driver_applying_brakes" 1 "Not_Applied" 0 "NotInit_orOff" ;
VAL_ 1297 RCM_a027_eventAccelPedalPos 255 "SNA" ;
VAL_ 1297 RCM_a028_eventArmStatus 1 "ARMED" 0 "UNARMED" ;
VAL_ 1297 RCM_a028_eventFactoryMode 1 "ENABLED" 0 "DISABLED" ;
VAL_ 1297 RCM_a028_eventDiagEnabled 1 "ENABLED" 0 "DISABLED" ;
VAL_ 1297 RCM_a028_eventDriveOrientation 1 "RIGHT_HAND_DRIVE" 0 "LEFT_HAND_DRIVE" ;
